VERSION "1.11.2"

NS_ :

BS_:

BU_: TCU BRK ESP MCU RDD GP TMS GW KPD1 RDE FNR ECU KPD2 ATSGO ACU IMU1 IMU2 IMU3 IMU4 IMU5 AGW PMI HDOQS EGOQS OBC EEC CBSW EJRH EJLH EPDLT EPDL2 EPDLR EPDLA TRBDZ ECU1 CLST LC510 EGDL JS SMB KPAC ACCU Audio TGU RDRR RDLH RDRH AVM CHMSL CTC SMK EVC MCU2 PHM MC3D AMBLMP RCTGU RDU PT3D XCU can1 can2

BO_ 2566907937 MCU_MCI: 250 MCU
 SG_ RhJoyBtnAux12AddSetConfig : 34|2@1+ (1,0) [0|3] "" Vector__XXX
 SG_ HeavyAttConfig : 32|2@1+ (1,0) [0|3] "" Vector__XXX
 SG_ IdleSpdSetConfig : 30|2@1+ (1,0) [0|3] "" Vector__XXX
 SG_ SdkParallelLiftConfig : 28|2@1+ (1,0) [0|3] "" Vector__XXX
 SG_ RsvforVdk10W : 26|2@1+ (1,0) [0|3] "" Vector__XXX
 SG_ BrkOprgTmLmConfigforVccC4 : 24|2@1+ (1,0) [0|3] "" Vector__XXX
 SG_ ElectStrThmbwhlConfig : 22|2@1+ (1,0) [0|3] "" Vector__XXX
 SG_ EmgStrConfig : 20|2@1+ (1,0) [0|3] "" Vector__XXX
 SG_ LongLifeEgOilFiltConfig : 18|2@1+ (1,0) [0|3] "" Vector__XXX
 SG_ ElecStrJoyThwConf : 16|2@1+ (1,0) [0|3] "" Vector__XXX
 SG_ Dl06EgFuelEffCalbConf : 14|2@1+ (1,0) [0|3] "" Vector__XXX
 SG_ RttThwDirConf : 12|2@1+ (1,0) [0|3] "" Vector__XXX
 SG_ TwThwDirConf : 10|2@1+ (1,0) [0|3] "" Vector__XXX
 SG_ CanPdlIntChngConf : 8|2@1+ (1,0) [0|3] "" Vector__XXX
 SG_ TrvlSwgAlmIntChngConf : 6|2@1+ (1,0) [0|3] "" Vector__XXX
 SG_ OprHrTmpIntChngConf : 4|2@1+ (1,0) [0|3] "" Vector__XXX
 SG_ QckCouplerIntChngConf : 2|2@1+ (1,0) [0|3] "" Vector__XXX
 SG_ ThwSensConf : 1|1@1+ (1,0) [0|1] "" Vector__XXX
 SG_ MultiFuncJoyBtnConf : 0|1@1+ (1,0) [0|1] "" Vector__XXX

BO_ 2566908449 MCU_MWIG: 250 MCU
 SG_ TiltRttArg : 62|2@1+ (1,0) [0|3] "" Vector__XXX
 SG_ GnssSt : 58|4@1+ (1,0) [0|15] "" Vector__XXX
 SG_ VhcStFineSwgTprDsb : 56|2@1+ (1,0) [0|3] "" Vector__XXX
 SG_ IndSymbolMcTprRlsSt : 54|2@1+ (1,0) [0|3] "" Vector__XXX
 SG_ EfenceTgSetSideWallR : 52|2@1- (1,-32000) [-32000|32255] "mm" Vector__XXX
 SG_ EfenceWarnSideWallR : 50|2@1- (1,-32000) [-32000|32255] "mm" Vector__XXX
 SG_ EfenceWarnSideWallL : 48|2@1+ (1,0) [0|3] "" Vector__XXX
 SG_ AssitSwgRh : 46|2@1+ (1,0) [0|3] "" Vector__XXX
 SG_ AssitSwgLh : 44|2@1+ (1,0) [0|3] "" Vector__XXX
 SG_ AssitBck : 42|2@1+ (1,0) [0|3] "" Vector__XXX
 SG_ AssitGrd : 40|2@1+ (1,0) [0|3] "" Vector__XXX
 SG_ SafeWrkSideFar : 36|2@1+ (1,0) [0|3] "" Vector__XXX
 SG_ SafeWrkSideMid : 34|2@1+ (1,0) [0|3] "" Vector__XXX
 SG_ SafeWrkSideNear : 32|2@1+ (1,0) [0|3] "" Vector__XXX
 SG_ SafeWrkFrFar : 28|2@1+ (1,0) [0|3] "" Vector__XXX
 SG_ SafeWrkFrMid : 26|2@1+ (1,0) [0|3] "" Vector__XXX
 SG_ SafeWrkFrNear : 24|2@1+ (1,0) [0|3] "" Vector__XXX
 SG_ FrMvGuidArmOut : 22|2@1+ (1,0) [0|3] "" Vector__XXX
 SG_ FrMvGuidArmIn : 20|2@1+ (1,0) [0|3] "" Vector__XXX
 SG_ FrMvGuidBoomDn : 18|2@1+ (1,0) [0|3] "" Vector__XXX
 SG_ FrMvGuidBoomUp : 16|2@1+ (1,0) [0|3] "" Vector__XXX
 SG_ EfenceTrkWrn : 14|2@1+ (1,0) [0|3] "" Vector__XXX
 SG_ EfenceDzWrn : 12|2@1+ (1,0) [0|3] "" Vector__XXX
 SG_ EfenceCabWrn : 10|2@1+ (1,0) [0|3] "" Vector__XXX
 SG_ EfenceFSwgRhWrn : 8|2@1+ (1,0) [0|3] "" Vector__XXX
 SG_ EfenceFSwgLhWrn : 6|2@1+ (1,0) [0|3] "" Vector__XXX
 SG_ EfenceCeilWrn : 4|2@1+ (1,0) [0|3] "" Vector__XXX
 SG_ EfenceFloorWrn : 2|2@1+ (1,0) [0|3] "" Vector__XXX
 SG_ EfenceWallWrn : 0|2@1+ (1,0) [0|3] "" Vector__XXX

BO_ 2566908705 MCU_TWG: 250 MCU
 SG_ TipOffMnSt : 60|4@1+ (1,0) [0|15] "" Vector__XXX
 SG_ TipOffAstSt : 56|4@1+ (1,0) [0|15] "" Vector__XXX
 SG_ TotWhgCurTrk : 40|16@1+ (2,0) [0|128510] "kg" Vector__XXX
 SG_ BckCntCurTrk : 24|16@1+ (1,0) [0|65535] "count" Vector__XXX
 SG_ WghCntSt : 20|2@1+ (1,0) [0|3] "" Vector__XXX
 SG_ WghSt : 16|4@1+ (1,0) [0|15] "" Vector__XXX
 SG_ RelTmBckWhg : 0|16@1+ (2,0) [0|128510] "kg" Vector__XXX

BO_ 2566908961 MCU_WCPR: 250 MCU
 SG_ EmcvCalbStep : 44|4@1+ (1,0) [0|15] "" Vector__XXX
 SG_ EmcvCalbStage : 40|4@1+ (1,0) [0|15] "" Vector__XXX
 SG_ BckSingleFastCalbStep : 36|4@1+ (1,0) [0|15] "" Vector__XXX
 SG_ BckSingleFastCalbStage : 32|4@1+ (1,0) [0|15] "" Vector__XXX
 SG_ BckSingleSlowCalbStep : 28|4@1+ (1,0) [0|15] "" Vector__XXX
 SG_ BckSingleSlowCalbStage : 24|4@1+ (1,0) [0|15] "" Vector__XXX
 SG_ BckZeroCalbStep : 20|4@1+ (1,0) [0|15] "" Vector__XXX
 SG_ BckZeroCalbStage : 16|4@1+ (1,0) [0|15] "" Vector__XXX
 SG_ FrMultiCalbStep : 12|4@1+ (1,0) [0|15] "" Vector__XXX
 SG_ FrMultiCalbStage : 8|4@1+ (1,0) [0|15] "" Vector__XXX
 SG_ FrSngCalbStep : 4|4@1+ (1,0) [0|15] "" Vector__XXX
 SG_ FrSngCalbStage : 0|4@1+ (1,0) [0|15] "" Vector__XXX

BO_ 2566909217 MCU_WCCV: 250 MCU
 SG_ TgtArmCylSpdUpLmt : 40|8@1+ (0.1,0) [0|20] "mmps" Vector__XXX
 SG_ TgtArmCylSpdLwLmt : 32|8@1+ (0.1,0) [0|20] "mmps" Vector__XXX
 SG_ CurArmCylSpd : 24|8@1+ (0.1,0) [0|20] "mmps" Vector__XXX
 SG_ TgtBoomCylSpdUpLmt : 16|8@1+ (0.1,0) [0|20] "mmps" Vector__XXX
 SG_ TgtBoomCylSpdLwLmt : 8|8@1+ (0.1,0) [0|20] "mmps" Vector__XXX
 SG_ CurBoomCylSpd : 0|8@1+ (0.1,0) [0|20] "mmps" Vector__XXX

BO_ 2566909473 MCU_WCJA: 250 MCU
 SG_ TgtArmJointAngEndPos : 40|8@1- (1,-125) [-125|125] "deg" Vector__XXX
 SG_ TgtArmJointAngStartPos : 32|8@1- (1,-125) [-125|125] "deg" Vector__XXX
 SG_ CurArmJointAng : 24|8@1- (1,-125) [-125|125] "deg" Vector__XXX
 SG_ TgtBoomJointAngEndPos : 16|8@1- (1,-125) [-125|125] "deg" Vector__XXX
 SG_ TgtBoomJointAngStartPos : 8|8@1- (1,-125) [-125|125] "deg" Vector__XXX
 SG_ CurBoomJointAng : 0|8@1- (1,-125) [-125|125] "deg" Vector__XXX

BO_ 2566909729 MCU_LADG: 250 MCU
 SG_ Reach : 48|16@1- (1,-32000) [-32000|32255] "mm" Vector__XXX
 SG_ Hight : 32|16@1- (1,-32000) [-32000|32255] "mm" Vector__XXX
 SG_ RatedLoad : 16|16@1+ (2,0) [0|128510] "kg" Vector__XXX
 SG_ ActLoad : 0|16@1+ (2,0) [0|128510] "kg" Vector__XXX

BO_ 2634018819 TCU_TCUID: 8 TCU

BO_ 2566910241 MCU_ASRG: 250 MCU
 SG_ VhcSpdHhRes : 40|16@1+ (0.00390625,0) [0|250.99609375] "km/h" Vector__XXX
 SG_ SwgSt : 32|2@1+ (1,0) [0|3] "" Vector__XXX
 SG_ VhcSpdFromSpdSs : 24|8@1+ (1,0) [0|250] "kmph" Vector__XXX
 SG_ SwgAng : 0|24@1- (3.0517578125E-05,-250) [-250|252] "deg" Vector__XXX

BO_ 2566910534 EVC_ETCCMVCU: 9 EVC

BO_ 2566912289 MCU_MWHG4: 138 MCU
 SG_ SsOfsRttAng : 1088|16@1- (0.0078125,-200) [-200|301.99] "deg" Vector__XXX
 SG_ ImuSsOfsTrttTiltAng : 1072|16@1- (0.0078125,-200) [-200|301.99] "deg" Vector__XXX
 SG_ TrttBodyDmsnTQ4 : 1056|16@1+ (1,0) [0|64255] "mm" Vector__XXX
 SG_ TrttBodyDmsnDQ4 : 1040|16@1+ (1,0) [0|64255] "mm" Vector__XXX
 SG_ TrttBodyDmsnAngGdt : 1016|24@1- (3.0517578125E-05,-250) [-250|252] "deg" Vector__XXX
 SG_ TrttBodyDmsnDT : 1000|16@1+ (1,0) [0|64255] "mm" Vector__XXX
 SG_ TrttBodyDmsnGT : 984|16@1+ (1,0) [0|64255] "mm" Vector__XXX
 SG_ TrttBodyDmsnDG : 968|16@1+ (1,0) [0|64255] "mm" Vector__XXX
 SG_ TrttBodyDmsnVW : 952|16@1+ (1,0) [0|64255] "mm" Vector__XXX
 SG_ TrttBodyDmsnUV : 936|16@1+ (1,0) [0|64255] "mm" Vector__XXX
 SG_ TrttBodyDmsnTU : 920|16@1+ (1,0) [0|64255] "mm" Vector__XXX
 SG_ TrttBck05DmsnAngVwn : 896|24@1- (3.0517578125E-05,-250) [-250|252] "deg" Vector__XXX
 SG_ TrttBck05DmsnTN : 880|16@1+ (1,0) [0|64255] "mm" Vector__XXX
 SG_ TrttBck05DmsnWN : 864|16@1+ (1,0) [0|64255] "mm" Vector__XXX
 SG_ TrttBck05DmsnWT : 848|16@1+ (1,0) [0|64255] "mm" Vector__XXX
 SG_ TrttBck05DmsnNQ3 : 832|16@1+ (1,0) [0|64255] "mm" Vector__XXX
 SG_ TrttBck05DmsnWQ3 : 816|16@1+ (1,0) [0|64255] "mm" Vector__XXX
 SG_ TrttBck05DmsnNQ2 : 800|16@1+ (1,0) [0|64255] "mm" Vector__XXX
 SG_ TrttBck05DmsnWQ2 : 784|16@1+ (1,0) [0|64255] "mm" Vector__XXX
 SG_ TrttBck05DmsnWidth : 768|16@1+ (1,0) [0|64255] "mm" Vector__XXX
 SG_ TrttBck05DmsnNQ1 : 752|16@1+ (1,0) [0|64255] "mm" Vector__XXX
 SG_ TrttBck05DmsnWQ1 : 736|16@1+ (1,0) [0|64255] "mm" Vector__XXX
 SG_ TrttBck04DmsnAngVwn : 712|24@1- (3.0517578125E-05,-250) [-250|252] "deg" Vector__XXX
 SG_ TrttBck04DmsnTN : 696|16@1+ (1,0) [0|64255] "mm" Vector__XXX
 SG_ TrttBck04DmsnWN : 680|16@1+ (1,0) [0|64255] "mm" Vector__XXX
 SG_ TrttBck04DmsnWT : 664|16@1+ (1,0) [0|64255] "mm" Vector__XXX
 SG_ TrttBck04DmsnNQ3 : 648|16@1+ (1,0) [0|64255] "mm" Vector__XXX
 SG_ TrttBck04DmsnWQ3 : 632|16@1+ (1,0) [0|64255] "mm" Vector__XXX
 SG_ TrttBck04DmsnNQ2 : 616|16@1+ (1,0) [0|64255] "mm" Vector__XXX
 SG_ TrttBck04DmsnWQ2 : 600|16@1+ (1,0) [0|64255] "mm" Vector__XXX
 SG_ TrttBck04DmsnWidth : 584|16@1+ (1,0) [0|64255] "mm" Vector__XXX
 SG_ TrttBck04DmsnNQ1 : 568|16@1+ (1,0) [0|64255] "mm" Vector__XXX
 SG_ TrttBck04DmsnWQ1 : 552|16@1+ (1,0) [0|64255] "mm" Vector__XXX
 SG_ TrttBck03DmsnAngVwn : 528|24@1- (3.0517578125E-05,-250) [-250|252] "deg" Vector__XXX
 SG_ TrttBck03DmsnTN : 512|16@1+ (1,0) [0|64255] "mm" Vector__XXX
 SG_ TrttBck03DmsnWN : 496|16@1+ (1,0) [0|64255] "mm" Vector__XXX
 SG_ TrttBck03DmsnWT : 480|16@1+ (1,0) [0|64255] "mm" Vector__XXX
 SG_ TrttBck03DmsnNQ3 : 464|16@1+ (1,0) [0|64255] "mm" Vector__XXX
 SG_ TrttBck03DmsnWQ3 : 448|16@1+ (1,0) [0|64255] "mm" Vector__XXX
 SG_ TrttBck03DmsnNQ2 : 432|16@1+ (1,0) [0|64255] "mm" Vector__XXX
 SG_ TrttBck03DmsnWQ2 : 416|16@1+ (1,0) [0|64255] "mm" Vector__XXX
 SG_ TrttBck03DmsnWidth : 400|16@1+ (1,0) [0|64255] "mm" Vector__XXX
 SG_ TrttBck03DmsnNQ1 : 384|16@1+ (1,0) [0|64255] "mm" Vector__XXX
 SG_ TrttBck03DmsnWQ1 : 368|16@1+ (1,0) [0|64255] "mm" Vector__XXX
 SG_ TrttBck02DmsnAngVwn : 344|24@1- (3.0517578125E-05,-250) [-250|252] "deg" Vector__XXX
 SG_ TrttBck02DmsnTN : 328|16@1+ (1,0) [0|64255] "mm" Vector__XXX
 SG_ TrttBck02DmsnWN : 312|16@1+ (1,0) [0|64255] "mm" Vector__XXX
 SG_ TrttBck02DmsnWT : 296|16@1+ (1,0) [0|64255] "mm" Vector__XXX
 SG_ TrttBck02DmsnNQ3 : 280|16@1+ (1,0) [0|64255] "mm" Vector__XXX
 SG_ TrttBck02DmsnWQ3 : 264|16@1+ (1,0) [0|64255] "mm" Vector__XXX
 SG_ TrttBck02DmsnNQ2 : 248|16@1+ (1,0) [0|64255] "mm" Vector__XXX
 SG_ TrttBck02DmsnWQ2 : 232|16@1+ (1,0) [0|64255] "mm" Vector__XXX
 SG_ TrttBck02DmsnWidth : 216|16@1+ (1,0) [0|64255] "mm" Vector__XXX
 SG_ TrttBck02DmsnNQ1 : 200|16@1+ (1,0) [0|64255] "mm" Vector__XXX
 SG_ TrttBck02DmsnWQ1 : 184|16@1+ (1,0) [0|64255] "mm" Vector__XXX
 SG_ TrttBck01DmsnAngVwn : 160|24@1- (3.0517578125E-05,-250) [-250|252] "deg" Vector__XXX
 SG_ TrttBck01DmsnTN : 144|16@1+ (1,0) [0|64255] "mm" Vector__XXX
 SG_ TrttBck01DmsnWN : 128|16@1+ (1,0) [0|64255] "mm" Vector__XXX
 SG_ TrttBck01DmsnWT : 112|16@1+ (1,0) [0|64255] "mm" Vector__XXX
 SG_ TrttBck01DmsnNQ3 : 96|16@1+ (1,0) [0|64255] "mm" Vector__XXX
 SG_ TrttBck01DmsnWQ3 : 80|16@1+ (1,0) [0|64255] "mm" Vector__XXX
 SG_ TrttBck01DmsnNQ2 : 64|16@1+ (1,0) [0|64255] "mm" Vector__XXX
 SG_ TrttBck01DmsnWQ2 : 48|16@1+ (1,0) [0|64255] "mm" Vector__XXX
 SG_ TrttBck01DmsnWidth : 32|16@1+ (1,0) [0|64255] "mm" Vector__XXX
 SG_ TrttBck01DmsnNQ1 : 16|16@1+ (1,0) [0|64255] "mm" Vector__XXX
 SG_ TrttBck01DmsnWQ1 : 0|16@1+ (1,0) [0|64255] "mm" Vector__XXX

BO_ 2566912545 MCU_MWHG1: 125 MCU
 SG_ Bck05DmsnAngGdn : 976|24@1- (3.0517578125E-05,-250) [-250|252] "deg" Vector__XXX
 SG_ Bck05DmsnDT : 960|16@1+ (1,0) [0|64255] "mm" Vector__XXX
 SG_ Bck05DmsnNQ3 : 944|16@1+ (1,0) [0|64255] "mm" Vector__XXX
 SG_ Bck05DmsnDQ3 : 928|16@1+ (1,0) [0|64255] "mm" Vector__XXX
 SG_ Bck05DmsnNQ2 : 912|16@1+ (1,0) [0|64255] "mm" Vector__XXX
 SG_ Bck05DmsnDQ2 : 896|16@1+ (1,0) [0|64255] "mm" Vector__XXX
 SG_ Bck05DmsnTN : 880|16@1+ (1,0) [0|64255] "mm" Vector__XXX
 SG_ Bck05DmsnWidth : 864|16@1+ (1,0) [0|64255] "mm" Vector__XXX
 SG_ Bck05DmsnNQ1 : 848|16@1+ (1,0) [0|64255] "mm" Vector__XXX
 SG_ Bck05DmsnDQ1 : 832|16@1+ (1,0) [0|64255] "mm" Vector__XXX
 SG_ Bck05DmsnDN : 816|16@1+ (1,0) [0|64255] "mm" Vector__XXX
 SG_ Bck05DmsnDG : 800|16@1+ (1,0) [0|64255] "mm" Vector__XXX
 SG_ Bck04DmsnAngGdn : 776|24@1- (3.0517578125E-05,-250) [-250|252] "deg" Vector__XXX
 SG_ Bck04DmsnDT : 760|16@1+ (1,0) [0|64255] "mm" Vector__XXX
 SG_ Bck04DmsnNQ3 : 744|16@1+ (1,0) [0|64255] "mm" Vector__XXX
 SG_ Bck04DmsnDQ3 : 728|16@1+ (1,0) [0|64255] "mm" Vector__XXX
 SG_ Bck04DmsnNQ2 : 712|16@1+ (1,0) [0|64255] "mm" Vector__XXX
 SG_ Bck04DmsnDQ2 : 696|16@1+ (1,0) [0|64255] "mm" Vector__XXX
 SG_ Bck04DmsnTN : 680|16@1+ (1,0) [0|64255] "mm" Vector__XXX
 SG_ Bck04DmsnWidth : 664|16@1+ (1,0) [0|64255] "mm" Vector__XXX
 SG_ Bck04DmsnNQ1 : 648|16@1+ (1,0) [0|64255] "mm" Vector__XXX
 SG_ Bck04DmsnDQ1 : 632|16@1+ (1,0) [0|64255] "mm" Vector__XXX
 SG_ Bck04DmsnDN : 616|16@1+ (1,0) [0|64255] "mm" Vector__XXX
 SG_ Bck04DmsnDG : 600|16@1+ (1,0) [0|64255] "mm" Vector__XXX
 SG_ Bck03DmsnAngGdn : 576|24@1- (3.0517578125E-05,-250) [-250|252] "deg" Vector__XXX
 SG_ Bck03DmsnDT : 560|16@1+ (1,0) [0|64255] "mm" Vector__XXX
 SG_ Bck03DmsnNQ3 : 544|16@1+ (1,0) [0|64255] "mm" Vector__XXX
 SG_ Bck03DmsnDQ3 : 528|16@1+ (1,0) [0|64255] "mm" Vector__XXX
 SG_ Bck03DmsnNQ2 : 512|16@1+ (1,0) [0|64255] "mm" Vector__XXX
 SG_ Bck03DmsnDQ2 : 496|16@1+ (1,0) [0|64255] "mm" Vector__XXX
 SG_ Bck03DmsnTN : 480|16@1+ (1,0) [0|64255] "mm" Vector__XXX
 SG_ Bck03DmsnWidth : 464|16@1+ (1,0) [0|64255] "mm" Vector__XXX
 SG_ Bck03DmsnNQ1 : 448|16@1+ (1,0) [0|64255] "mm" Vector__XXX
 SG_ Bck03DmsnDQ1 : 432|16@1+ (1,0) [0|64255] "mm" Vector__XXX
 SG_ Bck03DmsnDN : 416|16@1+ (1,0) [0|64255] "mm" Vector__XXX
 SG_ Bck03DmsnDG : 400|16@1+ (1,0) [0|64255] "mm" Vector__XXX
 SG_ Bck02DmsnAngGdn : 376|24@1- (3.0517578125E-05,-250) [-250|252] "deg" Vector__XXX
 SG_ Bck02DmsnDT : 360|16@1+ (1,0) [0|64255] "mm" Vector__XXX
 SG_ Bck02DmsnNQ3 : 344|16@1+ (1,0) [0|64255] "mm" Vector__XXX
 SG_ Bck02DmsnDQ3 : 328|16@1+ (1,0) [0|64255] "mm" Vector__XXX
 SG_ Bck02DmsnNQ2 : 312|16@1+ (1,0) [0|64255] "mm" Vector__XXX
 SG_ Bck02DmsnDQ2 : 296|16@1+ (1,0) [0|64255] "mm" Vector__XXX
 SG_ Bck02DmsnTN : 280|16@1+ (1,0) [0|64255] "mm" Vector__XXX
 SG_ Bck02DmsnWidth : 264|16@1+ (1,0) [0|64255] "mm" Vector__XXX
 SG_ Bck02DmsnNQ1 : 248|16@1+ (1,0) [0|64255] "mm" Vector__XXX
 SG_ Bck02DmsnDQ1 : 232|16@1+ (1,0) [0|64255] "mm" Vector__XXX
 SG_ Bck02DmsnDN : 216|16@1+ (1,0) [0|64255] "mm" Vector__XXX
 SG_ Bck02DmsnDG : 200|16@1+ (1,0) [0|64255] "mm" Vector__XXX
 SG_ Bck01DmsnAngGdn : 176|24@1- (3.0517578125E-05,-250) [-250|252] "deg" Vector__XXX
 SG_ Bck01DmsnDT : 160|16@1+ (1,0) [0|64255] "mm" Vector__XXX
 SG_ Bck01DmsnNQ3 : 144|16@1+ (1,0) [0|64255] "mm" Vector__XXX
 SG_ Bck01DmsnDQ3 : 128|16@1+ (1,0) [0|64255] "mm" Vector__XXX
 SG_ Bck01DmsnNQ2 : 112|16@1+ (1,0) [0|64255] "mm" Vector__XXX
 SG_ Bck01DmsnDQ2 : 96|16@1+ (1,0) [0|64255] "mm" Vector__XXX
 SG_ Bck01DmsnTN : 80|16@1+ (1,0) [0|64255] "mm" Vector__XXX
 SG_ Bck01DmsnWidth : 64|16@1+ (1,0) [0|64255] "mm" Vector__XXX
 SG_ Bck01DmsnNQ1 : 48|16@1+ (1,0) [0|64255] "mm" Vector__XXX
 SG_ Bck01DmsnDQ1 : 32|16@1+ (1,0) [0|64255] "mm" Vector__XXX
 SG_ Bck01DmsnDN : 16|16@1+ (1,0) [0|64255] "mm" Vector__XXX
 SG_ Bck01DmsnDG : 0|16@1+ (1,0) [0|64255] "mm" Vector__XXX

BO_ 2566912801 MCU_MWHG2: 118 MCU
 SG_ JoyFuncAssnRhBtn14 : 936|8@1+ (1,0) [0|255] "" Vector__XXX
 SG_ JoyFuncAssnRhBtn13 : 928|8@1+ (1,0) [0|255] "" Vector__XXX
 SG_ JoyFuncAssnRhBtn12 : 920|8@1+ (1,0) [0|255] "" Vector__XXX
 SG_ JoyFuncAssnRhBtn11 : 912|8@1+ (1,0) [0|255] "" Vector__XXX
 SG_ JoyFuncAssnLhBtn14 : 904|8@1+ (1,0) [0|255] "" Vector__XXX
 SG_ JoyFuncAssnLhBtn13 : 896|8@1+ (1,0) [0|255] "" Vector__XXX
 SG_ JoyFuncAssnLhBtn12 : 888|8@1+ (1,0) [0|255] "" Vector__XXX
 SG_ JoyFuncAssnLhBtn11 : 880|8@1+ (1,0) [0|255] "" Vector__XXX
 SG_ DacCoordinateSystem : 874|2@1+ (1,0) [0|3] "" Vector__XXX
 SG_ DacAutoMdSelect : 872|2@1+ (1,0) [0|3] "" Vector__XXX
 SG_ CrwTipCalbLen : 856|16@1+ (1,0) [0|64255] "mm" Vector__XXX
 SG_ ImuSsOfsBladeRoll : 832|24@1- (3.0517578125E-05,-250) [-250|252] "deg" Vector__XXX
 SG_ ImuSsOfsBladePch : 808|24@1- (3.0517578125E-05,-250) [-250|252] "deg" Vector__XXX
 SG_ ImuSsOfsCfrmRoll : 784|24@1- (3.0517578125E-05,-250) [-250|252] "deg" Vector__XXX
 SG_ ImuSsOfsCfrmPch : 760|24@1- (3.0517578125E-05,-250) [-250|252] "deg" Vector__XXX
 SG_ BladeTipCalbLen : 744|16@1+ (1,0) [0|64255] "mm" Vector__XXX
 SG_ BladeJointCalbLen : 728|16@1+ (1,0) [0|64255] "mm" Vector__XXX
 SG_ GrdAstPrfDsnDt01PntZ09 : 712|16@1- (1,-32000) [-32000|32255] "mm" Vector__XXX
 SG_ GrdAstPrfDsnDt01PntY09 : 696|16@1- (1,-32000) [-32000|32255] "mm" Vector__XXX
 SG_ GrdAstPrfDsnDt01PntZ08 : 680|16@1- (1,-32000) [-32000|32255] "mm" Vector__XXX
 SG_ GrdAstPrfDsnDt01PntY08 : 664|16@1- (1,-32000) [-32000|32255] "mm" Vector__XXX
 SG_ GrdAstPrfDsnDt01PntZ07 : 648|16@1- (1,-32000) [-32000|32255] "mm" Vector__XXX
 SG_ GrdAstPrfDsnDt01PntY07 : 632|16@1- (1,-32000) [-32000|32255] "mm" Vector__XXX
 SG_ GrdAstPrfDsnDt01PntZ06 : 616|16@1- (1,-32000) [-32000|32255] "mm" Vector__XXX
 SG_ GrdAstPrfDsnDt01PntY06 : 600|16@1- (1,-32000) [-32000|32255] "mm" Vector__XXX
 SG_ GrdAstPrfDsnDt01PntZ05 : 584|16@1- (1,-32000) [-32000|32255] "mm" Vector__XXX
 SG_ GrdAstPrfDsnDt01PntY05 : 568|16@1- (1,-32000) [-32000|32255] "mm" Vector__XXX
 SG_ GrdAstPrfDsnDt01PntZ04 : 552|16@1- (1,-32000) [-32000|32255] "mm" Vector__XXX
 SG_ GrdAstPrfDsnDt01PntY04 : 536|16@1- (1,-32000) [-32000|32255] "mm" Vector__XXX
 SG_ GrdAstPrfDsnDt01PntZ03 : 520|16@1- (1,-32000) [-32000|32255] "mm" Vector__XXX
 SG_ GrdAstPrfDsnDt01PntY03 : 504|16@1- (1,-32000) [-32000|32255] "mm" Vector__XXX
 SG_ GrdAstPrfDsnDt01PntZ02 : 488|16@1- (1,-32000) [-32000|32255] "mm" Vector__XXX
 SG_ GrdAstPrfDsnDt01PntY02 : 472|16@1- (1,-32000) [-32000|32255] "mm" Vector__XXX
 SG_ GrdAstPrfDsnDt01PntZ01 : 456|16@1- (1,-32000) [-32000|32255] "mm" Vector__XXX
 SG_ GrdAstPrfDsnDt01PntY01 : 440|16@1- (1,-32000) [-32000|32255] "mm" Vector__XXX
 SG_ CrossSlopeDsnDt : 424|16@1- (0.0078125,-251) [-251|250.99] "percent" Vector__XXX
 SG_ SlopeDsnDt : 408|16@1- (0.0078125,-251) [-251|250.99] "percent" Vector__XXX
 SG_ DepthDsnDt : 392|16@1+ (1,0) [0|64255] "mm" Vector__XXX
 SG_ JoyFuncAssnRhThw05 : 384|8@1+ (1,0) [0|255] "" Vector__XXX
 SG_ JoyFuncAssnRhThw04 : 376|8@1+ (1,0) [0|255] "" Vector__XXX
 SG_ JoyFuncAssnRhThw03 : 368|8@1+ (1,0) [0|255] "" Vector__XXX
 SG_ JoyFuncAssnRhThw02 : 360|8@1+ (1,0) [0|255] "" Vector__XXX
 SG_ JoyFuncAssnRhThw01 : 352|8@1+ (1,0) [0|255] "" Vector__XXX
 SG_ JoyFuncAssnLhThw05 : 344|8@1+ (1,0) [0|255] "" Vector__XXX
 SG_ JoyFuncAssnLhThw04 : 336|8@1+ (1,0) [0|255] "" Vector__XXX
 SG_ JoyFuncAssnLhThw03 : 328|8@1+ (1,0) [0|255] "" Vector__XXX
 SG_ JoyFuncAssnLhThw02 : 320|8@1+ (1,0) [0|255] "" Vector__XXX
 SG_ JoyFuncAssnLhThw01 : 312|8@1+ (1,0) [0|255] "" Vector__XXX
 SG_ JoyFuncAssnRhBtn10 : 304|8@1+ (1,0) [0|255] "" Vector__XXX
 SG_ JoyFuncAssnRhBtn09 : 296|8@1+ (1,0) [0|255] "" Vector__XXX
 SG_ JoyFuncAssnRhBtn08 : 288|8@1+ (1,0) [0|255] "" Vector__XXX
 SG_ JoyFuncAssnRhBtn07 : 280|8@1+ (1,0) [0|255] "" Vector__XXX
 SG_ JoyFuncAssnRhBtn06 : 272|8@1+ (1,0) [0|255] "" Vector__XXX
 SG_ JoyFuncAssnRhBtn05 : 264|8@1+ (1,0) [0|255] "" Vector__XXX
 SG_ JoyFuncAssnRhBtn04 : 256|8@1+ (1,0) [0|255] "" Vector__XXX
 SG_ JoyFuncAssnRhBtn03 : 248|8@1+ (1,0) [0|255] "" Vector__XXX
 SG_ JoyFuncAssnRhBtn02 : 240|8@1+ (1,0) [0|255] "" Vector__XXX
 SG_ JoyFuncAssnRhBtn01 : 232|8@1+ (1,0) [0|255] "" Vector__XXX
 SG_ JoyFuncAssnLhBtn10 : 224|8@1+ (1,0) [0|255] "" Vector__XXX
 SG_ JoyFuncAssnLhBtn09 : 216|8@1+ (1,0) [0|255] "" Vector__XXX
 SG_ JoyFuncAssnLhBtn08 : 208|8@1+ (1,0) [0|255] "" Vector__XXX
 SG_ JoyFuncAssnLhBtn07 : 200|8@1+ (1,0) [0|255] "" Vector__XXX
 SG_ JoyFuncAssnLhBtn06 : 192|8@1+ (1,0) [0|255] "" Vector__XXX
 SG_ JoyFuncAssnLhBtn05 : 184|8@1+ (1,0) [0|255] "" Vector__XXX
 SG_ JoyFuncAssnLhBtn04 : 176|8@1+ (1,0) [0|255] "" Vector__XXX
 SG_ JoyFuncAssnLhBtn03 : 168|8@1+ (1,0) [0|255] "" Vector__XXX
 SG_ JoyFuncAssnLhBtn02 : 160|8@1+ (1,0) [0|255] "" Vector__XXX
 SG_ JoyFuncAssnLhBtn01 : 152|8@1+ (1,0) [0|255] "" Vector__XXX
 SG_ ImuSsOfsBucket : 128|24@1- (3.0517578125E-05,-250) [-250|252] "deg" Vector__XXX
 SG_ ImuSsOfsArtiArmPch : 104|24@1- (3.0517578125E-05,-250) [-250|252] "deg" Vector__XXX
 SG_ ImuSsOfsArmPch : 80|24@1- (3.0517578125E-05,-250) [-250|252] "deg" Vector__XXX
 SG_ ImuSsOfsBoomPch : 56|24@1- (3.0517578125E-05,-250) [-250|252] "deg" Vector__XXX
 SG_ ImuSsOfsBodyRoll : 32|24@1- (3.0517578125E-05,-250) [-250|252] "deg" Vector__XXX
 SG_ ImuSsOfsBodyPch : 8|24@1- (3.0517578125E-05,-250) [-250|252] "deg" Vector__XXX
 SG_ SelectedBucketNo : 0|8@1+ (1,0) [0|255] "" Vector__XXX

BO_ 2566913057 MCU_MWHG3: 67 MCU
 SG_ MaterialName : 336|200@1+ (1,0) [0|255] "ASCII" Vector__XXX
 SG_ TrkName : 136|200@1+ (1,0) [0|255] "ASCII" Vector__XXX
 SG_ BchmkZOfs : 120|16@1- (1,-32000) [-32000|32255] "mm" Vector__XXX
 SG_ BchmkYOfs : 104|16@1- (1,-32000) [-32000|32255] "mm" Vector__XXX
 SG_ BchmkXOfs : 88|16@1- (1,-32000) [-32000|32255] "mm" Vector__XXX
 SG_ TrkCount : 72|16@1+ (1,0) [0|64255] "" Vector__XXX
 SG_ SelMaterialDensity : 56|16@1+ (1,0) [0|64255] "kgpm3" Vector__XXX
 SG_ SelTrkTgtWgh : 40|16@1+ (2,0) [0|128510] "kg" Vector__XXX
 SG_ BckRefPnt : 38|2@1+ (1,0) [0|3] "" Vector__XXX
 SG_ ArtiBoomDmsnOpt : 35|3@1+ (1,0) [0|7] "" Vector__XXX
 SG_ ArmDmsnOpt : 32|3@1+ (1,0) [0|7] "" Vector__XXX
 SG_ BoomDmsnOpt : 27|3@1+ (1,0) [0|7] "" Vector__XXX
 SG_ SetExcessiveDigPrt : 24|2@1+ (1,0) [0|3] "" Vector__XXX
 SG_ GrdAstMd : 20|4@1+ (1,0) [0|15] "" Vector__XXX
 SG_ GrdAstAccuracy : 16|4@1+ (1,0) [0|15] "" Vector__XXX
 SG_ TrkShoeWidth : 8|8@1+ (10,0) [0|2500] "mm" Vector__XXX

BO_ 2566913313 MCU_MWTSV: 24 MCU
 SG_ EfenceTgSetSideWallR : 176|16@1- (1,-32000) [-32000|32255] "" Vector__XXX
 SG_ EfenceTgSetSideWallL : 160|16@1- (1,-32000) [-32000|32255] "" Vector__XXX
 SG_ EfenceTgSetCabin : 144|16@1- (1,-32000) [-32000|32255] "mm" Vector__XXX
 SG_ SwgAstAngTgtSetSwgLh : 120|24@1- (3.0517578125E-05,-250) [-250|252] "deg" Vector__XXX
 SG_ SwgAstAngTgtSetSwgRh : 96|24@1- (3.0517578125E-05,-250) [-250|252] "deg" Vector__XXX
 SG_ EfenceTgtSetSwgRh : 72|24@1- (3.0517578125E-05,-250) [-250|252] "deg" Vector__XXX
 SG_ EfenceTgtSetSwgLh : 48|24@1- (3.0517578125E-05,-250) [-250|252] "deg" Vector__XXX
 SG_ EfenceTgtSetCeil : 32|16@1- (1,-32000) [-32000|32255] "mm" Vector__XXX
 SG_ EfenceTgtSetFloor : 16|16@1- (1,-32000) [-32000|32255] "mm" Vector__XXX
 SG_ EfenceTgtSetWall : 0|16@1- (1,-32000) [-32000|32255] "mm" Vector__XXX

BO_ 2566913569 MCU_MTSI: 88 MCU
 SG_ CompanyName : 504|200@1+ (1,0) [0|1.60693804425899E+60] "ASCII" Vector__XXX
 SG_ TgWghofCurTrk : 488|16@1+ (2,0) [0|128510] "kg" Vector__XXX
 SG_ TrkCntFinalTm : 456|32@1+ (1,0) [0|4211081215] "s" Vector__XXX
 SG_ MaterialLoadSt : 448|1@1+ (1,0) [0|1] "" Vector__XXX
 SG_ TotWghCurTrk : 432|16@1+ (2,0) [0|128510] "kg" Vector__XXX
 SG_ BckCntCurTrk : 416|16@1+ (1,0) [0|65535] "count" Vector__XXX
 SG_ MtrDensity : 400|16@1+ (1,0) [0|64255] "kgpm3" Vector__XXX
 SG_ MtrName : 200|200@1+ (1,0) [0|255] "ASCII" Vector__XXX
 SG_ TrkName : 0|200@1+ (1,0) [0|1.60693804425899E+60] "ASCII" Vector__XXX

BO_ 2566913825 MCU_MAWI: 250 MCU
 SG_ TotAcmtWgh : 32|32@1+ (2,0) [0|8589934590] "kg" Vector__XXX
 SG_ TotAcmtBckCnt : 0|24@1+ (1,0) [0|16777215] "count" Vector__XXX

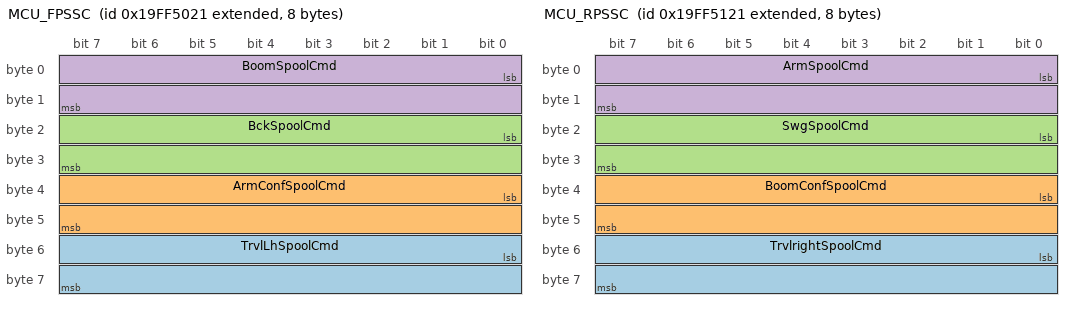
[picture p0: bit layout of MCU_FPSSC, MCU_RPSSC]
BO_ 2583646241 MCU_FPSSC: 8 MCU
 SG_ TrvlLhSpoolCmd : 48|16@1- (0.01,-20) [-20|20] "mm" Vector__XXX
 SG_ ArmConfSpoolCmd : 32|16@1- (0.01,-20) [-20|20] "mm" Vector__XXX
 SG_ BckSpoolCmd : 16|16@1- (0.01,-20) [-20|20] "mm" Vector__XXX
 SG_ BoomSpoolCmd : 0|16@1- (0.01,-20) [-20|20] "mm" Vector__XXX

BO_ 2583646497 MCU_RPSSC: 8 MCU
 SG_ TrvlrightSpoolCmd : 48|16@1- (0.01,-20) [-20|20] "mm" Vector__XXX
 SG_ BoomConfSpoolCmd : 32|16@1- (0.01,-20) [-20|20] "mm" Vector__XXX
 SG_ SwgSpoolCmd : 16|16@1- (0.01,-20) [-20|20] "mm" Vector__XXX
 SG_ ArmSpoolCmd : 0|16@1- (0.01,-20) [-20|20] "mm" Vector__XXX

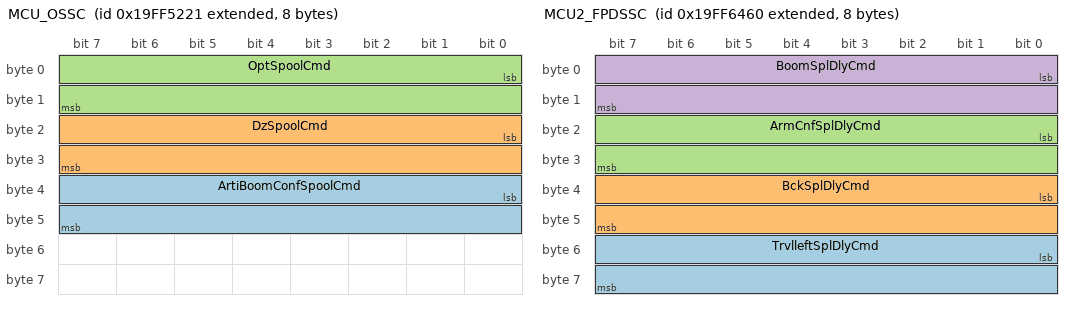
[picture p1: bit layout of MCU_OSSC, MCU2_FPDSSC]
BO_ 2583646753 MCU_OSSC: 8 MCU
 SG_ ArtiBoomConfSpoolCmd : 32|16@1- (0.01,-20) [-20|20] "mm" Vector__XXX
 SG_ DzSpoolCmd : 16|16@1- (0.01,-20) [-20|20] "mm" Vector__XXX
 SG_ OptSpoolCmd : 0|16@1- (0.01,-20) [-20|20] "mm" Vector__XXX

BO_ 2583651424 MCU2_FPDSSC: 8 MCU2
 SG_ TrvlleftSplDlyCmd : 48|16@1- (0.01,-20) [-20|20] "mm" Vector__XXX
 SG_ BckSplDlyCmd : 32|16@1- (0.01,-20) [-20|20] "mm" Vector__XXX
 SG_ ArmCnfSplDlyCmd : 16|16@1- (0.01,-20) [-20|20] "mm" Vector__XXX
 SG_ BoomSplDlyCmd : 0|16@1- (0.01,-20) [-20|20] "mm" Vector__XXX

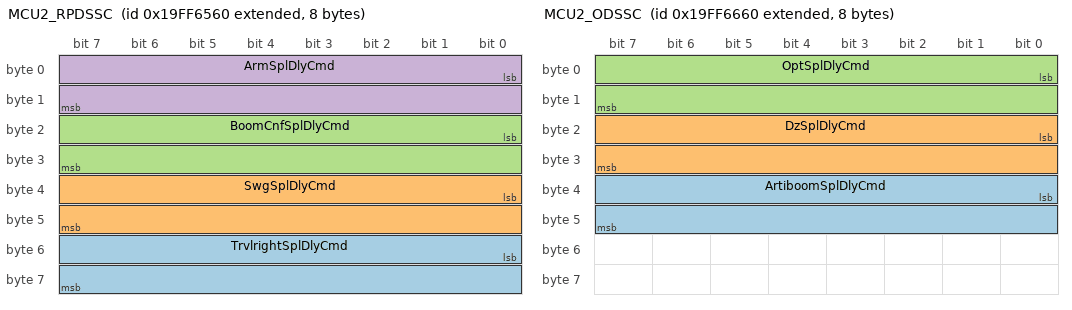
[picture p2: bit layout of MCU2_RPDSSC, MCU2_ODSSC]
BO_ 2583651680 MCU2_RPDSSC: 8 MCU2
 SG_ TrvlrightSplDlyCmd : 48|16@1- (0.01,-20) [-20|20] "mm" Vector__XXX
 SG_ SwgSplDlyCmd : 32|16@1- (0.01,-20) [-20|20] "mm" Vector__XXX
 SG_ BoomCnfSplDlyCmd : 16|16@1- (0.01,-20) [-20|20] "mm" Vector__XXX
 SG_ ArmSplDlyCmd : 0|16@1- (0.01,-20) [-20|20] "mm" Vector__XXX

BO_ 2583651936 MCU2_ODSSC: 8 MCU2
 SG_ ArtiboomSplDlyCmd : 32|16@1- (0.01,-20) [-20|20] "mm" Vector__XXX
 SG_ DzSplDlyCmd : 16|16@1- (0.01,-20) [-20|20] "mm" Vector__XXX
 SG_ OptSplDlyCmd : 0|16@1- (0.01,-20) [-20|20] "mm" Vector__XXX

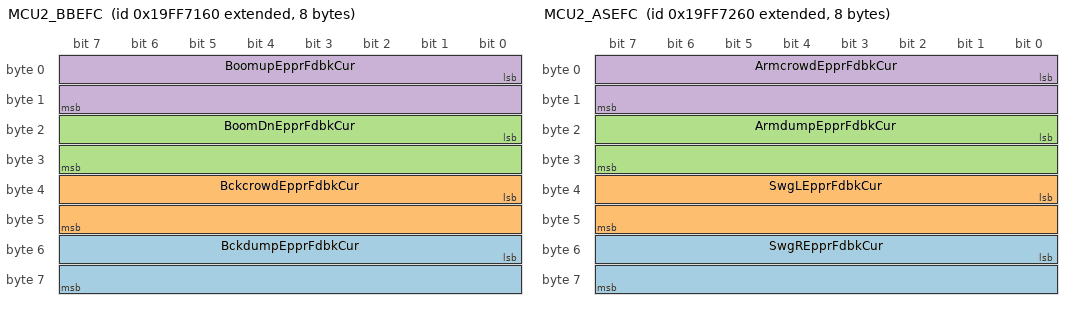
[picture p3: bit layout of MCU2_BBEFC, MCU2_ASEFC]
BO_ 2583654752 MCU2_BBEFC: 8 MCU2
 SG_ BckdumpEpprFdbkCur : 48|16@1+ (1,0) [0|1000] "mA" Vector__XXX
 SG_ BckcrowdEpprFdbkCur : 32|16@1+ (1,0) [0|1000] "mA" Vector__XXX
 SG_ BoomDnEpprFdbkCur : 16|16@1+ (1,0) [0|1000] "mA" Vector__XXX
 SG_ BoomupEpprFdbkCur : 0|16@1+ (1,0) [0|1000] "mA" Vector__XXX

BO_ 2583655008 MCU2_ASEFC: 8 MCU2
 SG_ SwgREpprFdbkCur : 48|16@1+ (1,0) [0|1000] "mA" Vector__XXX
 SG_ SwgLEpprFdbkCur : 32|16@1+ (1,0) [0|1000] "mA" Vector__XXX
 SG_ ArmdumpEpprFdbkCur : 16|16@1+ (1,0) [0|1000] "mA" Vector__XXX
 SG_ ArmcrowdEpprFdbkCur : 0|16@1+ (1,0) [0|1000] "mA" Vector__XXX

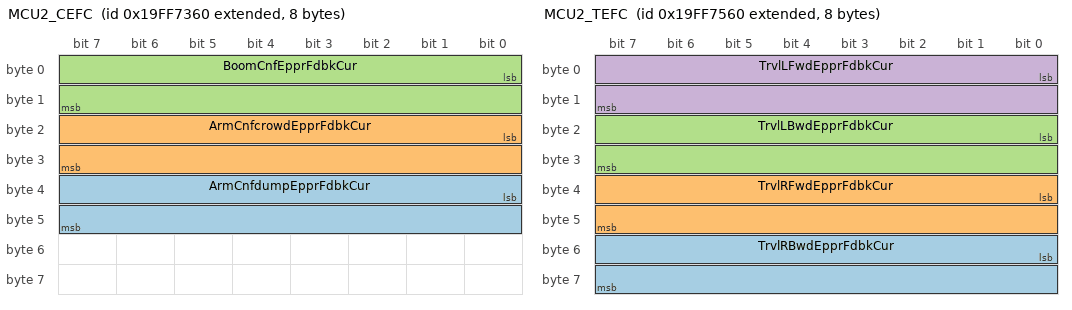
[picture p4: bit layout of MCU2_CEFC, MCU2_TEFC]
BO_ 2583655264 MCU2_CEFC: 8 MCU2
 SG_ ArmCnfdumpEpprFdbkCur : 32|16@1+ (1,0) [0|1000] "mA" Vector__XXX
 SG_ ArmCnfcrowdEpprFdbkCur : 16|16@1+ (1,0) [0|1000] "mA" Vector__XXX
 SG_ BoomCnfEpprFdbkCur : 0|16@1+ (1,0) [0|1000] "mA" Vector__XXX

BO_ 2583655520 MCU2_OEFC: 8 MCU2
 SG_ OpenEpprFdbkCur : 16|16@1+ (1,0) [0|1000] "mA" Vector__XXX
 SG_ CloseEpprFdbkCur : 0|16@1+ (1,0) [0|1000] "mA" Vector__XXX

BO_ 2583655776 MCU2_TEFC: 8 MCU2
 SG_ TrvlRBwdEpprFdbkCur : 48|16@1+ (1,0) [0|1000] "mA" Vector__XXX
 SG_ TrvlRFwdEpprFdbkCur : 32|16@1+ (1,0) [0|1000] "mA" Vector__XXX
 SG_ TrvlLBwdEpprFdbkCur : 16|16@1+ (1,0) [0|1000] "mA" Vector__XXX
 SG_ TrvlLFwdEpprFdbkCur : 0|16@1+ (1,0) [0|1000] "mA" Vector__XXX

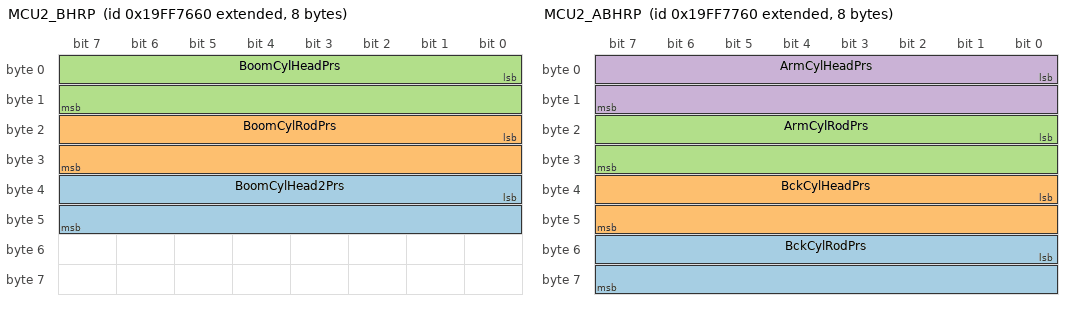
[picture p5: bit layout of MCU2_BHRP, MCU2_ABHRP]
BO_ 2583656032 MCU2_BHRP: 8 MCU2
 SG_ BoomCylHead2Prs : 32|16@1+ (0.25,0) [0|500] "bar" Vector__XXX
 SG_ BoomCylRodPrs : 16|16@1+ (0.25,0) [0|500] "bar" Vector__XXX
 SG_ BoomCylHeadPrs : 0|16@1+ (0.25,0) [0|500] "bar" Vector__XXX

BO_ 2583656288 MCU2_ABHRP: 8 MCU2
 SG_ BckCylRodPrs : 48|16@1+ (0.25,0) [0|500] "bar" Vector__XXX
 SG_ BckCylHeadPrs : 32|16@1+ (0.25,0) [0|500] "bar" Vector__XXX
 SG_ ArmCylRodPrs : 16|16@1+ (0.25,0) [0|500] "bar" Vector__XXX
 SG_ ArmCylHeadPrs : 0|16@1+ (0.25,0) [0|500] "bar" Vector__XXX

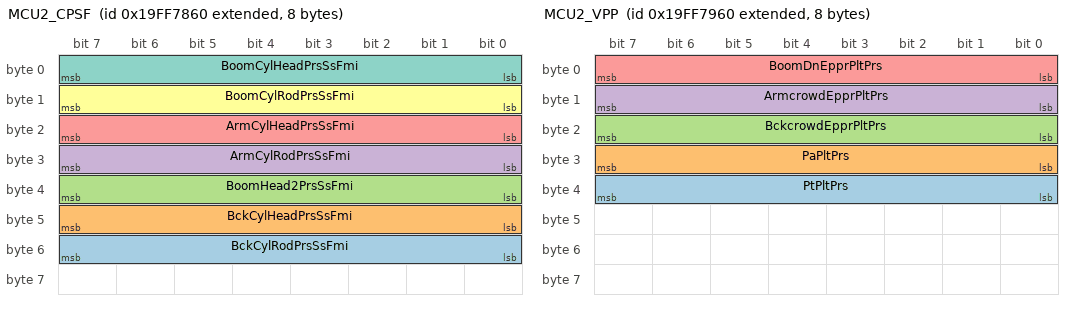
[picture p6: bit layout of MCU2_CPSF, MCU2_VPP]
BO_ 2583656544 MCU2_CPSF: 8 MCU2
 SG_ BckCylRodPrsSsFmi : 48|8@1+ (1,0) [0|255] "" Vector__XXX
 SG_ BckCylHeadPrsSsFmi : 40|8@1+ (1,0) [0|255] "" Vector__XXX
 SG_ BoomHead2PrsSsFmi : 32|8@1+ (1,0) [0|255] "" Vector__XXX
 SG_ ArmCylRodPrsSsFmi : 24|8@1+ (1,0) [0|255] "" Vector__XXX
 SG_ ArmCylHeadPrsSsFmi : 16|8@1+ (1,0) [0|255] "" Vector__XXX
 SG_ BoomCylRodPrsSsFmi : 8|8@1+ (1,0) [0|255] "" Vector__XXX
 SG_ BoomCylHeadPrsSsFmi : 0|8@1+ (1,0) [0|255] "" Vector__XXX

BO_ 2583656800 MCU2_VPP: 8 MCU2
 SG_ PtPltPrs : 32|8@1+ (0.25,0) [0|50] "bar" Vector__XXX
 SG_ PaPltPrs : 24|8@1+ (0.25,0) [0|50] "bar" Vector__XXX
 SG_ BckcrowdEpprPltPrs : 16|8@1+ (0.25,0) [0|50] "bar" Vector__XXX
 SG_ ArmcrowdEpprPltPrs : 8|8@1+ (0.25,0) [0|50] "bar" Vector__XXX
 SG_ BoomDnEpprPltPrs : 0|8@1+ (0.25,0) [0|50] "bar" Vector__XXX

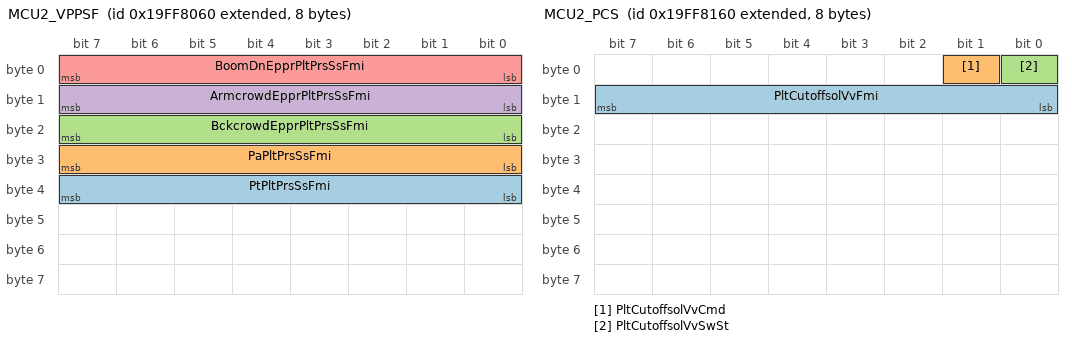
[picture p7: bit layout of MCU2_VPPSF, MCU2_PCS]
BO_ 2583658592 MCU2_VPPSF: 8 MCU2
 SG_ PtPltPrsSsFmi : 32|8@1+ (1,0) [0|255] "" Vector__XXX
 SG_ PaPltPrsSsFmi : 24|8@1+ (1,0) [0|255] "" Vector__XXX
 SG_ BckcrowdEpprPltPrsSsFmi : 16|8@1+ (1,0) [0|255] "" Vector__XXX
 SG_ ArmcrowdEpprPltPrsSsFmi : 8|8@1+ (1,0) [0|255] "" Vector__XXX
 SG_ BoomDnEpprPltPrsSsFmi : 0|8@1+ (1,0) [0|255] "" Vector__XXX

BO_ 2583658848 MCU2_PCS: 8 MCU2
 SG_ PltCutoffsolVvFmi : 8|8@1+ (1,0) [0|255] "" Vector__XXX
 SG_ PltCutoffsolVvCmd : 1|1@1+ (1,0) [0|1] "" Vector__XXX
 SG_ PltCutoffsolVvSwSt : 0|1@1+ (1,0) [0|1] "" Vector__XXX

BO_ 2583667233 MCU_CBCC: 8 MCU
 SG_ Bypass2EpprCmd : 42|10@1+ (1,0) [0|1023] "mA" Vector__XXX
 SG_ Bypass1EpprCmd : 32|10@1+ (1,0) [0|1023] "mA" Vector__XXX

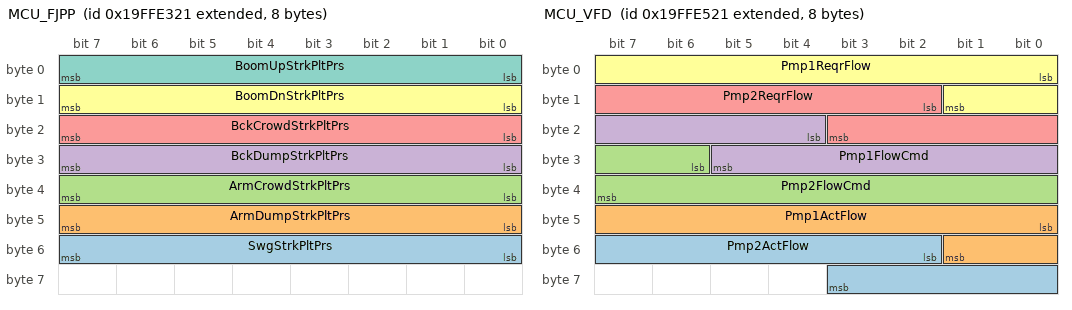
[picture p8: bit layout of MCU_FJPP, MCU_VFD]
BO_ 2583683873 MCU_FJPP: 8 MCU
 SG_ SwgStrkPltPrs : 48|8@1+ (0.25,0) [0|50] "bar" Vector__XXX
 SG_ ArmDumpStrkPltPrs : 40|8@1+ (0.25,0) [0|50] "bar" Vector__XXX
 SG_ ArmCrowdStrkPltPrs : 32|8@1+ (0.25,0) [0|50] "bar" Vector__XXX
 SG_ BckDumpStrkPltPrs : 24|8@1+ (0.25,0) [0|50] "bar" Vector__XXX
 SG_ BckCrowdStrkPltPrs : 16|8@1+ (0.25,0) [0|50] "bar" Vector__XXX
 SG_ BoomDnStrkPltPrs : 8|8@1+ (0.25,0) [0|50] "bar" Vector__XXX
 SG_ BoomUpStrkPltPrs : 0|8@1+ (0.25,0) [0|50] "bar" Vector__XXX

BO_ 2583684129 MCU_TJPP: 8 MCU
 SG_ TrvlRStrkPltPrs : 8|8@1+ (0.25,0) [0|50] "bar" Vector__XXX
 SG_ TrvlLStrkPltPrs : 0|8@1+ (0.25,0) [0|50] "bar" Vector__XXX

BO_ 2583684385 MCU_VFD: 8 MCU
 SG_ Pmp2ActFlow : 50|10@1+ (1,0) [0|1023] "ccps" Vector__XXX
 SG_ Pmp1ActFlow : 40|10@1+ (1,0) [0|1023] "ccps" Vector__XXX
 SG_ Pmp2FlowCmd : 30|10@1+ (1,0) [0|1023] "ccps" Vector__XXX
 SG_ Pmp1FlowCmd : 20|10@1+ (1,0) [0|1023] "ccps" Vector__XXX
 SG_ Pmp2ReqrFlow : 10|10@1+ (1,0) [0|1023] "ccps" Vector__XXX
 SG_ Pmp1ReqrFlow : 0|10@1+ (1,0) [0|1023] "ccps" Vector__XXX

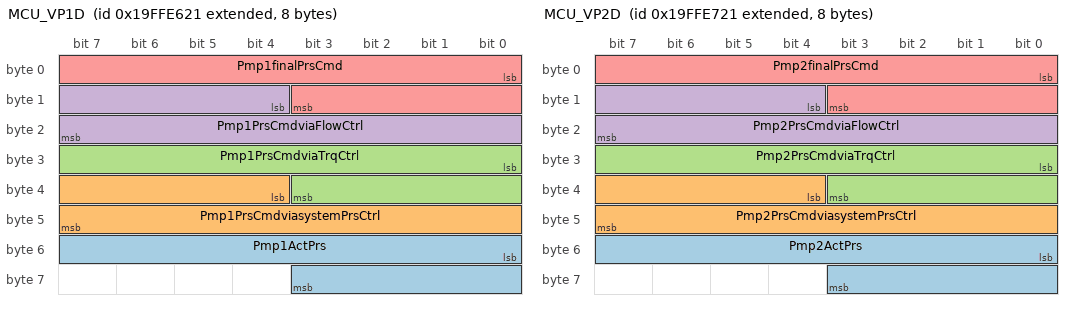
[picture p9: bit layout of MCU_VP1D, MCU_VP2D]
BO_ 2583684641 MCU_VP1D: 8 MCU
 SG_ Pmp1ActPrs : 48|12@1+ (1,0) [0|4095] "bar" Vector__XXX
 SG_ Pmp1PrsCmdviasystemPrsCtrl : 36|12@1+ (1,0) [0|4095] "bar" Vector__XXX
 SG_ Pmp1PrsCmdviaTrqCtrl : 24|12@1+ (1,0) [0|4095] "bar" Vector__XXX
 SG_ Pmp1PrsCmdviaFlowCtrl : 12|12@1+ (1,0) [0|4095] "bar" Vector__XXX
 SG_ Pmp1finalPrsCmd : 0|12@1+ (1,0) [0|4095] "bar" Vector__XXX

BO_ 2583684897 MCU_VP2D: 8 MCU
 SG_ Pmp2ActPrs : 48|12@1+ (1,0) [0|4095] "bar" Vector__XXX
 SG_ Pmp2PrsCmdviasystemPrsCtrl : 36|12@1+ (1,0) [0|4095] "bar" Vector__XXX
 SG_ Pmp2PrsCmdviaTrqCtrl : 24|12@1+ (1,0) [0|4095] "bar" Vector__XXX
 SG_ Pmp2PrsCmdviaFlowCtrl : 12|12@1+ (1,0) [0|4095] "bar" Vector__XXX
 SG_ Pmp2finalPrsCmd : 0|12@1+ (1,0) [0|4095] "bar" Vector__XXX

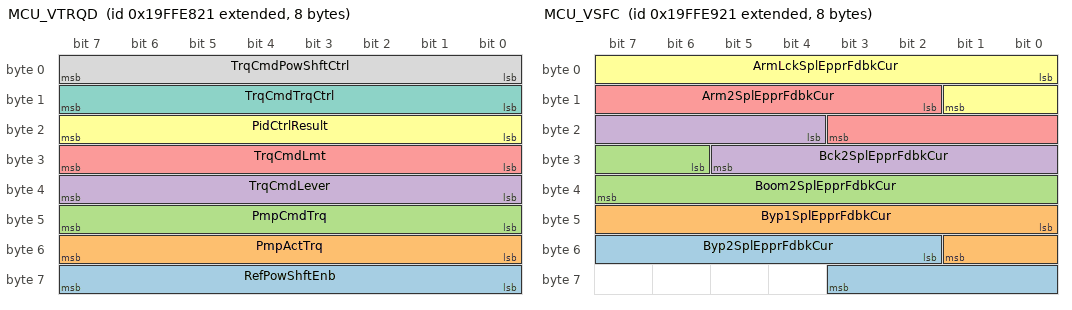
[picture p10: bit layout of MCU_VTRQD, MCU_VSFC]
BO_ 2583685153 MCU_VTRQD: 8 MCU
 SG_ RefPowShftEnb : 56|8@1+ (8,800) [800|2000] "Rpm" Vector__XXX
 SG_ PmpActTrq : 48|8@1+ (0.5,0) [0|127.5] "percent" Vector__XXX
 SG_ PmpCmdTrq : 40|8@1+ (0.5,0) [0|127.5] "percent" Vector__XXX
 SG_ TrqCmdLever : 32|8@1+ (0.5,0) [0|127.5] "percent" Vector__XXX
 SG_ TrqCmdLmt : 24|8@1+ (0.5,0) [0|127.5] "percent" Vector__XXX
 SG_ PidCtrlResult : 16|8@1- (-0.5,0) [-125|125] "percent" Vector__XXX
 SG_ TrqCmdTrqCtrl : 8|8@1+ (0.5,0) [0|127.5] "percent" Vector__XXX
 SG_ TrqCmdPowShftCtrl : 0|8@1+ (0.5,0) [0|127.5] "percent" Vector__XXX

BO_ 2583685409 MCU_VSFC: 8 MCU
 SG_ Byp2SplEpprFdbkCur : 50|10@1+ (1,0) [0|1000] "mA" Vector__XXX
 SG_ Byp1SplEpprFdbkCur : 40|10@1+ (1,0) [0|1000] "mA" Vector__XXX
 SG_ Boom2SplEpprFdbkCur : 30|10@1+ (1,0) [0|1000] "mA" Vector__XXX
 SG_ Bck2SplEpprFdbkCur : 20|10@1+ (1,0) [0|1000] "mA" Vector__XXX
 SG_ Arm2SplEpprFdbkCur : 10|10@1+ (1,0) [0|1000] "mA" Vector__XXX
 SG_ ArmLckSplEpprFdbkCur : 0|10@1+ (1,0) [0|1000] "mA" Vector__XXX

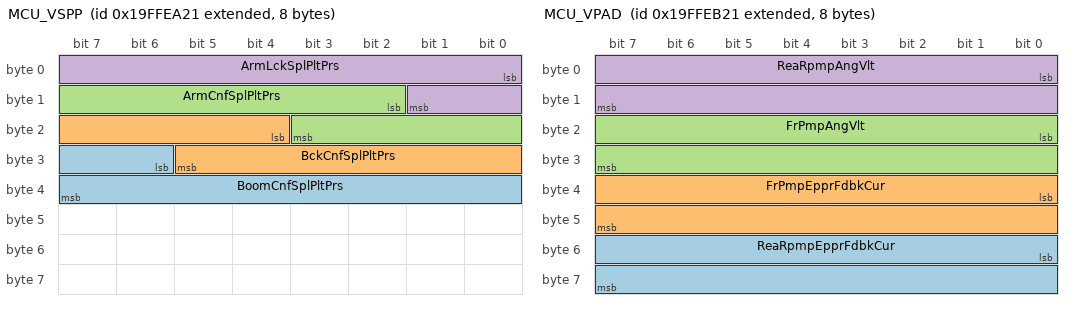
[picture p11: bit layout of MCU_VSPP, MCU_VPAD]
BO_ 2583685665 MCU_VSPP: 8 MCU
 SG_ BoomCnfSplPltPrs : 30|10@1+ (0.0625,0) [0|50] "bar" Vector__XXX
 SG_ BckCnfSplPltPrs : 20|10@1+ (0.0625,0) [0|50] "bar" Vector__XXX
 SG_ ArmCnfSplPltPrs : 10|10@1+ (0.0625,0) [0|50] "bar" Vector__XXX
 SG_ ArmLckSplPltPrs : 0|10@1+ (0.0625,0) [0|50] "bar" Vector__XXX

BO_ 2583685921 MCU_VPAD: 8 MCU
 SG_ ReaRpmpEpprFdbkCur : 48|16@1+ (1,0) [0|1000] "mA" Vector__XXX
 SG_ FrPmpEpprFdbkCur : 32|16@1+ (1,0) [0|1000] "mA" Vector__XXX
 SG_ FrPmpAngVlt : 16|16@1+ (1,0) [0|10000] "mV" Vector__XXX
 SG_ ReaRpmpAngVlt : 0|16@1+ (1,0) [0|10000] "mV" Vector__XXX

BO_ 2583686177 MCU_VTD: 8 MCU
 SG_ FrPmpAngVlt : 16|16@1- (1,-40) [-40|250] "Celsius" Vector__XXX
 SG_ OilFanEpprFdbkCur : 0|16@1+ (1,0) [0|1000] "mA" Vector__XXX

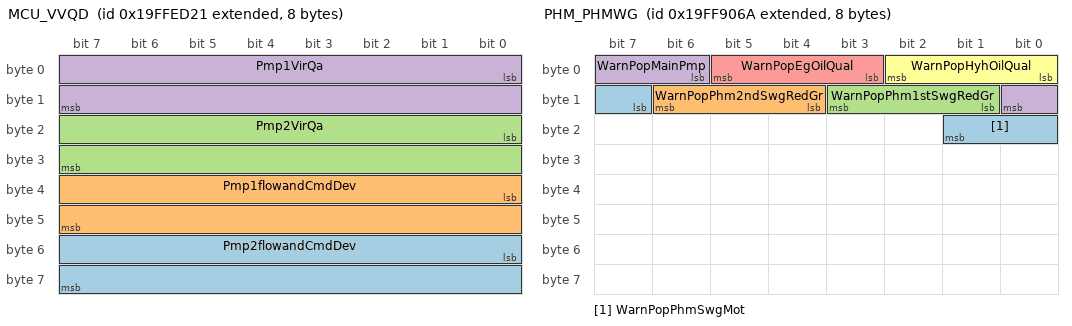
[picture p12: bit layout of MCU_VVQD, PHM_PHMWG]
BO_ 2583686433 MCU_VVQD: 8 MCU
 SG_ Pmp2flowandCmdDev : 48|16@1+ (1,0) [0|10000] "ccps" Vector__XXX
 SG_ Pmp1flowandCmdDev : 32|16@1+ (1,0) [0|10000] "ccps" Vector__XXX
 SG_ Pmp2VirQa : 16|16@1+ (1,0) [0|10000] "ccps" Vector__XXX
 SG_ Pmp1VirQa : 0|16@1+ (1,0) [0|10000] "ccps" Vector__XXX

BO_ 2382360307 AGW_TRADM2: 250 AGW
 SG_ H : 48|16@1+ (1,0) [0|64255] "" Vector__XXX
 SG_ G : 32|16@1+ (1,0) [0|64255] "" Vector__XXX
 SG_ F : 16|16@1+ (1,0) [0|64255] "" Vector__XXX
 SG_ E : 0|16@1+ (1,0) [0|64255] "" Vector__XXX

BO_ 2382360563 AGW_TRADM1: 250 AGW
 SG_ D : 48|16@1+ (1,0) [0|64255] "" Vector__XXX
 SG_ C : 32|16@1+ (1,0) [0|64255] "" Vector__XXX
 SG_ B : 16|16@1+ (1,0) [0|64255] "" Vector__XXX
 SG_ A : 0|16@1+ (1,0) [0|64255] "" Vector__XXX

BO_ 2382360819 AGW_TAIM1: 250 AGW
 SG_ ToolAttSerialNo : 32|8@1+ (1,0) [0|4294967295] "" Vector__XXX
 SG_ ToolAttTypeId : 16|8@1+ (1,0) [0|255] "" Vector__XXX
 SG_ ToolAttSaeId : 0|16@1+ (1,0) [0|65535] "" Vector__XXX

BO_ 2382361075 AGW_TRAIM1: 250 AGW
 SG_ TRAttSerialNo : 32|32@1+ (1,0) [0|4294967295] "" Vector__XXX
 SG_ TRAttTypeId : 16|8@1+ (1,0) [0|255] "" Vector__XXX
 SG_ TRAttSaeId : 0|16@1+ (1,0) [0|65535] "" Vector__XXX

BO_ 2382361331 AGW_TRSIM1: 250 AGW
 SG_ J1939Bitrate : 32|8@1+ (1,0) [0|255] "" Vector__XXX
 SG_ TransRepetitionRate : 24|8@1+ (1,0) [0|255] "" Vector__XXX
 SG_ AbsEncTiltSsSt : 22|2@1+ (1,0) [0|3] "" Vector__XXX
 SG_ ImuTiltSsSt : 20|2@1+ (1,0) [0|3] "" Vector__XXX
 SG_ RttSsSt : 18|2@1+ (1,0) [0|3] "" Vector__XXX
 SG_ TiltSsDataDlyMd : 16|1@1+ (1,0) [0|1] "" Vector__XXX
 SG_ SsFaultCode : 0|16@1+ (16,0) [0|0] "" Vector__XXX

BO_ 2382361587 AGW_TRRSDM1: 250 AGW
 SG_ RttSsdataDly : 48|16@1+ (2,0) [0|128510] "" Vector__XXX
 SG_ RttAngaroundZAxis : 0|16@1+ (0.0078125,-200) [-200|301.99] "" Vector__XXX

BO_ 2382361843 AGW_TRTSDM1: 250 AGW
 SG_ TiltSsdataDly : 48|16@1+ (2,0) [0|128510] "" Vector__XXX
 SG_ TiltAbsEncAng : 32|16@1+ (0.0078125,-250) [-250|250.992] "" Vector__XXX
 SG_ TiltImuAngaroundYAxis : 16|16@1+ (0.0078125,-200) [-200|301.99] "" Vector__XXX
 SG_ TiltImuAngaroundXAxis : 0|16@1+ (0.0078125,-200) [-200|301.99] "" Vector__XXX

BO_ 2382362867 AGW_AFIM1: 250 AGW
 SG_ TRToolLckSt : 56|2@1+ (1,0) [0|3] "" Vector__XXX
 SG_ OnOffFunc8St : 30|2@1+ (1,0) [0|3] "" Vector__XXX
 SG_ OnOffFunc7St : 28|2@1+ (1,0) [0|3] "" Vector__XXX
 SG_ OnOffFunc6St : 26|2@1+ (1,0) [0|3] "" Vector__XXX
 SG_ OnOffFunc5St : 24|2@1+ (1,0) [0|3] "" Vector__XXX
 SG_ OnOffFunc4St : 22|2@1+ (1,0) [0|3] "" Vector__XXX
 SG_ OnOffFunc3St : 20|2@1+ (1,0) [0|3] "" Vector__XXX
 SG_ OnOffFunc2St : 18|2@1+ (1,0) [0|3] "" Vector__XXX
 SG_ OnOffFunc1St : 16|2@1+ (1,0) [0|3] "" Vector__XXX
 SG_ PropFunc6St : 12|2@1+ (1,0) [0|3] "" Vector__XXX
 SG_ PropFunc5St : 10|2@1+ (1,0) [0|3] "" Vector__XXX
 SG_ PropFunc4St : 8|2@1+ (1,0) [0|3] "" Vector__XXX
 SG_ PropFunc3St : 4|2@1+ (1,0) [0|3] "" Vector__XXX
 SG_ PropFunc2St : 2|2@1+ (1,0) [0|3] "" Vector__XXX
 SG_ PropFunc1St : 0|2@1+ (1,0) [0|3] "" Vector__XXX

BO_ 2382363123 AGW_ALCM1: 250 AGW
 SG_ AttLckVvVal : 6|10@1+ (0.1,0) [0|102] "" Vector__XXX
 SG_ AttLckVvPosiSt : 4|2@1+ (1,0) [0|3] "" Vector__XXX
 SG_ AttLckVvNegaSt : 2|2@1+ (1,0) [0|3] "" Vector__XXX

BO_ 2382363379 AGW_AHCM1: 250 AGW
 SG_ AuxHyh3Val : 38|10@1+ (0.1,0) [0|102] "" Vector__XXX
 SG_ AuxHyh3PosiSt : 36|2@1+ (1,0) [0|3] "" Vector__XXX
 SG_ AuxHyh3NegaSt : 34|2@1+ (1,0) [0|3] "" Vector__XXX
 SG_ AuxHyh3NtrlSt : 32|2@1+ (1,0) [0|3] "" Vector__XXX
 SG_ AuxHyh2Val : 22|10@1+ (0.1,0) [0|102] "" Vector__XXX
 SG_ AuxHyh2PosiSt : 20|2@1+ (1,0) [0|3] "" Vector__XXX
 SG_ AuxHyh2NegaSt : 18|2@1+ (1,0) [0|3] "" Vector__XXX
 SG_ AuxHyh2NtrlSt : 16|2@1+ (1,0) [0|3] "" Vector__XXX
 SG_ AuxHyh1Val : 6|10@1+ (0.1,0) [0|102] "" Vector__XXX
 SG_ AuxHyh1PosiSt : 4|2@1+ (1,0) [0|3] "" Vector__XXX
 SG_ AuxHyh1NegaSt : 2|2@1+ (1,0) [0|3] "" Vector__XXX
 SG_ AuxHyh1NtrlSt : 0|2@1+ (1,0) [0|3] "" Vector__XXX

BO_ 2382363681 MCU_EIM1: 250 MCU
 SG_ AuxHyh3Val : 38|10@1+ (0.1,0) [0|102] "" Vector__XXX
 SG_ AuxHyh3PosiSt : 36|2@1+ (1,0) [0|3] "" Vector__XXX
 SG_ AuxHyh3NegaSt : 34|2@1+ (1,0) [0|3] "" Vector__XXX
 SG_ AuxHyh3NtrlSt : 32|2@1+ (1,0) [0|3] "" Vector__XXX
 SG_ AuxHyh2Val : 22|10@1+ (0.1,0) [0|102] "" Vector__XXX
 SG_ AuxHyh2PosiSt : 20|2@1+ (1,0) [0|3] "" Vector__XXX
 SG_ AuxHyh2NegaSt : 18|2@1+ (1,0) [0|3] "" Vector__XXX
 SG_ AuxHyh2NtrlSt : 16|2@1+ (1,0) [0|3] "" Vector__XXX
 SG_ AuxHyh1Val : 6|10@1+ (0.1,0) [0|102] "" Vector__XXX
 SG_ AuxHyh1PosiSt : 4|2@1+ (1,0) [0|3] "" Vector__XXX
 SG_ AuxHyh1NegaSt : 2|2@1+ (1,0) [0|3] "" Vector__XXX
 SG_ AuxHyh1NtrlSt : 0|2@1+ (1,0) [0|3] "" Vector__XXX

BO_ 2382364193 MCU_ACM2: 250 MCU
 SG_ OnOffFunc5St : 62|2@1+ (1,0) [0|3] "" Vector__XXX
 SG_ OnOffFunc6St : 60|2@1+ (1,0) [0|3] "" Vector__XXX
 SG_ OnOffFunc7St : 58|2@1+ (1,0) [0|3] "" Vector__XXX
 SG_ OnOffFunc8St : 56|2@1+ (1,0) [0|3] "" Vector__XXX
 SG_ PropFunc6Val : 38|10@1+ (0.1,0) [0|102] "" Vector__XXX
 SG_ PropFunc6PosiSt : 36|2@1+ (1,0) [0|3] "" Vector__XXX
 SG_ PropFunc6NegaSt : 34|2@1+ (1,0) [0|3] "" Vector__XXX
 SG_ PropFunc6NtrlSt : 32|2@1+ (1,0) [0|3] "" Vector__XXX
 SG_ PropFunc5Val : 22|10@1+ (0.1,0) [0|102] "" Vector__XXX
 SG_ PropFunc5PosiSt : 20|2@1+ (1,0) [0|3] "" Vector__XXX
 SG_ PropFunc5NegaSt : 18|2@1+ (1,0) [0|3] "" Vector__XXX
 SG_ PropFunc5NtrlSt : 16|2@1+ (1,0) [0|3] "" Vector__XXX
 SG_ PropFunc4Val : 6|10@1+ (0.1,0) [0|102] "" Vector__XXX
 SG_ PropFunc4PosiSt : 4|2@1+ (1,0) [0|3] "" Vector__XXX
 SG_ PropFunc4NegaSt : 2|2@1+ (1,0) [0|3] "" Vector__XXX
 SG_ PropFunc4NtrlSt : 0|2@1+ (1,0) [0|3] "" Vector__XXX

BO_ 2382364449 MCU_ACM1: 250 MCU
 SG_ OnOffFunc1St : 62|2@1+ (1,0) [0|3] "" Vector__XXX
 SG_ OnOffFunc2St : 60|2@1+ (1,0) [0|3] "" Vector__XXX
 SG_ OnOffFunc3St : 58|2@1+ (1,0) [0|3] "" Vector__XXX
 SG_ OnOffFunc4St : 56|2@1+ (1,0) [0|3] "" Vector__XXX
 SG_ PropFunc3Value : 38|10@1+ (0.1,0) [0|102] "" Vector__XXX
 SG_ PropFunc3PosiSt : 36|2@1+ (1,0) [0|3] "" Vector__XXX
 SG_ PropFunc3NegaSt : 34|2@1+ (1,0) [0|3] "" Vector__XXX
 SG_ PropFunc3NtrlSt : 32|2@1+ (1,0) [0|3] "" Vector__XXX
 SG_ PropFunc2Value : 22|10@1+ (0.1,0) [0|102] "" Vector__XXX
 SG_ PropFunc2PosiSt : 20|2@1+ (1,0) [0|3] "" Vector__XXX
 SG_ PropFunc2NegaSt : 18|2@1+ (1,0) [0|3] "" Vector__XXX
 SG_ PropFunc2NtrlSt : 16|2@1+ (1,0) [0|3] "" Vector__XXX
 SG_ PropFunc1Value : 6|10@1+ (0.1,0) [0|102] "" Vector__XXX
 SG_ PropFunc1PosiSt : 4|2@1+ (1,0) [0|3] "" Vector__XXX
 SG_ PropFunc1NegaSt : 2|2@1+ (1,0) [0|3] "" Vector__XXX
 SG_ PropFunc1NtrlSt : 0|2@1+ (1,0) [0|3] "" Vector__XXX

BO_ 2566842442 TGU_VDS: 8 TGU
 SG_ Z : 48|16@1- (0.125,-2500) [-2500|5531.875] "m" Vector__XXX
 SG_ Spd : 16|16@1+ (0.00390625,0) [0|250.996] "kmph" Vector__XXX

BO_ 2566845258 TGU_VP1: 8 TGU
 SG_ Y : 32|32@1+ (1E-07,-210) [-210|211.1081215] "deg" Vector__XXX
 SG_ X : 0|32@1+ (1E-07,-210) [-210|211.1081215] "deg" Vector__XXX

BO_ 2583642954 TGU_DKLLG: 250 TGU
 SG_ Dkey : 8|48@1+ (1,0) [0|281474976710655] "" Vector__XXX
 SG_ SelType : 0|3@1+ (1,0) [0|7] "" Vector__XXX

BO_ 2583643466 TGU_DKTL: 1785 TGU
 SG_ DkeyListInfo : 0|14280@1+ (1,0) [0|0] "ASCII-VN" Vector__XXX

BO_ 2583642186 TGU_MPS: 8 TGU
 SG_ TokenRevCnt : 2|8@1+ (1,0) [0|255] "" Vector__XXX
 SG_ MpSt : 0|2@1+ (1,0) [0|3] "" Vector__XXX

BO_ 2583642442 TGU_MPI: 96 TGU
 SG_ TguId : 608|160@1+ (1,0) [0|1.4615016373309E+48] "ASCII-FN" Vector__XXX
 SG_ Name : 448|160@1+ (1,0) [0|1.4615016373309E+48] "ASCII-FN" Vector__XXX
 SG_ Mcode : 368|80@1+ (1,0) [0|1.20892581961463E+24] "ASCII-FN" Vector__XXX
 SG_ Vin : 208|160@1+ (1,0) [0|1.4615016373309E+48] "ASCII-FN" Vector__XXX
 SG_ Oem : 160|48@1+ (1,0) [0|281474976710655] "ASCII-FN" Vector__XXX
 SG_ Mch : 0|160@1+ (1,0) [0|1.4615016373309E+48] "ASCII-FN" Vector__XXX

BO_ 2583662698 PHM_PHMWG: 8 PHM
 SG_ WarnPopPhmSwgMot : 15|3@1+ (1,0) [0|7] "" Vector__XXX
 SG_ WarnPopPhm2ndSwgRedGr : 12|3@1+ (1,0) [0|7] "" Vector__XXX
 SG_ WarnPopPhm1stSwgRedGr : 9|3@1+ (1,0) [0|7] "" Vector__XXX
 SG_ WarnPopMainPmp : 6|3@1+ (1,0) [0|7] "" Vector__XXX
 SG_ WarnPopEgOilQual : 3|3@1+ (1,0) [0|7] "" Vector__XXX
 SG_ WarnPopHyhOilQual : 0|3@1+ (1,0) [0|7] "" Vector__XXX

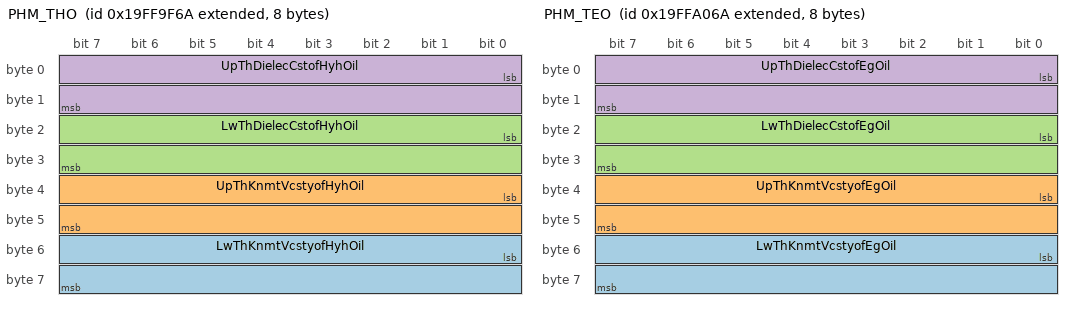
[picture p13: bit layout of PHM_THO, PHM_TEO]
BO_ 2583666538 PHM_THO: 8 PHM
 SG_ LwThKnmtVcstyofHyhOil : 48|16@1+ (1,0) [0|65535] "" Vector__XXX
 SG_ UpThKnmtVcstyofHyhOil : 32|16@1+ (1,0) [0|65535] "" Vector__XXX
 SG_ LwThDielecCstofHyhOil : 16|16@1+ (0.0001220703125,0) [0|7.844] "" Vector__XXX
 SG_ UpThDielecCstofHyhOil : 0|16@1+ (0.0001220703125,0) [0|7.844] "" Vector__XXX

BO_ 2583666794 PHM_TEO: 8 PHM
 SG_ LwThKnmtVcstyofEgOil : 48|16@1+ (1,0) [0|65535] "" Vector__XXX
 SG_ UpThKnmtVcstyofEgOil : 32|16@1+ (1,0) [0|65535] "" Vector__XXX
 SG_ LwThDielecCstofEgOil : 16|16@1+ (0.0001220703125,0) [0|7.844] "" Vector__XXX
 SG_ UpThDielecCstofEgOil : 0|16@1+ (0.0001220703125,0) [0|7.844] "" Vector__XXX

BO_ 2583667050 PHM_KVO: 8 PHM
 SG_ KnmtVcstyofEgOil : 16|16@1+ (1,0) [0|65535] "" Vector__XXX
 SG_ KnmtVcstyofHyhOil : 0|16@1+ (1,0) [0|65535] "" Vector__XXX

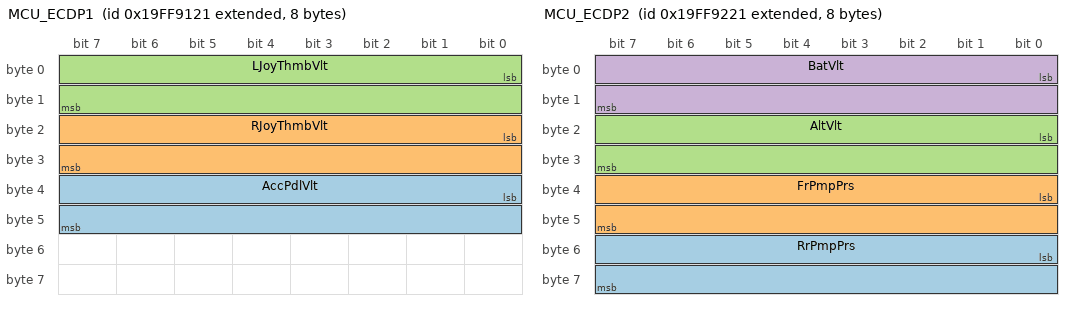
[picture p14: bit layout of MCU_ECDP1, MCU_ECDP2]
BO_ 2583662881 MCU_ECDP1: 8 MCU
 SG_ AccPdlVlt : 32|16@1+ (0.001,0) [0|64.255] "" Vector__XXX
 SG_ RJoyThmbVlt : 16|16@1+ (0.001,0) [0|64.255] "" Vector__XXX
 SG_ LJoyThmbVlt : 0|16@1+ (0.001,0) [0|64.255] "" Vector__XXX

BO_ 2583663137 MCU_ECDP2: 8 MCU
 SG_ RrPmpPrs : 48|16@1+ (0.0625,0) [0|500] "bar" Vector__XXX
 SG_ FrPmpPrs : 32|16@1+ (0.0625,0) [0|500] "bar" Vector__XXX
 SG_ AltVlt : 16|16@1+ (0.001,0) [0|64.255] "" Vector__XXX
 SG_ BatVlt : 0|16@1+ (0.001,0) [0|64.255] "" Vector__XXX

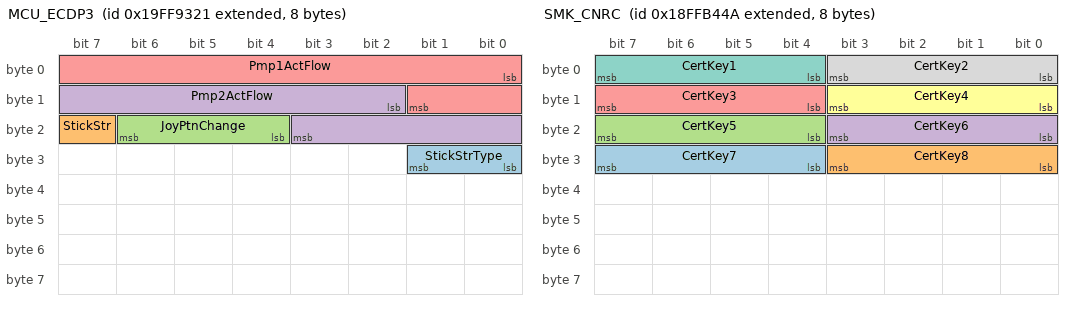
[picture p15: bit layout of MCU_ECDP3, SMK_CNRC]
BO_ 2583663393 MCU_ECDP3: 8 MCU
 SG_ StickStrType : 24|2@1+ (1,0) [0|3] "" Vector__XXX
 SG_ StickStr : 23|1@1+ (1,0) [0|1] "" Vector__XXX
 SG_ JoyPtnChange : 20|3@1+ (1,0) [0|7] "" Vector__XXX
 SG_ Pmp2ActFlow : 10|10@1+ (10,0) [0|10000] "ccps" Vector__XXX
 SG_ Pmp1ActFlow : 0|10@1+ (10,0) [0|10000] "ccps" Vector__XXX

BO_ 2633656127 HDOQS_OQM2: 8 HDOQS
 SG_ Oilresistivity : 0|32@1+ (1000,0) [0|4211081215000] "Ω" Vector__XXX

BO_ 2633656238 EGOQS_OQM2: 8 EGOQS
 SG_ Oilresistivity : 0|32@1+ (1000,0) [0|4211081215000] "Ω" Vector__XXX

BO_ 2566894666 SMK_CNRC: 8 SMK
 SG_ CertKey7 : 28|4@1+ (1,0) [0|15] "" Vector__XXX
 SG_ CertKey8 : 24|4@1+ (1,0) [0|15] "" Vector__XXX
 SG_ CertKey5 : 20|4@1+ (1,0) [0|15] "" Vector__XXX
 SG_ CertKey6 : 16|4@1+ (1,0) [0|15] "" Vector__XXX
 SG_ CertKey3 : 12|4@1+ (1,0) [0|15] "" Vector__XXX
 SG_ CertKey4 : 8|4@1+ (1,0) [0|15] "" Vector__XXX
 SG_ CertKey1 : 4|4@1+ (1,0) [0|15] "" Vector__XXX
 SG_ CertKey2 : 0|4@1+ (1,0) [0|15] "" Vector__XXX

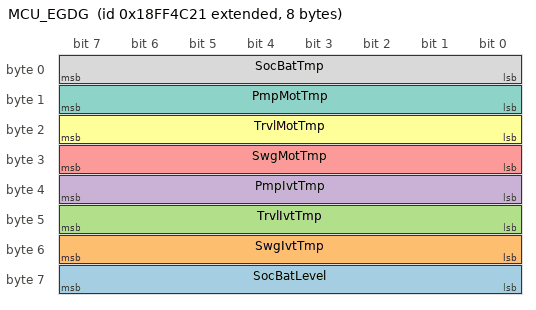
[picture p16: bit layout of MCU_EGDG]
BO_ 2566868001 MCU_EGDG: 8 MCU
 SG_ SocBatLevel : 56|8@1+ (1,0) [0|250] "" Vector__XXX
 SG_ SwgIvtTmp : 48|8@1+ (1,0) [0|250] "" Vector__XXX
 SG_ TrvlIvtTmp : 40|8@1+ (1,0) [0|250] "" Vector__XXX
 SG_ PmpIvtTmp : 32|8@1+ (1,0) [0|250] "" Vector__XXX
 SG_ SwgMotTmp : 24|8@1+ (1,0) [0|250] "" Vector__XXX
 SG_ TrvlMotTmp : 16|8@1+ (1,0) [0|250] "" Vector__XXX
 SG_ PmpMotTmp : 8|8@1+ (1,0) [0|250] "" Vector__XXX
 SG_ SocBatTmp : 0|8@1+ (1,0) [0|250] "" Vector__XXX

BO_ 2634015777 MCU_TCUMPRQ: 250 MCU
 SG_ ReqCd : 24|8@1+ (1,0) [0|255] "" Vector__XXX
 SG_ MaxGrLmt : 20|4@1+ (1,0) [0|15] "" Vector__XXX
 SG_ EmsCtrl : 16|4@1+ (1,0) [0|15] "" Vector__XXX
 SG_ MchClass : 8|8@1+ (1,0) [0|255] "" Vector__XXX
 SG_ MchGenr : 0|8@1+ (1,0) [0|255] "" Vector__XXX

BO_ 2634016259 MCU_TCUMPRS: 250 MCU
 SG_ ResultCd : 48|8@1+ (1,0) [0|255] "" Vector__XXX
 SG_ AxleOpt : 40|8@1+ (1,0) [0|255] "" Vector__XXX
 SG_ MaxGrLmt : 32|8@1+ (1,0) [0|255] "" Vector__XXX
 SG_ EmsCtrl : 24|8@1+ (1,0) [0|255] "" Vector__XXX
 SG_ MchClass : 8|16@1+ (1,0) [0|65535] "" Vector__XXX
 SG_ MchGenr : 0|8@1+ (1,0) [0|255] "" Vector__XXX

BO_ 2566912033 MCU_MWHG5: 205 MCU
 SG_ ImuAxisSetTiltBck05 : 1632|8@1+ (1,0) [0|255] "" Vector__XXX
 SG_ ImuAxisSetTiltBck04 : 1624|8@1+ (1,0) [0|255] "" Vector__XXX
 SG_ ImuAxisSetTiltBck03 : 1616|8@1+ (1,0) [0|255] "" Vector__XXX
 SG_ ImuAxisSetTiltBck02 : 1608|8@1+ (1,0) [0|255] "" Vector__XXX
 SG_ ImuAxisSetTiltBck01 : 1600|8@1+ (1,0) [0|255] "" Vector__XXX
 SG_ TiltBck05DmsnNq3 : 1584|16@1+ (1,0) [0|64255] "" Vector__XXX
 SG_ TiltBck05DmsnNq2 : 1568|16@1+ (1,0) [0|64255] "" Vector__XXX
 SG_ TiltBck05DmsnNq1 : 1552|16@1+ (1,0) [0|64255] "" Vector__XXX
 SG_ TiltBck05DmsnWd : 1536|16@1+ (1,0) [0|64255] "" Vector__XXX
 SG_ TiltBck05DmsnUq3 : 1520|16@1+ (1,0) [0|64255] "" Vector__XXX
 SG_ TiltBck05DmsnUq2 : 1504|16@1+ (1,0) [0|64255] "" Vector__XXX
 SG_ TiltBck05DmsnUq1 : 1488|16@1+ (1,0) [0|64255] "" Vector__XXX
 SG_ TiltBck05DmsnUm : 1472|16@1+ (1,0) [0|64255] "" Vector__XXX
 SG_ TiltBck05DmsnDt : 1456|16@1+ (1,0) [0|64255] "" Vector__XXX
 SG_ TiltBck05DmsnDg : 1440|16@1+ (1,0) [0|64255] "" Vector__XXX
 SG_ TiltBck05DmsnGdt : 1416|24@1- (3.0517578125E-05,-250) [-250|252] "" Vector__XXX
 SG_ ImuSsOffsetTiltBck05Roll : 1392|24@1- (3.0517578125E-05,-250) [-250|252] "" Vector__XXX
 SG_ ImuSsOffsetTiltBck05Pch : 1368|24@1- (3.0517578125E-05,-250) [-250|252] "" Vector__XXX
 SG_ TiltBck05DmsnTuN : 1344|24@1- (3.0517578125E-05,-250) [-250|252] "" Vector__XXX
 SG_ TiltBck05DmsnTthMn : 1328|16@1+ (1,0) [0|64255] "" Vector__XXX
 SG_ TiltBck05DmsnUn : 1312|16@1+ (1,0) [0|64255] "" Vector__XXX
 SG_ TiltBck05DmsnTn : 1296|16@1+ (1,0) [0|64255] "" Vector__XXX
 SG_ TiltBck05DmsnTu : 1280|16@1+ (1,0) [0|64255] "" Vector__XXX
 SG_ TiltBck04DmsnNq3 : 1264|16@1+ (1,0) [0|64255] "" Vector__XXX
 SG_ TiltBck04DmsnNq2 : 1248|16@1+ (1,0) [0|64255] "" Vector__XXX
 SG_ TiltBck04DmsnNq1 : 1232|16@1+ (1,0) [0|64255] "" Vector__XXX
 SG_ TiltBck04DmsnWd : 1216|16@1+ (1,0) [0|64255] "" Vector__XXX
 SG_ TiltBck04DmsnUq3 : 1200|16@1+ (1,0) [0|64255] "" Vector__XXX
 SG_ TiltBck04DmsnUq2 : 1184|16@1+ (1,0) [0|64255] "" Vector__XXX
 SG_ TiltBck04DmsnUq1 : 1168|16@1+ (1,0) [0|64255] "" Vector__XXX
 SG_ TiltBck04DmsnUm : 1152|16@1+ (1,0) [0|64255] "" Vector__XXX
 SG_ TiltBck04DmsnDt : 1136|16@1+ (1,0) [0|64255] "" Vector__XXX
 SG_ TiltBck04DmsnDg : 1120|16@1+ (1,0) [0|64255] "" Vector__XXX
 SG_ TiltBck04DmsnGdt : 1096|24@1- (3.0517578125E-05,-250) [-250|252] "" Vector__XXX
 SG_ ImuSsOffsetTiltBck04Roll : 1072|24@1- (3.0517578125E-05,-250) [-250|252] "" Vector__XXX
 SG_ ImuSsOffsetTiltBck04Pch : 1048|24@1- (3.0517578125E-05,-250) [-250|252] "" Vector__XXX
 SG_ TiltBck04DmsnTuN : 1024|24@1- (3.0517578125E-05,-250) [-250|252] "" Vector__XXX
 SG_ TiltBck04DmsnTthMn : 1008|16@1+ (1,0) [0|64255] "" Vector__XXX
 SG_ TiltBck04DmsnUn : 992|16@1+ (1,0) [0|64255] "" Vector__XXX
 SG_ TiltBck04DmsnTn : 976|16@1+ (1,0) [0|64255] "" Vector__XXX
 SG_ TiltBck04DmsnTu : 960|16@1+ (1,0) [0|64255] "" Vector__XXX
 SG_ TiltBck03DmsnNq3 : 944|16@1+ (1,0) [0|64255] "" Vector__XXX
 SG_ TiltBck03DmsnNq2 : 928|16@1+ (1,0) [0|64255] "" Vector__XXX
 SG_ TiltBck03DmsnNq1 : 912|16@1+ (1,0) [0|64255] "" Vector__XXX
 SG_ TiltBck03DmsnWd : 896|16@1+ (1,0) [0|64255] "" Vector__XXX
 SG_ TiltBck03DmsnUq3 : 880|16@1+ (1,0) [0|64255] "" Vector__XXX
 SG_ TiltBck03DmsnUq2 : 864|16@1+ (1,0) [0|64255] "" Vector__XXX
 SG_ TiltBck03DmsnUq1 : 848|16@1+ (1,0) [0|64255] "" Vector__XXX
 SG_ TiltBck03DmsnUm : 832|16@1+ (1,0) [0|64255] "" Vector__XXX
 SG_ TiltBck03DmsnDt : 816|16@1+ (1,0) [0|64255] "" Vector__XXX
 SG_ TiltBck03DmsnDg : 800|16@1+ (1,0) [0|64255] "" Vector__XXX
 SG_ TiltBck03DmsnGdt : 776|24@1- (3.0517578125E-05,-250) [-250|252] "" Vector__XXX
 SG_ ImuSsOffsetTiltBck03Roll : 752|24@1- (3.0517578125E-05,-250) [-250|252] "" Vector__XXX
 SG_ ImuSsOffsetTiltBck03Pch : 728|24@1- (3.0517578125E-05,-250) [-250|252] "" Vector__XXX
 SG_ TiltBck03DmsnTuN : 704|24@1- (3.0517578125E-05,-250) [-250|252] "" Vector__XXX
 SG_ TiltBck03DmsnTthMn : 688|16@1+ (1,0) [0|64255] "" Vector__XXX
 SG_ TiltBck03DmsnUn : 672|16@1+ (1,0) [0|64255] "" Vector__XXX
 SG_ TiltBck03DmsnTn : 656|16@1+ (1,0) [0|64255] "" Vector__XXX
 SG_ TiltBck03DmsnTu : 640|16@1+ (1,0) [0|64255] "" Vector__XXX
 SG_ TiltBck02DmsnNq3 : 624|16@1+ (1,0) [0|64255] "" Vector__XXX
 SG_ TiltBck02DmsnNq2 : 608|16@1+ (1,0) [0|64255] "" Vector__XXX
 SG_ TiltBck02DmsnNq1 : 592|16@1+ (1,0) [0|64255] "" Vector__XXX
 SG_ TiltBck02DmsnWd : 576|16@1+ (1,0) [0|64255] "" Vector__XXX
 SG_ TiltBck02DmsnUq3 : 560|16@1+ (1,0) [0|64255] "" Vector__XXX
 SG_ TiltBck02DmsnUq2 : 544|16@1+ (1,0) [0|64255] "" Vector__XXX
 SG_ TiltBck02DmsnUq1 : 528|16@1+ (1,0) [0|64255] "" Vector__XXX
 SG_ TiltBck02DmsnUm : 512|16@1+ (1,0) [0|64255] "" Vector__XXX
 SG_ TiltBck02DmsnDt : 496|16@1+ (1,0) [0|64255] "" Vector__XXX
 SG_ TiltBck02DmsnDg : 480|16@1+ (1,0) [0|64255] "" Vector__XXX
 SG_ TiltBck02DmsnGdt : 456|24@1- (3.0517578125E-05,-250) [-250|252] "" Vector__XXX
 SG_ ImuSsOffsetTiltBck02Roll : 432|24@1- (3.0517578125E-05,-250) [-250|252] "" Vector__XXX
 SG_ ImuSsOffsetTiltBck02Pch : 408|24@1- (3.0517578125E-05,-250) [-250|252] "" Vector__XXX
 SG_ TiltBck02DmsnTuN : 384|24@1- (3.0517578125E-05,-250) [-250|252] "" Vector__XXX
 SG_ TiltBck02DmsnTthMn : 368|16@1+ (1,0) [0|64255] "" Vector__XXX
 SG_ TiltBck02DmsnUn : 352|16@1+ (1,0) [0|64255] "" Vector__XXX
 SG_ TiltBck02DmsnTn : 336|16@1+ (1,0) [0|64255] "" Vector__XXX
 SG_ TiltBck02DmsnTu : 320|16@1+ (1,0) [0|64255] "" Vector__XXX
 SG_ TiltBck01DmsnNq3 : 304|16@1+ (1,0) [0|64255] "" Vector__XXX
 SG_ TiltBck01DmsnNq2 : 288|16@1+ (1,0) [0|64255] "" Vector__XXX
 SG_ TiltBck01DmsnNq1 : 272|16@1+ (1,0) [0|64255] "" Vector__XXX
 SG_ TiltBck01DmsnWd : 256|16@1+ (1,0) [0|64255] "" Vector__XXX
 SG_ TiltBck01DmsnUq3 : 240|16@1+ (1,0) [0|64255] "" Vector__XXX
 SG_ TiltBck01DmsnUq2 : 224|16@1+ (1,0) [0|64255] "" Vector__XXX
 SG_ TiltBck01DmsnUq1 : 208|16@1+ (1,0) [0|64255] "" Vector__XXX
 SG_ TiltBck01DmsnUm : 192|16@1+ (1,0) [0|64255] "" Vector__XXX
 SG_ TiltBck01DmsnDt : 176|16@1+ (1,0) [0|64255] "" Vector__XXX
 SG_ TiltBck01DmsnDg : 160|16@1+ (1,0) [0|64255] "" Vector__XXX
 SG_ TiltBck01DmsnGdt : 136|24@1- (3.0517578125E-05,-250) [-250|252] "" Vector__XXX
 SG_ ImuSsOffsetTiltBck01Roll : 112|24@1- (3.0517578125E-05,-250) [-250|252] "" Vector__XXX
 SG_ ImuSsOffsetTiltBck01Pch : 88|24@1- (3.0517578125E-05,-250) [-250|252] "" Vector__XXX
 SG_ TiltBck01DmsnTun : 64|24@1- (3.0517578125E-05,-250) [-250|252] "" Vector__XXX
 SG_ TiltBck01DmsnTthMn : 48|16@1+ (1,0) [0|64255] "" Vector__XXX
 SG_ TiltBck01DmsnUn : 32|16@1+ (1,0) [0|64255] "" Vector__XXX
 SG_ TiltBck01DmsnTn : 16|16@1+ (1,0) [0|64255] "" Vector__XXX
 SG_ TiltBck01DmsnTu : 0|16@1+ (1,0) [0|64255] "" Vector__XXX

CM_ BO_ 2566907937 "Machine Configuration Information";
CM_ SG_ 2566907937 RhJoyBtnAux12AddSetConfig "RH Joystick Button Aux 1,2 Add Setting Configuration";
CM_ SG_ 2566907937 HeavyAttConfig "Heavy Attachment Configuration";
CM_ SG_ 2566907937 IdleSpdSetConfig "Idle Speed Setting Configuration";
CM_ SG_ 2566907937 SdkParallelLiftConfig "SDK Parallel Lift Configuration";
CM_ SG_ 2566907937 RsvforVdk10W "Reserved for VDK10W ";
CM_ SG_ 2566907937 BrkOprgTmLmConfigforVccC4 "Breaker Operating Time Limit Configuration (for VCC_C4)";
CM_ SG_ 2566907937 ElectStrThmbwhlConfig "Electric Steering Thumbwheel (RH->LH) Configuration";
CM_ SG_ 2566907937 EmgStrConfig "Emergency Steering (Secondary Pump Switching) Configuration";
CM_ SG_ 2566907937 LongLifeEgOilFiltConfig "LongLife EngineOil/EngineOilFilter/FuelFilter Configuration";
CM_ SG_ 2566907937 ElecStrJoyThwConf "ElectricSteeringJoystickThumbwheelConfiguration";
CM_ SG_ 2566907937 Dl06EgFuelEffCalbConf "DL06EngineFuelEfficiencyCalibrationConfiguration";
CM_ SG_ 2566907937 RttThwDirConf "RotatingThumb WheelActDirectionSettingConfiguration";
CM_ SG_ 2566907937 TwThwDirConf "2wayThumb WheelActDirectionSettingConfiguration";
CM_ SG_ 2566907937 CanPdlIntChngConf "CANPedalInterchangeabilityConfiguration";
CM_ SG_ 2566907937 TrvlSwgAlmIntChngConf "TravelSwingAlarmInterchangeabilityConfiguration";
CM_ SG_ 2566907937 OprHrTmpIntChngConf "OperationHourPerTemperatureInterchangeabilityConfiguration";
CM_ SG_ 2566907937 QckCouplerIntChngConf "QuickCouplerInterchangeabilityConfiguration";
CM_ SG_ 2566907937 ThwSensConf "ThumbWheelSensitivityConfiguration";
CM_ SG_ 2566907937 MultiFuncJoyBtnConf "MultifunctionJoystickButtonConfiguration";
CM_ BO_ 2566908449 "MC Weighing Info Group";
CM_ SG_ 2566908449 TiltRttArg "Indicator Symbol; Tilt-Rotator Arrangement";
CM_ SG_ 2566908449 GnssSt "GNSS Status";
CM_ SG_ 2566908449 VhcStFineSwgTprDsb "Vehicle Status; Fine Swing Temporary Disable";
CM_ SG_ 2566908449 IndSymbolMcTprRlsSt "Indicator Symbol; MC Temporary Release Status";
CM_ SG_ 2566908449 EfenceTgSetSideWallR "E-Fence Target Set; Side Wall Right";
CM_ SG_ 2566908449 EfenceWarnSideWallR "E-Fence Warning; Side Wall Right";
CM_ SG_ 2566908449 EfenceWarnSideWallL "E-Fence Warning; Side Wall Left";
CM_ SG_ 2566908449 AssitSwgRh "AssistStatus;SwingRight";
CM_ SG_ 2566908449 AssitSwgLh "AssistStatus;SwingLeft";
CM_ SG_ 2566908449 AssitBck "AssistStatus;Bucket";
CM_ SG_ 2566908449 AssitGrd "AssistStatus;Grade";
CM_ SG_ 2566908449 SafeWrkSideFar "SafeWorkingIndicator;SideFar";
CM_ SG_ 2566908449 SafeWrkSideMid "SafeWorkingIndicator;SideMid";
CM_ SG_ 2566908449 SafeWrkSideNear "SafeWorkingIndicator;SideNear";
CM_ SG_ 2566908449 SafeWrkFrFar "SafeWorkingIndicator;FrontFar";
CM_ SG_ 2566908449 SafeWrkFrMid "SafeWorkingIndicator;FrontMid";
CM_ SG_ 2566908449 SafeWrkFrNear "SafeWorkingIndicator;FrontNear";
CM_ SG_ 2566908449 FrMvGuidArmOut "FrontMovementGuide;ArmOut";
CM_ SG_ 2566908449 FrMvGuidArmIn "FrontMovementGuide;ArmIn";
CM_ SG_ 2566908449 FrMvGuidBoomDn "FrontMovementGuide;BoomDown";
CM_ SG_ 2566908449 FrMvGuidBoomUp "FrontMovementGuide:BoomUp";
CM_ SG_ 2566908449 EfenceTrkWrn "E-fenceWarning;Track";
CM_ SG_ 2566908449 EfenceDzWrn "E-fenceWarning;Dozer";
CM_ SG_ 2566908449 EfenceCabWrn "E-fenceWarning;Cabin";
CM_ SG_ 2566908449 EfenceFSwgRhWrn "E-fenceWarning;SwingRight";
CM_ SG_ 2566908449 EfenceFSwgLhWrn "E-fenceWarning;SwingLeft";
CM_ SG_ 2566908449 EfenceCeilWrn "E-fenceWarning;Ceiling";
CM_ SG_ 2566908449 EfenceFloorWrn "E-fenceWarning;Floor";
CM_ SG_ 2566908449 EfenceWallWrn "E-fenceWarning;Wall";
CM_ BO_ 2566908705 "Truck Weighing Group";
CM_ SG_ 2566908705 TipOffMnSt "Tip Off Manual Status";
CM_ SG_ 2566908705 TipOffAstSt "Tip Off Assist Status";
CM_ SG_ 2566908705 TotWhgCurTrk "TotalWeightofcurrenttruck";
CM_ SG_ 2566908705 BckCntCurTrk "BucketCountofcurrenttruck";
CM_ SG_ 2566908705 WghCntSt "WeighingCountStatus";
CM_ SG_ 2566908705 WghSt "WeighingStatus";
CM_ SG_ 2566908705 RelTmBckWhg "RealtimeBucketWeight";
CM_ BO_ 2566908961 "Weighing Calibration Progress Rate";
CM_ SG_ 2566908961 EmcvCalbStep "eMCV Calibration; Step";
CM_ SG_ 2566908961 EmcvCalbStage "eMCV Calibration; Stage";
CM_ SG_ 2566908961 BckSingleFastCalbStep "Bucket Single Fast Calibration; Step";
CM_ SG_ 2566908961 BckSingleFastCalbStage "Bucket Single Fast Calibration; Stage";
CM_ SG_ 2566908961 BckSingleSlowCalbStep "Bucket Single Slow Calibration; Step";
CM_ SG_ 2566908961 BckSingleSlowCalbStage "Bucket Single Slow Calibration; Stage";
CM_ SG_ 2566908961 BckZeroCalbStep "BucketZeroCalibration;Step";
CM_ SG_ 2566908961 BckZeroCalbStage "BucketZeroCalibration;Stage";
CM_ SG_ 2566908961 FrMultiCalbStep "FrontMultiCalibration;Step";
CM_ SG_ 2566908961 FrMultiCalbStage "FrontMultiCalibration;Stage";
CM_ SG_ 2566908961 FrSngCalbStep "FrontSingleCalibration;Step";
CM_ SG_ 2566908961 FrSngCalbStage "FrontSingleCalibration;Stage";
CM_ BO_ 2566909217 "Weighing Calibration Cylinder Velocity";
CM_ SG_ 2566909217 TgtArmCylSpdUpLmt "TargetArmCylinderVelocity;UpperLimit";
CM_ SG_ 2566909217 TgtArmCylSpdLwLmt "TargetArmCylinderVelocity;LowerLimit";
CM_ SG_ 2566909217 CurArmCylSpd "CurrentArmCylinderVelocity";
CM_ SG_ 2566909217 TgtBoomCylSpdUpLmt "TargetBoomCylinderVelocity;UpperLimit";
CM_ SG_ 2566909217 TgtBoomCylSpdLwLmt "TargetBoomCylinderVelocity;LowerLimit";
CM_ SG_ 2566909217 CurBoomCylSpd "CurrentBoomCylinderVelocity";
CM_ BO_ 2566909473 "Weighing Calibration joint Angle";
CM_ SG_ 2566909473 TgtArmJointAngEndPos "TargetArmJointAngle;EndPosition";
CM_ SG_ 2566909473 TgtArmJointAngStartPos "TargetArmJointAngle;StartPosition";
CM_ SG_ 2566909473 CurArmJointAng "CurrentArmJointAngle";
CM_ SG_ 2566909473 TgtBoomJointAngEndPos "TargetBoomJointAngle;EndPosition";
CM_ SG_ 2566909473 TgtBoomJointAngStartPos "TargetBoomJointAngle;StartPosition";
CM_ SG_ 2566909473 CurBoomJointAng "CurrentBoomJointAngle";
CM_ BO_ 2566909729 "Lift Assist Data Group";
CM_ SG_ 2566909729 Reach "Reach";
CM_ SG_ 2566909729 Hight "Hight";
CM_ SG_ 2566909729 RatedLoad "RatedLoad";
CM_ SG_ 2566909729 ActLoad "ActualLoad";
CM_ BO_ 2634018819 "TCU_ID";
CM_ BO_ 2566910241 "Analog Sensor Relay Group";
CM_ SG_ 2566910241 VhcSpdHhRes "Vehicle Speed (High Resolution)";
CM_ SG_ 2566910241 SwgSt "Swing Status";
CM_ SG_ 2566910241 VhcSpdFromSpdSs "Vehicle Speed from Speed Sensor";
CM_ SG_ 2566910241 SwgAng "SwingAngle";
CM_ BO_ 2566910534 "ETC Calibration Message to VCU";
CM_ BO_ 2566912289 "MC Weighing Handshake Group 4";
CM_ SG_ 2566912289 SsOfsRttAng "SensorOffset;RotationAngle";
CM_ SG_ 2566912289 ImuSsOfsTrttTiltAng "IMUSensorOffset;TiltRotatorTiltAngle";
CM_ SG_ 2566912289 TrttBodyDmsnTQ4 "TiltRotatorBodyDimension:TQ4";
CM_ SG_ 2566912289 TrttBodyDmsnDQ4 "TiltRotatorBodyDimension:DQ4";
CM_ SG_ 2566912289 TrttBodyDmsnAngGdt "TiltRotatorBodyDemension;AnlgeGDT";
CM_ SG_ 2566912289 TrttBodyDmsnDT "TiltRotatorBodyDemension;DT";
CM_ SG_ 2566912289 TrttBodyDmsnGT "TiltRotatorBodyDemension;GT";
CM_ SG_ 2566912289 TrttBodyDmsnDG "TiltRotatorBodyDemension;DG";
CM_ SG_ 2566912289 TrttBodyDmsnVW "TiltRotatorBodyDemension;VW";
CM_ SG_ 2566912289 TrttBodyDmsnUV "TiltRotatorBodyDemension;UV";
CM_ SG_ 2566912289 TrttBodyDmsnTU "TiltRotatorBodyDemension;TU";
CM_ SG_ 2566912289 TrttBck05DmsnAngVwn "TiltRotatorBucket05Demension;AnlgeVWN";
CM_ SG_ 2566912289 TrttBck05DmsnTN "TiltRotatorBucket05Demension;TN";
CM_ SG_ 2566912289 TrttBck05DmsnWN "TiltRotatorBucket05Demension;WN";
CM_ SG_ 2566912289 TrttBck05DmsnWT "TiltRotatorBucket05Demension;WT";
CM_ SG_ 2566912289 TrttBck05DmsnNQ3 "TiltRotatorBucket05Demension;NQ3";
CM_ SG_ 2566912289 TrttBck05DmsnWQ3 "TiltRotatorBucket05Demension;WQ3";
CM_ SG_ 2566912289 TrttBck05DmsnNQ2 "TiltRotatorBucket05Demension;NQ2";
CM_ SG_ 2566912289 TrttBck05DmsnWQ2 "TiltRotatorBucket05Demension;WQ2";
CM_ SG_ 2566912289 TrttBck05DmsnWidth "TiltRotatorBucket05Demension;Width";
CM_ SG_ 2566912289 TrttBck05DmsnNQ1 "TiltRotatorBucket05Demension;NQ1";
CM_ SG_ 2566912289 TrttBck05DmsnWQ1 "TiltRotatorBucket05Demension;WQ1";
CM_ SG_ 2566912289 TrttBck04DmsnAngVwn "TiltRotatorBucket04Demension;AnlgeVWN";
CM_ SG_ 2566912289 TrttBck04DmsnTN "TiltRotatorBucket04Demension;TN";
CM_ SG_ 2566912289 TrttBck04DmsnWN "TiltRotatorBucket04Demension;WN";
CM_ SG_ 2566912289 TrttBck04DmsnWT "TiltRotatorBucket04Demension;WT";
CM_ SG_ 2566912289 TrttBck04DmsnNQ3 "TiltRotatorBucket04Demension;NQ3";
CM_ SG_ 2566912289 TrttBck04DmsnWQ3 "TiltRotatorBucket04Demension;WQ3";
CM_ SG_ 2566912289 TrttBck04DmsnNQ2 "TiltRotatorBucket04Demension;NQ2";
CM_ SG_ 2566912289 TrttBck04DmsnWQ2 "TiltRotatorBucket04Demension;WQ2";
CM_ SG_ 2566912289 TrttBck04DmsnWidth "TiltRotatorBucket04Demension;Width";
CM_ SG_ 2566912289 TrttBck04DmsnNQ1 "TiltRotatorBucket04Demension;NQ1";
CM_ SG_ 2566912289 TrttBck04DmsnWQ1 "TiltRotatorBucket04Demension;WQ1";
CM_ SG_ 2566912289 TrttBck03DmsnAngVwn "TiltRotatorBucket03Demension;AnlgeVWN";
CM_ SG_ 2566912289 TrttBck03DmsnTN "TiltRotatorBucket03Demension;TN";
CM_ SG_ 2566912289 TrttBck03DmsnWN "TiltRotatorBucket03Demension;WN";
CM_ SG_ 2566912289 TrttBck03DmsnWT "TiltRotatorBucket03Demension;WT";
CM_ SG_ 2566912289 TrttBck03DmsnNQ3 "TiltRotatorBucket03Demension;NQ3";
CM_ SG_ 2566912289 TrttBck03DmsnWQ3 "TiltRotatorBucket03Demension;WQ3";
CM_ SG_ 2566912289 TrttBck03DmsnNQ2 "TiltRotatorBucket03Demension;NQ2";
CM_ SG_ 2566912289 TrttBck03DmsnWQ2 "TiltRotatorBucket03Demension;WQ2";
CM_ SG_ 2566912289 TrttBck03DmsnWidth "TiltRotatorBucket03Demension;Width";
CM_ SG_ 2566912289 TrttBck03DmsnNQ1 "TiltRotatorBucket03Demension;NQ1";
CM_ SG_ 2566912289 TrttBck03DmsnWQ1 "TiltRotatorBucket03Demension;WQ1";
CM_ SG_ 2566912289 TrttBck02DmsnAngVwn "TiltRotatorBucket02Demension;AnlgeVWN";
CM_ SG_ 2566912289 TrttBck02DmsnTN "TiltRotatorBucket02Demension;TN";
CM_ SG_ 2566912289 TrttBck02DmsnWN "TiltRotatorBucket02Demension;WN";
CM_ SG_ 2566912289 TrttBck02DmsnWT "TiltRotatorBucket02Demension;WT";
CM_ SG_ 2566912289 TrttBck02DmsnNQ3 "TiltRotatorBucket02Demension;NQ3";
CM_ SG_ 2566912289 TrttBck02DmsnWQ3 "TiltRotatorBucket02Demension;WQ3";
CM_ SG_ 2566912289 TrttBck02DmsnNQ2 "TiltRotatorBucket02Demension;NQ2";
CM_ SG_ 2566912289 TrttBck02DmsnWQ2 "TiltRotatorBucket02Demension;WQ2";
CM_ SG_ 2566912289 TrttBck02DmsnWidth "TiltRotatorBucket02Demension;Width";
CM_ SG_ 2566912289 TrttBck02DmsnNQ1 "TiltRotatorBucket02Demension;NQ1";
CM_ SG_ 2566912289 TrttBck02DmsnWQ1 "TiltRotatorBucket02Demension;WQ1";
CM_ SG_ 2566912289 TrttBck01DmsnAngVwn "TiltRotatorBucket01Demension;AnlgeVWN";
CM_ SG_ 2566912289 TrttBck01DmsnTN "TiltRotatorBucket01Demension;TN";
CM_ SG_ 2566912289 TrttBck01DmsnWN "TiltRotatorBucket01Demension;WN";
CM_ SG_ 2566912289 TrttBck01DmsnWT "TiltRotatorBucket01Demension;WT";
CM_ SG_ 2566912289 TrttBck01DmsnNQ3 "TiltRotatorBucket01Demension;NQ3";
CM_ SG_ 2566912289 TrttBck01DmsnWQ3 "TiltRotatorBucket01Demension;WQ3";
CM_ SG_ 2566912289 TrttBck01DmsnNQ2 "TiltRotatorBucket01Demension;NQ2";
CM_ SG_ 2566912289 TrttBck01DmsnWQ2 "TiltRotatorBucket01Demension;WQ2";
CM_ SG_ 2566912289 TrttBck01DmsnWidth "TiltRotatorBucket01Demension;Width";
CM_ SG_ 2566912289 TrttBck01DmsnNQ1 "TiltRotatorBucket01Demension;NQ1";
CM_ SG_ 2566912289 TrttBck01DmsnWQ1 "TiltRotatorBucket01Demension;WQ1";
CM_ BO_ 2566912545 "MC Weighing Handshake Group 1";
CM_ SG_ 2566912545 Bck05DmsnAngGdn "Bucket05Demension;AnlgeGDN(theta4)";
CM_ SG_ 2566912545 Bck05DmsnDT "Bucket05Demension;DT";
CM_ SG_ 2566912545 Bck05DmsnNQ3 "Bucket05Demension;NQ3";
CM_ SG_ 2566912545 Bck05DmsnDQ3 "Bucket05Demension;DQ3";
CM_ SG_ 2566912545 Bck05DmsnNQ2 "Bucket05Demension;NQ2";
CM_ SG_ 2566912545 Bck05DmsnDQ2 "Bucket05Demension;DQ2";
CM_ SG_ 2566912545 Bck05DmsnTN "Bucket05Demension;TN";
CM_ SG_ 2566912545 Bck05DmsnWidth "Bucket05Demension;Width";
CM_ SG_ 2566912545 Bck05DmsnNQ1 "Bucket05Demension;NQ1";
CM_ SG_ 2566912545 Bck05DmsnDQ1 "Bucket05Demension;DQ1";
CM_ SG_ 2566912545 Bck05DmsnDN "Bucket05Demension;DN";
CM_ SG_ 2566912545 Bck05DmsnDG "Bucket05Demension;DG";
CM_ SG_ 2566912545 Bck04DmsnAngGdn "Bucket04Demension;AnlgeGDN(theta4)";
CM_ SG_ 2566912545 Bck04DmsnDT "Bucket04Demension;DT";
CM_ SG_ 2566912545 Bck04DmsnNQ3 "Bucket04Demension;NQ3";
CM_ SG_ 2566912545 Bck04DmsnDQ3 "Bucket04Demension;DQ3";
CM_ SG_ 2566912545 Bck04DmsnNQ2 "Bucket04Demension;NQ2";
CM_ SG_ 2566912545 Bck04DmsnDQ2 "Bucket04Demension;DQ2";
CM_ SG_ 2566912545 Bck04DmsnTN "Bucket04Demension;TN";
CM_ SG_ 2566912545 Bck04DmsnWidth "Bucket04Demension;Width";
CM_ SG_ 2566912545 Bck04DmsnNQ1 "Bucket04Demension;NQ1";
CM_ SG_ 2566912545 Bck04DmsnDQ1 "Bucket04Demension;DQ1";
CM_ SG_ 2566912545 Bck04DmsnDN "Bucket04Demension;DN";
CM_ SG_ 2566912545 Bck04DmsnDG "Bucket04Demension;DG";
CM_ SG_ 2566912545 Bck03DmsnAngGdn "Bucket03Demension;AnlgeGDN(theta4)";
CM_ SG_ 2566912545 Bck03DmsnDT "Bucket03Demension;DT";
CM_ SG_ 2566912545 Bck03DmsnNQ3 "Bucket03Demension;NQ3";
CM_ SG_ 2566912545 Bck03DmsnDQ3 "Bucket03Demension;DQ3";
CM_ SG_ 2566912545 Bck03DmsnNQ2 "Bucket03Demension;NQ2";
CM_ SG_ 2566912545 Bck03DmsnDQ2 "Bucket03Demension;DQ2";
CM_ SG_ 2566912545 Bck03DmsnTN "Bucket03Demension;TN";
CM_ SG_ 2566912545 Bck03DmsnWidth "Bucket03Demension;Width";
CM_ SG_ 2566912545 Bck03DmsnNQ1 "Bucket03Demension;NQ1";
CM_ SG_ 2566912545 Bck03DmsnDQ1 "Bucket03Demension;DQ1";
CM_ SG_ 2566912545 Bck03DmsnDN "Bucket03Demension;DN";
CM_ SG_ 2566912545 Bck03DmsnDG "Bucket03Demension;DG";
CM_ SG_ 2566912545 Bck02DmsnAngGdn "Bucket02Demension;AnlgeGDN(theta4)";
CM_ SG_ 2566912545 Bck02DmsnDT "Bucket02Demension;DT";
CM_ SG_ 2566912545 Bck02DmsnNQ3 "Bucket02Demension;NQ3";
CM_ SG_ 2566912545 Bck02DmsnDQ3 "Bucket02Demension;DQ3";
CM_ SG_ 2566912545 Bck02DmsnNQ2 "Bucket02Demension;NQ2";
CM_ SG_ 2566912545 Bck02DmsnDQ2 "Bucket02Demension;DQ2";
CM_ SG_ 2566912545 Bck02DmsnTN "Bucket02Demension;TN";
CM_ SG_ 2566912545 Bck02DmsnWidth "Bucket02Demension;Width";
CM_ SG_ 2566912545 Bck02DmsnNQ1 "Bucket02Demension;NQ1";
CM_ SG_ 2566912545 Bck02DmsnDQ1 "Bucket02Demension;DQ1";
CM_ SG_ 2566912545 Bck02DmsnDN "Bucket02Demension;DN";
CM_ SG_ 2566912545 Bck02DmsnDG "Bucket02Demension;DG";
CM_ SG_ 2566912545 Bck01DmsnAngGdn "Bucket01Demension;AnlgeGDN(theta4)";
CM_ SG_ 2566912545 Bck01DmsnDT "Bucket01Demension;DT";
CM_ SG_ 2566912545 Bck01DmsnNQ3 "Bucket01Demension;NQ3";
CM_ SG_ 2566912545 Bck01DmsnDQ3 "Bucket01Demension;DQ3";
CM_ SG_ 2566912545 Bck01DmsnNQ2 "Bucket01Demension;NQ2";
CM_ SG_ 2566912545 Bck01DmsnDQ2 "Bucket01Demension;DQ2";
CM_ SG_ 2566912545 Bck01DmsnTN "Bucket01Demension;TN";
CM_ SG_ 2566912545 Bck01DmsnWidth "Bucket01Demension;Width";
CM_ SG_ 2566912545 Bck01DmsnNQ1 "Bucket01Demension;NQ1";
CM_ SG_ 2566912545 Bck01DmsnDQ1 "Bucket01Demension;DQ1";
CM_ SG_ 2566912545 Bck01DmsnDN "Bucket01Demension;DN";
CM_ SG_ 2566912545 Bck01DmsnDG "Bucket01Demension;DG";
CM_ BO_ 2566912801 "MC Weighing Handshake Group 2";
CM_ SG_ 2566912801 JoyFuncAssnRhBtn14 "Joystick Function Assign; R.H. Button 14";
CM_ SG_ 2566912801 JoyFuncAssnRhBtn13 "Joystick Function Assign; R.H. Button 13";
CM_ SG_ 2566912801 JoyFuncAssnRhBtn12 "Joystick Function Assign; R.H. Button 12";
CM_ SG_ 2566912801 JoyFuncAssnRhBtn11 "Joystick Function Assign; R.H. Button 11";
CM_ SG_ 2566912801 JoyFuncAssnLhBtn14 "Joystick Function Assign; L.H. Button 14";
CM_ SG_ 2566912801 JoyFuncAssnLhBtn13 "Joystick Function Assign; L.H. Button 13";
CM_ SG_ 2566912801 JoyFuncAssnLhBtn12 "Joystick Function Assign; L.H. Button 12";
CM_ SG_ 2566912801 JoyFuncAssnLhBtn11 "Joystick Function Assign; L.H. Button 11";
CM_ SG_ 2566912801 DacCoordinateSystem "Setting;SetDACCoordinateSystem";
CM_ SG_ 2566912801 DacAutoMdSelect "CMD;DACAutoModeSelect";
CM_ SG_ 2566912801 CrwTipCalbLen "CrawlerTipCalibrationLength";
CM_ SG_ 2566912801 ImuSsOfsBladeRoll "IMUSensorOffset;Blade Roll";
CM_ SG_ 2566912801 ImuSsOfsBladePch "IMUSensorOffset;BladePitch";
CM_ SG_ 2566912801 ImuSsOfsCfrmRoll "IMUSensorOffset;C-frameRoll";
CM_ SG_ 2566912801 ImuSsOfsCfrmPch "IMUSensorOffset;C-framePitch";
CM_ SG_ 2566912801 BladeTipCalbLen "Bladetipcalibrationlength";
CM_ SG_ 2566912801 BladeJointCalbLen "BladeJointCalibrationLength";
CM_ SG_ 2566912801 GrdAstPrfDsnDt01PntZ09 "GradeAssistProfileDesignData01;PointZ09";
CM_ SG_ 2566912801 GrdAstPrfDsnDt01PntY09 "GradeAssistProfileDesignData01;PointY09";
CM_ SG_ 2566912801 GrdAstPrfDsnDt01PntZ08 "GradeAssistProfileDesignData01;PointZ08";
CM_ SG_ 2566912801 GrdAstPrfDsnDt01PntY08 "GradeAssistProfileDesignData01;PointY08";
CM_ SG_ 2566912801 GrdAstPrfDsnDt01PntZ07 "GradeAssistProfileDesignData01;PointZ07";
CM_ SG_ 2566912801 GrdAstPrfDsnDt01PntY07 "GradeAssistProfileDesignData01;PointY07";
CM_ SG_ 2566912801 GrdAstPrfDsnDt01PntZ06 "GradeAssistProfileDesignData01;PointZ06";
CM_ SG_ 2566912801 GrdAstPrfDsnDt01PntY06 "GradeAssistProfileDesignData01;PointY06";
CM_ SG_ 2566912801 GrdAstPrfDsnDt01PntZ05 "GradeAssistProfileDesignData01;PointZ05";
CM_ SG_ 2566912801 GrdAstPrfDsnDt01PntY05 "GradeAssistProfileDesignData01;PointY05";
CM_ SG_ 2566912801 GrdAstPrfDsnDt01PntZ04 "GradeAssistProfileDesignData01;PointZ04";
CM_ SG_ 2566912801 GrdAstPrfDsnDt01PntY04 "GradeAssistProfileDesignData01;PointY04";
CM_ SG_ 2566912801 GrdAstPrfDsnDt01PntZ03 "GradeAssistProfileDesignData01;PointZ03";
CM_ SG_ 2566912801 GrdAstPrfDsnDt01PntY03 "GradeAssistProfileDesignData01;PointY03";
CM_ SG_ 2566912801 GrdAstPrfDsnDt01PntZ02 "GradeAssistProfileDesignData01;PointZ02";
CM_ SG_ 2566912801 GrdAstPrfDsnDt01PntY02 "GradeAssistProfileDesignData01;PointY02";
CM_ SG_ 2566912801 GrdAstPrfDsnDt01PntZ01 "GradeAssistProfileDesignData01;PointZ01";
CM_ SG_ 2566912801 GrdAstPrfDsnDt01PntY01 "GradeAssistProfileDesignData01;PointY01";
CM_ SG_ 2566912801 CrossSlopeDsnDt "CrossSlopeDesignData";
CM_ SG_ 2566912801 SlopeDsnDt "SlopeDesignData";
CM_ SG_ 2566912801 DepthDsnDt "DepthDesignData";
CM_ SG_ 2566912801 JoyFuncAssnRhThw05 "JoystickFunctionAssign;R.H.ThumbWheel05";
CM_ SG_ 2566912801 JoyFuncAssnRhThw04 "JoystickFunctionAssign;R.H.ThumbWheel04";
CM_ SG_ 2566912801 JoyFuncAssnRhThw03 "JoystickFunctionAssign;R.H.ThumbWheel03";
CM_ SG_ 2566912801 JoyFuncAssnRhThw02 "JoystickFunctionAssign;R.H.ThumbWheel02";
CM_ SG_ 2566912801 JoyFuncAssnRhThw01 "JoystickFunctionAssign;R.H.ThumbWheel01";
CM_ SG_ 2566912801 JoyFuncAssnLhThw05 "JoystickFunctionAssign;L.H.ThumbWheel05";
CM_ SG_ 2566912801 JoyFuncAssnLhThw04 "JoystickFunctionAssign;L.H.ThumbWheel04";
CM_ SG_ 2566912801 JoyFuncAssnLhThw03 "JoystickFunctionAssign;L.H.ThumbWheel03";
CM_ SG_ 2566912801 JoyFuncAssnLhThw02 "JoystickFunctionAssign;L.H.ThumbWheel02";
CM_ SG_ 2566912801 JoyFuncAssnLhThw01 "JoystickFunctionAssign;L.H.ThumbWheel01";
CM_ SG_ 2566912801 JoyFuncAssnRhBtn10 "JoystickFunctionAssign;R.H.Button10";
CM_ SG_ 2566912801 JoyFuncAssnRhBtn09 "JoystickFunctionAssign;R.H.Button09";
CM_ SG_ 2566912801 JoyFuncAssnRhBtn08 "JoystickFunctionAssign;R.H.Button08";
CM_ SG_ 2566912801 JoyFuncAssnRhBtn07 "JoystickFunctionAssign;R.H.Button07";
CM_ SG_ 2566912801 JoyFuncAssnRhBtn06 "JoystickFunctionAssign;R.H.Button06";
CM_ SG_ 2566912801 JoyFuncAssnRhBtn05 "JoystickFunctionAssign;R.H.Button05";
CM_ SG_ 2566912801 JoyFuncAssnRhBtn04 "JoystickFunctionAssign;R.H.Button04";
CM_ SG_ 2566912801 JoyFuncAssnRhBtn03 "JoystickFunctionAssign;R.H.Button03";
CM_ SG_ 2566912801 JoyFuncAssnRhBtn02 "JoystickFunctionAssign;R.H.Button02";
CM_ SG_ 2566912801 JoyFuncAssnRhBtn01 "JoystickFunctionAssign;R.H.Button01";
CM_ SG_ 2566912801 JoyFuncAssnLhBtn10 "JoystickFunctionAssign;L.H.Button10";
CM_ SG_ 2566912801 JoyFuncAssnLhBtn09 "JoystickFunctionAssign;L.H.Button09";
CM_ SG_ 2566912801 JoyFuncAssnLhBtn08 "JoystickFunctionAssign;L.H.Button08";
CM_ SG_ 2566912801 JoyFuncAssnLhBtn07 "JoystickFunctionAssign;L.H.Button07";
CM_ SG_ 2566912801 JoyFuncAssnLhBtn06 "JoystickFunctionAssign;L.H.Button06";
CM_ SG_ 2566912801 JoyFuncAssnLhBtn05 "JoystickFunctionAssign;L.H.Button05";
CM_ SG_ 2566912801 JoyFuncAssnLhBtn04 "JoystickFunctionAssign;L.H.Button04";
CM_ SG_ 2566912801 JoyFuncAssnLhBtn03 "JoystickFunctionAssign;L.H.Button03";
CM_ SG_ 2566912801 JoyFuncAssnLhBtn02 "JoystickFunctionAssign;L.H.Button02";
CM_ SG_ 2566912801 JoyFuncAssnLhBtn01 "JoystickFunctionAssign;L.H.Button01";
CM_ SG_ 2566912801 ImuSsOfsBucket "IMUSensorOffset;Bucket";
CM_ SG_ 2566912801 ImuSsOfsArtiArmPch "IMUSensorOffset;ArtiArmPitch";
CM_ SG_ 2566912801 ImuSsOfsArmPch "IMUSensorOffset;ArmPitch";
CM_ SG_ 2566912801 ImuSsOfsBoomPch "IMUSensorOffset;BoomPitch";
CM_ SG_ 2566912801 ImuSsOfsBodyRoll "IMUSensorOffset;BodyRoll";
CM_ SG_ 2566912801 ImuSsOfsBodyPch "IMUSensorOffset;BodyPitch";
CM_ SG_ 2566912801 SelectedBucketNo "SelectedBucketNumber";
CM_ BO_ 2566913057 "MC Weighing Handshake Group 3";
CM_ SG_ 2566913057 MaterialName "MaterialName";
CM_ SG_ 2566913057 TrkName "TruckName";
CM_ SG_ 2566913057 BchmkZOfs "BenchmarkZOffset";
CM_ SG_ 2566913057 BchmkYOfs "BenchmarkYOffset";
CM_ SG_ 2566913057 BchmkXOfs "BenchmarkXOffset";
CM_ SG_ 2566913057 TrkCount "TruckCount";
CM_ SG_ 2566913057 SelMaterialDensity "SelectedMaterialDensity";
CM_ SG_ 2566913057 SelTrkTgtWgh "SelectedTruckTargetWeight";
CM_ SG_ 2566913057 BckRefPnt "BucketReferencePoint";
CM_ SG_ 2566913057 ArtiBoomDmsnOpt "OptSetting;ArtiBoomDemensionOption";
CM_ SG_ 2566913057 ArmDmsnOpt "OptSetting;ArmDemensionOption";
CM_ SG_ 2566913057 BoomDmsnOpt "OptSetting;BoomDemensionOption";
CM_ SG_ 2566913057 SetExcessiveDigPrt "Setting; Excessive Digging Prevention";
CM_ SG_ 2566913057 GrdAstMd "GradeAssistMode";
CM_ SG_ 2566913057 GrdAstAccuracy "GradeAssistAccuracy";
CM_ SG_ 2566913057 TrkShoeWidth "TrackShoeWidth";
CM_ BO_ 2566913313 "MC Weighing Target Set Value";
CM_ SG_ 2566913313 EfenceTgSetSideWallR "E-Fence Target Set; Side Wall Right";
CM_ SG_ 2566913313 EfenceTgSetSideWallL "E-Fence Target Set; Side Wall Left";
CM_ SG_ 2566913313 EfenceTgSetCabin "E-Fence Target Set; Cabin";
CM_ SG_ 2566913313 SwgAstAngTgtSetSwgLh "SwingAssistAngleTargetSet;SwingLeft";
CM_ SG_ 2566913313 SwgAstAngTgtSetSwgRh "SwingAssistAngleTargetSet;SwingRight";
CM_ SG_ 2566913313 EfenceTgtSetSwgRh "E-FenceTargetSet;SwingRight";
CM_ SG_ 2566913313 EfenceTgtSetSwgLh "E-FenceTargetSet;SwingLeft";
CM_ SG_ 2566913313 EfenceTgtSetCeil "E-FenceTargetSet;Ceiling";
CM_ SG_ 2566913313 EfenceTgtSetFloor "E-FenceTargetSet;Floor";
CM_ SG_ 2566913313 EfenceTgtSetWall "E-FenceTargetSet;Wall";
CM_ BO_ 2566913569 "MC Truck Store Information";
CM_ SG_ 2566913569 CompanyName "Company Name";
CM_ SG_ 2566913569 TgWghofCurTrk "Target Weight of Current Truck";
CM_ SG_ 2566913569 TrkCntFinalTm "Truck Count Final Time";
CM_ SG_ 2566913569 MaterialLoadSt "MaterialsLoadingStatus";
CM_ SG_ 2566913569 TotWghCurTrk "TotalWeightofcurrenttruck";
CM_ SG_ 2566913569 BckCntCurTrk "BucketCountofcurrenttruck";
CM_ SG_ 2566913569 MtrDensity "SelectedMaterialDensity";
CM_ SG_ 2566913569 MtrName "MaterialName";
CM_ SG_ 2566913569 TrkName "TruckName";
CM_ BO_ 2566913825 "MC Accumulated Weighing Information";
CM_ SG_ 2566913825 TotAcmtWgh "TotalAccumulatedWeight";
CM_ SG_ 2566913825 TotAcmtBckCnt "TotalAccumulatedBucketCount";
CM_ BO_ 2583646241 "Front Pump Spool Stroke Command";
CM_ SG_ 2583646241 TrvlLhSpoolCmd "Travelleftspoolcommnad";
CM_ SG_ 2583646241 ArmConfSpoolCmd "Armconfluencespoolcommand";
CM_ SG_ 2583646241 BckSpoolCmd "Bucketspoolcommand";
CM_ SG_ 2583646241 BoomSpoolCmd "Boomspoolcommand";
CM_ BO_ 2583646497 "Rear Pump Spool Stroke Command";
CM_ SG_ 2583646497 TrvlrightSpoolCmd "Travelrightspoolcommnad";
CM_ SG_ 2583646497 BoomConfSpoolCmd "Boomconfluencespoolcommand";
CM_ SG_ 2583646497 SwgSpoolCmd "Swingspoolcommand";
CM_ SG_ 2583646497 ArmSpoolCmd "Armspoolcommand";
CM_ BO_ 2583646753 "Option Spool Stroke Command";
CM_ SG_ 2583646753 ArtiBoomConfSpoolCmd "Artiboomconfluencespoolcommand";
CM_ SG_ 2583646753 DzSpoolCmd "Dozerspoolcommand";
CM_ SG_ 2583646753 OptSpoolCmd "Optionspoolcommand";
CM_ BO_ 2583651424 "Front Pump Delayed Spool Stroke Command";
CM_ SG_ 2583651424 TrvlleftSplDlyCmd "Travelleftspooldelayedcommnad";
CM_ SG_ 2583651424 BckSplDlyCmd "Bucketspooldelayedcommand";
CM_ SG_ 2583651424 ArmCnfSplDlyCmd "Armconfluencespooldelayedcommand";
CM_ SG_ 2583651424 BoomSplDlyCmd "Boomspooldelayedcommand";
CM_ BO_ 2583651680 "Rear Pump Delayed Spool Stroke Command";
CM_ SG_ 2583651680 TrvlrightSplDlyCmd "Travelrightspooldelayedcommnad";
CM_ SG_ 2583651680 SwgSplDlyCmd "Swingspooldelayedcommand";
CM_ SG_ 2583651680 BoomCnfSplDlyCmd "Boomconfluencespooldelayedcommand";
CM_ SG_ 2583651680 ArmSplDlyCmd "Armspooldelayedcommand";
CM_ BO_ 2583651936 "Option Delayed Spool Stroke Command";
CM_ SG_ 2583651936 ArtiboomSplDlyCmd "Artiboomspooldelayedcommand";
CM_ SG_ 2583651936 DzSplDlyCmd "Dozerspooldelayedcommand";
CM_ SG_ 2583651936 OptSplDlyCmd "Optionspooldelayedcommand";
CM_ BO_ 2583654752 "Boom Bucket EPPR Feedback Current";
CM_ SG_ 2583654752 BckdumpEpprFdbkCur "Bucketdumpepprfeedbackcurrent";
CM_ SG_ 2583654752 BckcrowdEpprFdbkCur "Bucketcrowdepprfeedbackcurrent";
CM_ SG_ 2583654752 BoomDnEpprFdbkCur "Boomdownepprfeedbackcurrent";
CM_ SG_ 2583654752 BoomupEpprFdbkCur "Boomupepprfeedbackcurrent";
CM_ BO_ 2583655008 "Arm Swing EPPR Feedback Current";
CM_ SG_ 2583655008 SwgREpprFdbkCur "Swingrightepprfeedbackcurrent";
CM_ SG_ 2583655008 SwgLEpprFdbkCur "Swingleftepprfeedbackcurrent";
CM_ SG_ 2583655008 ArmdumpEpprFdbkCur "Armdumpepprfeedbackcurrent";
CM_ SG_ 2583655008 ArmcrowdEpprFdbkCur "Armcrowdepprfeedbackcurrent";
CM_ BO_ 2583655264 "Confluence EPPR Feedback Current";
CM_ SG_ 2583655264 ArmCnfdumpEpprFdbkCur "Armconfluencedumpepprfeedbackcurrent";
CM_ SG_ 2583655264 ArmCnfcrowdEpprFdbkCur "Armconfluencecrowdepprfeedbackcurrent";
CM_ SG_ 2583655264 BoomCnfEpprFdbkCur "Boomconfluenceepprfeedbackcurrent";
CM_ BO_ 2583655520 "Option EPPR Feedback Current";
CM_ SG_ 2583655520 OpenEpprFdbkCur "Openepprfeedbackcurrent";
CM_ SG_ 2583655520 CloseEpprFdbkCur "Closeepprfeedbackcurrent";
CM_ BO_ 2583655776 "Travel EPPR Feedback Current";
CM_ SG_ 2583655776 TrvlRBwdEpprFdbkCur "Travelrightbackwardepprfeedbackcurrent";
CM_ SG_ 2583655776 TrvlRFwdEpprFdbkCur "Travelrightforwardepprfeedbackcurrent";
CM_ SG_ 2583655776 TrvlLBwdEpprFdbkCur "Travelleftbackwardepprfeedbackcurrent";
CM_ SG_ 2583655776 TrvlLFwdEpprFdbkCur "Travelleftforwardepprfeedbackcurrent";
CM_ BO_ 2583656032 "Boom Bucket Head Rod Pressure";
CM_ SG_ 2583656032 BoomCylHead2Prs "Boom cylinder head 2 pressure";
CM_ SG_ 2583656032 BoomCylRodPrs "Boomcylinderrodpressure";
CM_ SG_ 2583656032 BoomCylHeadPrs "Boomcylinderheadpressure";
CM_ BO_ 2583656288 "Arm Head Rod Pressure";
CM_ SG_ 2583656288 BckCylRodPrs "Bucket cylinder rod pressure";
CM_ SG_ 2583656288 BckCylHeadPrs "Bucket cylinder head pressure";
CM_ SG_ 2583656288 ArmCylRodPrs "Armcylinderrodpressure";
CM_ SG_ 2583656288 ArmCylHeadPrs "Armcylinderheadpressure";
CM_ BO_ 2583656544 "Cylinder Pressure Sensor FMI";
CM_ SG_ 2583656544 BckCylRodPrsSsFmi "Bucket cylinder rod pressure sensor FMI";
CM_ SG_ 2583656544 BckCylHeadPrsSsFmi "Bucket cylinder head pressure sensor FMI";
CM_ SG_ 2583656544 BoomHead2PrsSsFmi "Boom Head2 pressure sensor FMI";
CM_ SG_ 2583656544 ArmCylRodPrsSsFmi "ArmcylinderrodpressuresensorFMI";
CM_ SG_ 2583656544 ArmCylHeadPrsSsFmi "ArmcylinderheadpressuresensorFMI";
CM_ SG_ 2583656544 BoomCylRodPrsSsFmi "BoomcylinderrodpressuresensorFMI";
CM_ SG_ 2583656544 BoomCylHeadPrsSsFmi "BoomcylinderheadpressuresensorFMI";
CM_ BO_ 2583656800 "Valve Pilot Pressure";
CM_ SG_ 2583656800 PtPltPrs "Ptpilotpressure";
CM_ SG_ 2583656800 PaPltPrs "Papilotpressure";
CM_ SG_ 2583656800 BckcrowdEpprPltPrs "Bucketcrowdepprpilotpressure";
CM_ SG_ 2583656800 ArmcrowdEpprPltPrs "Armcrowdepprpilotpressure";
CM_ SG_ 2583656800 BoomDnEpprPltPrs "Boomdownepprpilotpressure";
CM_ BO_ 2583658592 "Valve Pilot Pressure Senaor FMI";
CM_ SG_ 2583658592 PtPltPrsSsFmi "Pt pilot pressure sensor FMI";
CM_ SG_ 2583658592 PaPltPrsSsFmi "Pa pilot pressure sensor FMI";
CM_ SG_ 2583658592 BckcrowdEpprPltPrsSsFmi "Bucket crowd eppr pilot pressure sensor FMI ";
CM_ SG_ 2583658592 ArmcrowdEpprPltPrsSsFmi "Arm crowd eppr pilot pressure sensor FMI";
CM_ SG_ 2583658592 BoomDnEpprPltPrsSsFmi "Boom down eppr pilot pressure sensor FMI";
CM_ BO_ 2583658848 "Pilot Cutoff State";
CM_ SG_ 2583658848 PltCutoffsolVvFmi "Pilot cutoff sol valve FMI";
CM_ SG_ 2583658848 PltCutoffsolVvCmd "Pilot cutoff sol valve command";
CM_ SG_ 2583658848 PltCutoffsolVvSwSt "Pilot cutoff sol valve switch state";
CM_ BO_ 2583667233 "Center Bypass Current Command";
CM_ SG_ 2583667233 Bypass2EpprCmd "bypass2 eppr command";
CM_ SG_ 2583667233 Bypass1EpprCmd "bypass1 eppr command";
CM_ BO_ 2583683873 "Front Joystick Pilot Pressure";
CM_ SG_ 2583683873 SwgStrkPltPrs "Swing stroke pilot pressure";
CM_ SG_ 2583683873 ArmDumpStrkPltPrs "Arm dump stroke pilot pressure";
CM_ SG_ 2583683873 ArmCrowdStrkPltPrs "Arm crowd stroke pilot pressure";
CM_ SG_ 2583683873 BckDumpStrkPltPrs "Bucket dump stroke pilot pressure";
CM_ SG_ 2583683873 BckCrowdStrkPltPrs "Bucket crowd stroke pilot pressure";
CM_ SG_ 2583683873 BoomDnStrkPltPrs "Boom down stroke pilot pressure";
CM_ SG_ 2583683873 BoomUpStrkPltPrs "Boom up stroke pilot pressure";
CM_ BO_ 2583684129 "Travel Joystick Pilot Pressure";
CM_ SG_ 2583684129 TrvlRStrkPltPrs "Travel right stroke pilot pressure";
CM_ SG_ 2583684129 TrvlLStrkPltPrs "Travel left stroke pilot pressure";
CM_ BO_ 2583684385 "VBO Flow Data";
CM_ SG_ 2583684385 Pmp2ActFlow "Pump2 actual flow";
CM_ SG_ 2583684385 Pmp1ActFlow "Pump1 actual flow";
CM_ SG_ 2583684385 Pmp2FlowCmd "Pump2 flow command";
CM_ SG_ 2583684385 Pmp1FlowCmd "Pump1 flow command";
CM_ SG_ 2583684385 Pmp2ReqrFlow "Pump2 required flow";
CM_ SG_ 2583684385 Pmp1ReqrFlow "Pump1 required flow";
CM_ BO_ 2583684641 "VBO Pump1 Data";
CM_ SG_ 2583684641 Pmp1ActPrs "Pump1 actual pressure";
CM_ SG_ 2583684641 Pmp1PrsCmdviasystemPrsCtrl "Pump1 pressure command via system pressure control";
CM_ SG_ 2583684641 Pmp1PrsCmdviaTrqCtrl "Pump1 pressure command via torque control";
CM_ SG_ 2583684641 Pmp1PrsCmdviaFlowCtrl "Pump1 pressure command via flow control";
CM_ SG_ 2583684641 Pmp1finalPrsCmd "Pump1 final pressure command";
CM_ BO_ 2583684897 "VBO Pump2 Data";
CM_ SG_ 2583684897 Pmp2ActPrs "Pump2 actual pressure";
CM_ SG_ 2583684897 Pmp2PrsCmdviasystemPrsCtrl "Pump2 pressure command via system pressure control";
CM_ SG_ 2583684897 Pmp2PrsCmdviaTrqCtrl "Pump2 pressure command via torque control";
CM_ SG_ 2583684897 Pmp2PrsCmdviaFlowCtrl "Pump2 pressure command via flow control";
CM_ SG_ 2583684897 Pmp2finalPrsCmd "Pump2 final pressure command";
CM_ BO_ 2583685153 "VBO Torque Data";
CM_ SG_ 2583685153 RefPowShftEnb "ReferencevalueforPowershiftenable";
CM_ SG_ 2583685153 PmpActTrq "Pumpactualtorque";
CM_ SG_ 2583685153 PmpCmdTrq "Pumpcommandtorque";
CM_ SG_ 2583685153 TrqCmdLever "Torquecommandvialever";
CM_ SG_ 2583685153 TrqCmdLmt "Torquecommandlimit";
CM_ SG_ 2583685153 PidCtrlResult "PIDcontrolresult";
CM_ SG_ 2583685153 TrqCmdTrqCtrl "Torquecommandviatorquecontrol";
CM_ SG_ 2583685153 TrqCmdPowShftCtrl "Torquecommandviapowershiftcontrol";
CM_ BO_ 2583685409 "VBO Spool  Feedback Current  ";
CM_ SG_ 2583685409 Byp2SplEpprFdbkCur "Bypass2 spool eppr feedback current";
CM_ SG_ 2583685409 Byp1SplEpprFdbkCur "Bypass1 spool eppr feedback current";
CM_ SG_ 2583685409 Boom2SplEpprFdbkCur "Boom2 spool eppr feedback current";
CM_ SG_ 2583685409 Bck2SplEpprFdbkCur "Bucket2 spool eppr feedback current";
CM_ SG_ 2583685409 Arm2SplEpprFdbkCur "Arm2 spool eppr feedback current";
CM_ SG_ 2583685409 ArmLckSplEpprFdbkCur "Arm lock spool eppr feedback current";
CM_ BO_ 2583685665 "VBO Spool Pilot Pressure   ";
CM_ SG_ 2583685665 BoomCnfSplPltPrs "Boom confluence spool pilot pressure";
CM_ SG_ 2583685665 BckCnfSplPltPrs "Bucket confluence spool pilot pressure";
CM_ SG_ 2583685665 ArmCnfSplPltPrs "Arm confluence spool pilot pressure";
CM_ SG_ 2583685665 ArmLckSplPltPrs "Arm lock spool pilot pressure";
CM_ BO_ 2583685921 "VBO Pump Angle Data";
CM_ SG_ 2583685921 ReaRpmpEpprFdbkCur "RearpumpEPPRfeedbackcurrent";
CM_ SG_ 2583685921 FrPmpEpprFdbkCur "FrontpumpEPPRfeedbackcurrent";
CM_ SG_ 2583685921 FrPmpAngVlt "Frontpumpanglevoltage";
CM_ SG_ 2583685921 ReaRpmpAngVlt "Rearpumpanglevoltage";
CM_ BO_ 2583686177 "Vbo Temperature Data  ";
CM_ SG_ 2583686177 FrPmpAngVlt "Frontpumpanglevoltage";
CM_ SG_ 2583686177 OilFanEpprFdbkCur "OilfanEPPRfeedbackcurrent";
CM_ BO_ 2583686433 "VBO Virtual Qa Data  ";
CM_ SG_ 2583686433 Pmp2flowandCmdDev "Pump2flowandcommanddeviation";
CM_ SG_ 2583686433 Pmp1flowandCmdDev "Pump1flowandcommanddeviation";
CM_ SG_ 2583686433 Pmp2VirQa "Pump2virtualQa";
CM_ SG_ 2583686433 Pmp1VirQa "Pump1virtualQa";
CM_ BO_ 2382360307 "PG TR Attachment Dimension Message 2";
CM_ SG_ 2382360307 H "H";
CM_ SG_ 2382360307 G "G";
CM_ SG_ 2382360307 F "F";
CM_ SG_ 2382360307 E "E";
CM_ BO_ 2382360563 "PG TR Attachment Dimension Message 1";
CM_ SG_ 2382360563 D "D";
CM_ SG_ 2382360563 C "C";
CM_ SG_ 2382360563 B "B";
CM_ SG_ 2382360563 A "A";
CM_ BO_ 2382360819 "PG Tool Attachment Information Message 1";
CM_ SG_ 2382360819 ToolAttSerialNo "Tool Attachment Serial Number";
CM_ SG_ 2382360819 ToolAttTypeId "Tool Attachment Type ID";
CM_ SG_ 2382360819 ToolAttSaeId "Tool Attachment SAE ID ";
CM_ BO_ 2382361075 "PG TR Attachment Information Message 1";
CM_ SG_ 2382361075 TRAttSerialNo "TR Attachment Serial Number";
CM_ SG_ 2382361075 TRAttTypeId "TR Attachment Type ID";
CM_ SG_ 2382361075 TRAttSaeId "TR Attachment SAE ID";
CM_ BO_ 2382361331 "PG TR Sensor Information Message 1";
CM_ SG_ 2382361331 J1939Bitrate "J1939 Bitrate";
CM_ SG_ 2382361331 TransRepetitionRate "Transmission Repetition Rate";
CM_ SG_ 2382361331 AbsEncTiltSsSt "Absolute Encoder Tilt Sensor Status";
CM_ SG_ 2382361331 ImuTiltSsSt "IMU Tilt Sensor Status";
CM_ SG_ 2382361331 RttSsSt "Rotation Sensor Status";
CM_ SG_ 2382361331 TiltSsDataDlyMd "Tilt Sensor Data Delay Mode";
CM_ SG_ 2382361331 SsFaultCode "Sensor Fault Code";
CM_ BO_ 2382361587 "PG TR Rotation Sensor Data Message 1";
CM_ SG_ 2382361587 RttSsdataDly "Rotation sensor data delay";
CM_ SG_ 2382361587 RttAngaroundZAxis "Rotation angle around Z-Axis";
CM_ BO_ 2382361843 "PG TR Tilt Sensor Data Message 1";
CM_ SG_ 2382361843 TiltSsdataDly "Tilt sensor data delay*";
CM_ SG_ 2382361843 TiltAbsEncAng "Tilt absolute encoder angle";
CM_ SG_ 2382361843 TiltImuAngaroundYAxis "Tilt IMU angle around Y-Axis";
CM_ SG_ 2382361843 TiltImuAngaroundXAxis "Tilt IMU angle around X-Axis";
CM_ BO_ 2382362867 "PG Attachment Function Information Message 1";
CM_ SG_ 2382362867 TRToolLckSt "TR Tool Lock Status";
CM_ SG_ 2382362867 OnOffFunc8St "On/Off Function 8 Status";
CM_ SG_ 2382362867 OnOffFunc7St "On/Off Function 7 Status";
CM_ SG_ 2382362867 OnOffFunc6St "On/Off Function 6 Status";
CM_ SG_ 2382362867 OnOffFunc5St "On/Off Function 5 Status";
CM_ SG_ 2382362867 OnOffFunc4St "On/Off Function 4 Status";
CM_ SG_ 2382362867 OnOffFunc3St "On/Off Function 3 Status";
CM_ SG_ 2382362867 OnOffFunc2St "On/Off Function 2 Status";
CM_ SG_ 2382362867 OnOffFunc1St "On/Off Function 1 Status";
CM_ SG_ 2382362867 PropFunc6St "Proportional Function 6 Status";
CM_ SG_ 2382362867 PropFunc5St "Proportional Function 5 Status";
CM_ SG_ 2382362867 PropFunc4St "Proportional Function 4 Status";
CM_ SG_ 2382362867 PropFunc3St "Proportional Function 3 Status";
CM_ SG_ 2382362867 PropFunc2St "Proportional Function 2 Status";
CM_ SG_ 2382362867 PropFunc1St "Proportional Function 1 Status";
CM_ BO_ 2382363123 "PG Attachment Lock Control Message 1";
CM_ SG_ 2382363123 AttLckVvVal "Attachment Lock Valve Value";
CM_ SG_ 2382363123 AttLckVvPosiSt "Attachment Lock Valve Positive Status";
CM_ SG_ 2382363123 AttLckVvNegaSt "Attachment Lock Valve Negative Status";
CM_ BO_ 2382363379 "PG Auxiliary Hydraulic Control Message 1";
CM_ SG_ 2382363379 AuxHyh3Val "Auxiliary Hydraulics 3 Value";
CM_ SG_ 2382363379 AuxHyh3PosiSt "Auxiliary Hydraulics 3 Positive Status";
CM_ SG_ 2382363379 AuxHyh3NegaSt "Auxiliary Hydraulics 3 Negative Status";
CM_ SG_ 2382363379 AuxHyh3NtrlSt "Auxiliary Hydraulics 3 Neutral Status";
CM_ SG_ 2382363379 AuxHyh2Val "Auxiliary Hydraulics 2 Value";
CM_ SG_ 2382363379 AuxHyh2PosiSt "Auxiliary Hydraulics 2 Positive Status";
CM_ SG_ 2382363379 AuxHyh2NegaSt "Auxiliary Hydraulics 2 Negative Status";
CM_ SG_ 2382363379 AuxHyh2NtrlSt "Auxiliary Hydraulics 2 Neutral Status";
CM_ SG_ 2382363379 AuxHyh1Val "Auxiliary Hydraulics 1 Value";
CM_ SG_ 2382363379 AuxHyh1PosiSt "Auxiliary Hydraulics 1 Positive Status";
CM_ SG_ 2382363379 AuxHyh1NegaSt "Auxiliary Hydraulics 1 Negative Status";
CM_ SG_ 2382363379 AuxHyh1NtrlSt "Auxiliary Hydraulics 1 Neutral Status";
CM_ BO_ 2382363681 "PG Excavator Information Message 1";
CM_ SG_ 2382363681 AuxHyh3Val "Auxiliary Hydraulics 3 Value";
CM_ SG_ 2382363681 AuxHyh3PosiSt "Auxiliary Hydraulics 3 Positive Status";
CM_ SG_ 2382363681 AuxHyh3NegaSt "Auxiliary Hydraulics 3 Negative Status";
CM_ SG_ 2382363681 AuxHyh3NtrlSt "Auxiliary Hydraulics 3 Neutral Status";
CM_ SG_ 2382363681 AuxHyh2Val "Auxiliary Hydraulics 2 Value";
CM_ SG_ 2382363681 AuxHyh2PosiSt "Auxiliary Hydraulics 2 Positive Status";
CM_ SG_ 2382363681 AuxHyh2NegaSt "Auxiliary Hydraulics 2 Negative Status";
CM_ SG_ 2382363681 AuxHyh2NtrlSt "Auxiliary Hydraulics 2 Neutral Status";
CM_ SG_ 2382363681 AuxHyh1Val "Auxiliary Hydraulics 1 Value";
CM_ SG_ 2382363681 AuxHyh1PosiSt "Auxiliary Hydraulics 1 Positive Status";
CM_ SG_ 2382363681 AuxHyh1NegaSt "Auxiliary Hydraulics 1 Negative Status";
CM_ SG_ 2382363681 AuxHyh1NtrlSt "Auxiliary Hydraulics 1 Neutral Status";
CM_ BO_ 2382364193 "PG Attachment Control Message 2";
CM_ SG_ 2382364193 OnOffFunc5St "On/Off Function 5 Status";
CM_ SG_ 2382364193 OnOffFunc6St "On/Off Function 6 Status";
CM_ SG_ 2382364193 OnOffFunc7St "On/Off Function 7 Status";
CM_ SG_ 2382364193 OnOffFunc8St "On/Off Function 8 Status";
CM_ SG_ 2382364193 PropFunc6Val "Proportional Function 6 Value";
CM_ SG_ 2382364193 PropFunc6PosiSt "Proportional Function 6 Positive Status";
CM_ SG_ 2382364193 PropFunc6NegaSt "Proportional Function 6 Negative Status";
CM_ SG_ 2382364193 PropFunc6NtrlSt "Proportional Function 6 Neutral Status";
CM_ SG_ 2382364193 PropFunc5Val "Proportional Function 5 Value";
CM_ SG_ 2382364193 PropFunc5PosiSt "Proportional Function 5 Positive Status";
CM_ SG_ 2382364193 PropFunc5NegaSt "Proportional Function 5 Negative Status";
CM_ SG_ 2382364193 PropFunc5NtrlSt "Proportional Function 5 Neutral Status";
CM_ SG_ 2382364193 PropFunc4Val "Proportional Function 4 Value";
CM_ SG_ 2382364193 PropFunc4PosiSt "Proportional Function 4 Positive Status";
CM_ SG_ 2382364193 PropFunc4NegaSt "Proportional Function 4 Negative Status";
CM_ SG_ 2382364193 PropFunc4NtrlSt "Proportional Function 4 Neutral Status";
CM_ BO_ 2382364449 "PG Attachment Control Message 1";
CM_ SG_ 2382364449 OnOffFunc1St "On/Off Function 1 Status";
CM_ SG_ 2382364449 OnOffFunc2St "On/Off Function 2 Status";
CM_ SG_ 2382364449 OnOffFunc3St "On/Off Function 3 Status";
CM_ SG_ 2382364449 OnOffFunc4St "On/Off Function 4 Status";
CM_ SG_ 2382364449 PropFunc3Value "Proportional Function 3 Value";
CM_ SG_ 2382364449 PropFunc3PosiSt "Proportional Function 3 Positive Status";
CM_ SG_ 2382364449 PropFunc3NegaSt "Proportional Function 3 Negative Status";
CM_ SG_ 2382364449 PropFunc3NtrlSt "Proportional Function 3 Neutral Status";
CM_ SG_ 2382364449 PropFunc2Value "Proportional Function 2 Value";
CM_ SG_ 2382364449 PropFunc2PosiSt "Proportional Function 2 Positive Status";
CM_ SG_ 2382364449 PropFunc2NegaSt "Proportional Function 2 Negative Status";
CM_ SG_ 2382364449 PropFunc2NtrlSt "Proportional Function 2 Neutral Status";
CM_ SG_ 2382364449 PropFunc1Value "Proportional Function 1 Value";
CM_ SG_ 2382364449 PropFunc1PosiSt "Proportional Function 1 Positive Status";
CM_ SG_ 2382364449 PropFunc1NegaSt "Proportional Function 1 Negative Status";
CM_ SG_ 2382364449 PropFunc1NtrlSt "Proportional Function 1 Neutral Status";
CM_ BO_ 2566842442 "Vehicle Direction/Speed";
CM_ SG_ 2566842442 Z "Altitude";
CM_ SG_ 2566842442 Spd "Navigation-BasedVehicleSpeed";
CM_ BO_ 2566845258 "Vehicle Position 1 (1s)";
CM_ SG_ 2566845258 Y "Longitude";
CM_ SG_ 2566845258 X "Latitude";
CM_ BO_ 2583642954 "Digital Keyless Login";
CM_ SG_ 2583642954 Dkey "Digital Key Selected";
CM_ SG_ 2583642954 SelType "Select Type";
CM_ BO_ 2583643466 "Digital Key Total List Registered";
CM_ SG_ 2583643466 DkeyListInfo "Digital Key List Information";
CM_ BO_ 2583642186 "Machine Provisioning Status";
CM_ SG_ 2583642186 TokenRevCnt "Token Revision Count";
CM_ SG_ 2583642186 MpSt "Machine Provisioning Status";
CM_ BO_ 2583642442 "Machine Provisioning Information";
CM_ SG_ 2583642442 TguId "Terminal Serial Number";
CM_ SG_ 2583642442 Name "Machine Sales Name";
CM_ SG_ 2583642442 Mcode "Machine Model Code";
CM_ SG_ 2583642442 Vin "Vehicle Identification Number";
CM_ SG_ 2583642442 Oem "OEM Information";
CM_ SG_ 2583642442 Mch "Machine Asset ID";
CM_ BO_ 2583662698 "PHM Warning Group";
CM_ SG_ 2583662698 WarnPopPhmSwgMot "Warning Pop-up; PHM - Swing Motor";
CM_ SG_ 2583662698 WarnPopPhm2ndSwgRedGr "Warning Pop-up; PHM - 2nd Swing Reduction Gear";
CM_ SG_ 2583662698 WarnPopPhm1stSwgRedGr "Warning Pop-up; PHM - 1st Swing Reduction Gear";
CM_ SG_ 2583662698 WarnPopMainPmp "Warning Pop-up; PHM - Main Pump";
CM_ SG_ 2583662698 WarnPopEgOilQual "Warning Pop-up; PHM - Engine Oil Quality ";
CM_ SG_ 2583662698 WarnPopHyhOilQual "Warning Pop-up; PHM - Hydraulic Oil Quality ";
CM_ BO_ 2583666538 "Threshold of Hydraulic Oil";
CM_ SG_ 2583666538 LwThKnmtVcstyofHyhOil "Lower Threshold Kinematic Viscosity of Hydraulic Oil";
CM_ SG_ 2583666538 UpThKnmtVcstyofHyhOil "Upper Threshold Kinematic Viscosity of Hydraulic Oil";
CM_ SG_ 2583666538 LwThDielecCstofHyhOil "Lower Threshold Dieletric Constant of Hydraulic Oil";
CM_ SG_ 2583666538 UpThDielecCstofHyhOil "Upper Threshold Dieletric Constant of Hydraulic Oil";
CM_ BO_ 2583666794 "Threshold of Engine Oil";
CM_ SG_ 2583666794 LwThKnmtVcstyofEgOil "Lower Threshold Kinematic Viscosity of Engine Oil";
CM_ SG_ 2583666794 UpThKnmtVcstyofEgOil "Upper Threshold Kinematic Viscosity of Engine Oil";
CM_ SG_ 2583666794 LwThDielecCstofEgOil "Lower Threshold Dieletric Constant of Engine Oil";
CM_ SG_ 2583666794 UpThDielecCstofEgOil "Upper Threshold Dieletric Constant of Engine Oil";
CM_ BO_ 2583667050 "Kinematic Viscosity of Oil";
CM_ SG_ 2583667050 KnmtVcstyofEgOil "Kinematic Viscosity of Engine Oil";
CM_ SG_ 2583667050 KnmtVcstyofHyhOil "Kinematic Viscosity of Hydraulic Oil";
CM_ BO_ 2583662881 "EPOS CAN Data for PHM1";
CM_ SG_ 2583662881 AccPdlVlt "Accel Pedal Voltage (Wheel)";
CM_ SG_ 2583662881 RJoyThmbVlt "[Excavator] Right Joystick Thumb Voltage (Flow Control Lever RH)";
CM_ SG_ 2583662881 LJoyThmbVlt "[Excavator] Left Joystick Thumb Voltage (Flow Control Lever LH)";
CM_ BO_ 2583663137 "EPOS CAN Data for PHM2";
CM_ SG_ 2583663137 RrPmpPrs " [Excavator] Rear Pump Pressure ";
CM_ SG_ 2583663137 FrPmpPrs " [Excavator] Front Pump Pressure";
CM_ SG_ 2583663137 AltVlt "Alternator Voltage";
CM_ SG_ 2583663137 BatVlt "Battery Voltage [Default]";
CM_ BO_ 2583663393 "EPOS CAN Data for PHM3";
CM_ SG_ 2583663393 StickStrType "Stick Steering Type";
CM_ SG_ 2583663393 StickStr "Stick Steering";
CM_ SG_ 2583663393 JoyPtnChange "Joystick Pattern Change";
CM_ SG_ 2583663393 Pmp2ActFlow "Pump2 actual flow";
CM_ SG_ 2583663393 Pmp1ActFlow "Pump1 actual flow";
CM_ BO_ 2633656127 "Oil Quality Message 2";
CM_ SG_ 2633656127 Oilresistivity "Oil resistivity";
CM_ BO_ 2633656238 "Oil Quality Message 2";
CM_ SG_ 2633656238 Oilresistivity "Oil resistivity";
CM_ BO_ 2566894666 "Certification Number of Remote Crank";
CM_ SG_ 2566894666 CertKey7 "Certification Key 7";
CM_ SG_ 2566894666 CertKey8 "Certification Key 8";
CM_ SG_ 2566894666 CertKey5 "Certification Key 5";
CM_ SG_ 2566894666 CertKey6 "Certification Key 6";
CM_ SG_ 2566894666 CertKey3 "Certification Key 3";
CM_ SG_ 2566894666 CertKey4 "Certification Key 4";
CM_ SG_ 2566894666 CertKey1 "Certification Key 1";
CM_ SG_ 2566894666 CertKey2 "Certification Key 2";
CM_ BO_ 2566868001 "ELEC Gauge Data Group";
CM_ SG_ 2566868001 SocBatLevel "Gauge Data; SOC Battery Level";
CM_ SG_ 2566868001 SwgIvtTmp "Gauge Data; Swing Inverter Temperature";
CM_ SG_ 2566868001 TrvlIvtTmp "Gauge Data; Travel Inverter Temperature";
CM_ SG_ 2566868001 PmpIvtTmp "Gauge Data; Pump Inverter Temperature";
CM_ SG_ 2566868001 SwgMotTmp "Gauge Data; Swing Motor Temperature";
CM_ SG_ 2566868001 TrvlMotTmp "Gauge Data; Travel Motor Temperature";
CM_ SG_ 2566868001 PmpMotTmp "Gauge Data; Pump Motor Temperature";
CM_ SG_ 2566868001 SocBatTmp "Gauge Data; SOC Battery Temperature";
CM_ BO_ 2634015777 "TCU Multi Program Request";
CM_ SG_ 2634015777 ReqCd "Request Code";
CM_ SG_ 2634015777 MaxGrLmt "Max Gear Limit";
CM_ SG_ 2634015777 EmsCtrl "Emission Control";
CM_ SG_ 2634015777 MchClass "Machine Classification";
CM_ SG_ 2634015777 MchGenr "Machine Generation";
CM_ BO_ 2634016259 "TCU Multi Program Result";
CM_ SG_ 2634016259 ResultCd "Result Code";
CM_ SG_ 2634016259 AxleOpt "Axle Option";
CM_ SG_ 2634016259 MaxGrLmt "Max Gear Limit";
CM_ SG_ 2634016259 EmsCtrl "Emission Control";
CM_ SG_ 2634016259 MchClass "Machine Classification";
CM_ SG_ 2634016259 MchGenr "Machine Generation";
CM_ BO_ 2566912033 "MC Weighing Handshake Group 5";
CM_ SG_ 2566912033 ImuAxisSetTiltBck05 "IMU Axis Set; Tilt Bucket 05";
CM_ SG_ 2566912033 ImuAxisSetTiltBck04 "IMU Axis Set; Tilt Bucket 04";
CM_ SG_ 2566912033 ImuAxisSetTiltBck03 "IMU Axis Set; Tilt Bucket 03";
CM_ SG_ 2566912033 ImuAxisSetTiltBck02 "IMU Axis Set; Tilt Bucket 02";
CM_ SG_ 2566912033 ImuAxisSetTiltBck01 "IMU Axis Set; Tilt Bucket 01";
CM_ SG_ 2566912033 TiltBck05DmsnNq3 "Tilt Bucket 05 Dimension; NQ3";
CM_ SG_ 2566912033 TiltBck05DmsnNq2 "Tilt Bucket 05 Dimension; NQ2";
CM_ SG_ 2566912033 TiltBck05DmsnNq1 "Tilt Bucket 05 Dimension; NQ1";
CM_ SG_ 2566912033 TiltBck05DmsnWd "Tilt Bucket 05 Dimension; Width";
CM_ SG_ 2566912033 TiltBck05DmsnUq3 "Tilt Bucket 05 Dimension; UQ3";
CM_ SG_ 2566912033 TiltBck05DmsnUq2 "Tilt Bucket 05 Dimension; UQ2";
CM_ SG_ 2566912033 TiltBck05DmsnUq1 "Tilt Bucket 05 Dimension; UQ1";
CM_ SG_ 2566912033 TiltBck05DmsnUm "Tilt Bucket 05 Dimension; UM";
CM_ SG_ 2566912033 TiltBck05DmsnDt "Tilt Bucket 05 Dimension; DT";
CM_ SG_ 2566912033 TiltBck05DmsnDg "Tilt Bucket 05 Dimension; DG";
CM_ SG_ 2566912033 TiltBck05DmsnGdt "Tilt Bucket 05 Dimension; GDT";
CM_ SG_ 2566912033 ImuSsOffsetTiltBck05Roll "IMU Sensor Offset; Tilt Bucket 05 Roll";
CM_ SG_ 2566912033 ImuSsOffsetTiltBck05Pch "IMU Sensor Offset; Tilt Bucket 05 Pitch";
CM_ SG_ 2566912033 TiltBck05DmsnTuN "Tilt Bucket 05 Dimension;  TUN";
CM_ SG_ 2566912033 TiltBck05DmsnTthMn "Tilt Bucket 05 Dimension; Tooth(MN)";
CM_ SG_ 2566912033 TiltBck05DmsnUn "Tilt Bucket 05 Dimension; UN";
CM_ SG_ 2566912033 TiltBck05DmsnTn "Tilt Bucket 05 Dimension; TN";
CM_ SG_ 2566912033 TiltBck05DmsnTu "Tilt Bucket 05 Dimension; TU";
CM_ SG_ 2566912033 TiltBck04DmsnNq3 "Tilt Bucket 04 Dimension; NQ3";
CM_ SG_ 2566912033 TiltBck04DmsnNq2 "Tilt Bucket 04 Dimension; NQ2";
CM_ SG_ 2566912033 TiltBck04DmsnNq1 "Tilt Bucket 04 Dimension; NQ1";
CM_ SG_ 2566912033 TiltBck04DmsnWd "Tilt Bucket 04 Dimension; Width";
CM_ SG_ 2566912033 TiltBck04DmsnUq3 "Tilt Bucket 04 Dimension; UQ3";
CM_ SG_ 2566912033 TiltBck04DmsnUq2 "Tilt Bucket 04 Dimension; UQ2";
CM_ SG_ 2566912033 TiltBck04DmsnUq1 "Tilt Bucket 04 Dimension; UQ1";
CM_ SG_ 2566912033 TiltBck04DmsnUm "Tilt Bucket 04 Dimension; UM";
CM_ SG_ 2566912033 TiltBck04DmsnDt "Tilt Bucket 04 Dimension; DT";
CM_ SG_ 2566912033 TiltBck04DmsnDg "Tilt Bucket 04 Dimension; DG";
CM_ SG_ 2566912033 TiltBck04DmsnGdt "Tilt Bucket 04 Dimension; GDT";
CM_ SG_ 2566912033 ImuSsOffsetTiltBck04Roll "IMU Sensor Offset; Tilt Bucket 04 Roll";
CM_ SG_ 2566912033 ImuSsOffsetTiltBck04Pch "IMU Sensor Offset; Tilt Bucket 04 Pitch";
CM_ SG_ 2566912033 TiltBck04DmsnTuN "Tilt Bucket 04 Dimension;  TUN";
CM_ SG_ 2566912033 TiltBck04DmsnTthMn "Tilt Bucket 04 Dimension; Tooth(MN)";
CM_ SG_ 2566912033 TiltBck04DmsnUn "Tilt Bucket 04 Dimension; UN";
CM_ SG_ 2566912033 TiltBck04DmsnTn "Tilt Bucket 04 Dimension; TN";
CM_ SG_ 2566912033 TiltBck04DmsnTu "Tilt Bucket 04 Dimension; TU";
CM_ SG_ 2566912033 TiltBck03DmsnNq3 "Tilt Bucket 03 Dimension; NQ3";
CM_ SG_ 2566912033 TiltBck03DmsnNq2 "Tilt Bucket 03 Dimension; NQ2";
CM_ SG_ 2566912033 TiltBck03DmsnNq1 "Tilt Bucket 03 Dimension; NQ1";
CM_ SG_ 2566912033 TiltBck03DmsnWd "Tilt Bucket 03 Dimension; Width";
CM_ SG_ 2566912033 TiltBck03DmsnUq3 "Tilt Bucket 03 Dimension; UQ3";
CM_ SG_ 2566912033 TiltBck03DmsnUq2 "Tilt Bucket 03 Dimension; UQ2";
CM_ SG_ 2566912033 TiltBck03DmsnUq1 "Tilt Bucket 03 Dimension; UQ1";
CM_ SG_ 2566912033 TiltBck03DmsnUm "Tilt Bucket 03 Dimension; UM";
CM_ SG_ 2566912033 TiltBck03DmsnDt "Tilt Bucket 03 Dimension; DT";
CM_ SG_ 2566912033 TiltBck03DmsnDg "Tilt Bucket 03 Dimension; DG";
CM_ SG_ 2566912033 TiltBck03DmsnGdt "Tilt Bucket 03 Dimension; GDT";
CM_ SG_ 2566912033 ImuSsOffsetTiltBck03Roll "IMU Sensor Offset; Tilt Bucket 03 Roll";
CM_ SG_ 2566912033 ImuSsOffsetTiltBck03Pch "IMU Sensor Offset; Tilt Bucket 03 Pitch";
CM_ SG_ 2566912033 TiltBck03DmsnTuN "Tilt Bucket 03 Dimension;  TUN";
CM_ SG_ 2566912033 TiltBck03DmsnTthMn "Tilt Bucket 03 Dimension; Tooth(MN)";
CM_ SG_ 2566912033 TiltBck03DmsnUn "Tilt Bucket 03 Dimension; UN";
CM_ SG_ 2566912033 TiltBck03DmsnTn "Tilt Bucket 03 Dimension; TN";
CM_ SG_ 2566912033 TiltBck03DmsnTu "Tilt Bucket 03 Dimension; TU";
CM_ SG_ 2566912033 TiltBck02DmsnNq3 "Tilt Bucket 02 Dimension; NQ3";
CM_ SG_ 2566912033 TiltBck02DmsnNq2 "Tilt Bucket 02 Dimension; NQ2";
CM_ SG_ 2566912033 TiltBck02DmsnNq1 "Tilt Bucket 02 Dimension; NQ1";
CM_ SG_ 2566912033 TiltBck02DmsnWd "Tilt Bucket 02 Dimension; Width";
CM_ SG_ 2566912033 TiltBck02DmsnUq3 "Tilt Bucket 02 Dimension; UQ3";
CM_ SG_ 2566912033 TiltBck02DmsnUq2 "Tilt Bucket 02 Dimension; UQ2";
CM_ SG_ 2566912033 TiltBck02DmsnUq1 "Tilt Bucket 02 Dimension; UQ1";
CM_ SG_ 2566912033 TiltBck02DmsnUm "Tilt Bucket 02 Dimension; UM";
CM_ SG_ 2566912033 TiltBck02DmsnDt "Tilt Bucket 02 Dimension; DT";
CM_ SG_ 2566912033 TiltBck02DmsnDg "Tilt Bucket 02 Dimension; DG";
CM_ SG_ 2566912033 TiltBck02DmsnGdt "Tilt Bucket 02 Dimension; GDT";
CM_ SG_ 2566912033 ImuSsOffsetTiltBck02Roll "IMU Sensor Offset; Tilt Bucket 02 Roll";
CM_ SG_ 2566912033 ImuSsOffsetTiltBck02Pch "IMU Sensor Offset; Tilt Bucket 02 Pitch";
CM_ SG_ 2566912033 TiltBck02DmsnTuN "Tilt Bucket 02 Dimension;  TUN";
CM_ SG_ 2566912033 TiltBck02DmsnTthMn "Tilt Bucket 02 Dimension; Tooth(MN)";
CM_ SG_ 2566912033 TiltBck02DmsnUn "Tilt Bucket 02 Dimension; UN";
CM_ SG_ 2566912033 TiltBck02DmsnTn "Tilt Bucket 02 Dimension; TN";
CM_ SG_ 2566912033 TiltBck02DmsnTu "Tilt Bucket 02 Dimension; TU";
CM_ SG_ 2566912033 TiltBck01DmsnNq3 "Tilt Bucket 01 Dimension; NQ3";
CM_ SG_ 2566912033 TiltBck01DmsnNq2 "Tilt Bucket 01 Dimension; NQ2";
CM_ SG_ 2566912033 TiltBck01DmsnNq1 "Tilt Bucket 01 Dimension; NQ1";
CM_ SG_ 2566912033 TiltBck01DmsnWd "Tilt Bucket 01 Dimension; Width";
CM_ SG_ 2566912033 TiltBck01DmsnUq3 "Tilt Bucket 01 Dimension; UQ3";
CM_ SG_ 2566912033 TiltBck01DmsnUq2 "Tilt Bucket 01 Dimension; UQ2";
CM_ SG_ 2566912033 TiltBck01DmsnUq1 "Tilt Bucket 01 Dimension; UQ1";
CM_ SG_ 2566912033 TiltBck01DmsnUm "Tilt Bucket 01 Dimension; UM";
CM_ SG_ 2566912033 TiltBck01DmsnDt "Tilt Bucket 01 Dimension; DT";
CM_ SG_ 2566912033 TiltBck01DmsnDg "Tilt Bucket 01 Dimension; DG";
CM_ SG_ 2566912033 TiltBck01DmsnGdt "Tilt Bucket 01 Dimension; GDT";
CM_ SG_ 2566912033 ImuSsOffsetTiltBck01Roll "IMU Sensor Offset; Tilt Bucket 01 Roll";
CM_ SG_ 2566912033 ImuSsOffsetTiltBck01Pch "IMU Sensor Offset; Tilt Bucket 01 Pitch";
CM_ SG_ 2566912033 TiltBck01DmsnTun "Tilt Bucket 01 Dimension;  TUN";
CM_ SG_ 2566912033 TiltBck01DmsnTthMn "Tilt Bucket 01 Dimension; Tooth(MN)";
CM_ SG_ 2566912033 TiltBck01DmsnUn "Tilt Bucket 01 Dimension; UN";
CM_ SG_ 2566912033 TiltBck01DmsnTn "Tilt Bucket 01 Dimension; TN";
CM_ SG_ 2566912033 TiltBck01DmsnTu "Tilt Bucket 01 Dimension; TU";
BA_DEF_ BO_  "Channel" STRING ;
BA_DEF_ BO_  "VssMsg" STRING ;
BA_DEF_ SG_  "VssSig" STRING ;
BA_DEF_ BO_  "GenMsgCycleTime" INT 0 65535;
BA_DEF_ SG_  "SystemSignalLongSymbol" STRING ;
BA_DEF_DEF_  "Channel" "";
BA_DEF_DEF_  "VssMsg" "";
BA_DEF_DEF_  "VssSig" "";
BA_DEF_DEF_  "GenMsgCycleTime" 0;
BA_DEF_DEF_  "SystemSignalLongSymbol" "";
BA_ "VssMsg" BO_ 2566907937 "Mch.MCU.MCI";
BA_ "Channel" BO_ 2566907937 "can1";
BA_ "GenMsgCycleTime" BO_ 2566908449 100;
BA_ "VssMsg" BO_ 2566908449 "Mch.MCU.MWIG";
BA_ "Channel" BO_ 2566908449 "can1";
BA_ "GenMsgCycleTime" BO_ 2566908705 100;
BA_ "VssMsg" BO_ 2566908705 "Mch.MCU.TWG";
BA_ "Channel" BO_ 2566908705 "can1";
BA_ "GenMsgCycleTime" BO_ 2566908961 100;
BA_ "VssMsg" BO_ 2566908961 "Mch.MCU.WCPR";
BA_ "Channel" BO_ 2566908961 "can1";
BA_ "GenMsgCycleTime" BO_ 2566909217 100;
BA_ "VssMsg" BO_ 2566909217 "Mch.MCU.WCCV";
BA_ "Channel" BO_ 2566909217 "can1";
BA_ "GenMsgCycleTime" BO_ 2566909473 100;
BA_ "VssMsg" BO_ 2566909473 "Mch.MCU.WCJA";
BA_ "Channel" BO_ 2566909473 "can1";
BA_ "GenMsgCycleTime" BO_ 2566909729 100;
BA_ "VssMsg" BO_ 2566909729 "Mch.MCU.LADG";
BA_ "Channel" BO_ 2566909729 "can1";
BA_ "VssMsg" BO_ 2634018819 "Mch.TCU.TCUID";
BA_ "Channel" BO_ 2634018819 "can1";
BA_ "GenMsgCycleTime" BO_ 2566910241 100;
BA_ "VssMsg" BO_ 2566910241 "Mch.MCU.ASRG";
BA_ "Channel" BO_ 2566910241 "can1";
BA_ "VssMsg" BO_ 2566910534 "Mch.EVC.ETCCMVCU";
BA_ "Channel" BO_ 2566910534 "can1";
BA_ "VssMsg" BO_ 2566912289 "Mch.MCU.MWHG4";
BA_ "Channel" BO_ 2566912289 "can1";
BA_ "VssMsg" BO_ 2566912545 "Mch.MCU.MWHG1";
BA_ "Channel" BO_ 2566912545 "can1";
BA_ "VssMsg" BO_ 2566912801 "Mch.MCU.MWHG2";
BA_ "Channel" BO_ 2566912801 "can1";
BA_ "VssMsg" BO_ 2566913057 "Mch.MCU.MWHG3";
BA_ "Channel" BO_ 2566913057 "can1";
BA_ "VssMsg" BO_ 2566913313 "Mch.MCU.MWTSV";
BA_ "Channel" BO_ 2566913313 "can1";
BA_ "VssMsg" BO_ 2566913569 "Mch.MCU.MTSI";
BA_ "Channel" BO_ 2566913569 "can1";
BA_ "VssMsg" BO_ 2566913825 "Mch.MCU.MAWI";
BA_ "Channel" BO_ 2566913825 "can1";
BA_ "GenMsgCycleTime" BO_ 2583646241 10;
BA_ "VssMsg" BO_ 2583646241 "Mch.MCU.FPSSC";
BA_ "Channel" BO_ 2583646241 "can1";
BA_ "GenMsgCycleTime" BO_ 2583646497 10;
BA_ "VssMsg" BO_ 2583646497 "Mch.MCU.RPSSC";
BA_ "Channel" BO_ 2583646497 "can1";
BA_ "GenMsgCycleTime" BO_ 2583646753 10;
BA_ "VssMsg" BO_ 2583646753 "Mch.MCU.OSSC";
BA_ "Channel" BO_ 2583646753 "can1";
BA_ "GenMsgCycleTime" BO_ 2583651424 10;
BA_ "VssMsg" BO_ 2583651424 "Mch.MCU2.FPDSSC";
BA_ "Channel" BO_ 2583651424 "can1";
BA_ "GenMsgCycleTime" BO_ 2583651680 10;
BA_ "VssMsg" BO_ 2583651680 "Mch.MCU2.RPDSSC";
BA_ "Channel" BO_ 2583651680 "can1";
BA_ "GenMsgCycleTime" BO_ 2583651936 10;
BA_ "VssMsg" BO_ 2583651936 "Mch.MCU2.ODSSC";
BA_ "Channel" BO_ 2583651936 "can1";
BA_ "GenMsgCycleTime" BO_ 2583654752 20;
BA_ "VssMsg" BO_ 2583654752 "Mch.MCU2.BBEFC";
BA_ "Channel" BO_ 2583654752 "can3";
BA_ "GenMsgCycleTime" BO_ 2583655008 20;
BA_ "VssMsg" BO_ 2583655008 "Mch.MCU2.ASEFC";
BA_ "Channel" BO_ 2583655008 "can3";
BA_ "GenMsgCycleTime" BO_ 2583655264 20;
BA_ "VssMsg" BO_ 2583655264 "Mch.MCU2.CEFC";
BA_ "Channel" BO_ 2583655264 "can3";
BA_ "GenMsgCycleTime" BO_ 2583655520 20;
BA_ "VssMsg" BO_ 2583655520 "Mch.MCU2.OEFC";
BA_ "Channel" BO_ 2583655520 "can3";
BA_ "GenMsgCycleTime" BO_ 2583655776 20;
BA_ "VssMsg" BO_ 2583655776 "Mch.MCU2.TEFC";
BA_ "Channel" BO_ 2583655776 "can1";
BA_ "GenMsgCycleTime" BO_ 2583656032 20;
BA_ "VssMsg" BO_ 2583656032 "Mch.MCU2.BHRP";
BA_ "Channel" BO_ 2583656032 "can3";
BA_ "GenMsgCycleTime" BO_ 2583656288 20;
BA_ "VssMsg" BO_ 2583656288 "Mch.MCU2.ABHRP";
BA_ "Channel" BO_ 2583656288 "can1";
BA_ "GenMsgCycleTime" BO_ 2583656544 20;
BA_ "VssMsg" BO_ 2583656544 "Mch.MCU2.CPSF";
BA_ "Channel" BO_ 2583656544 "can1";
BA_ "GenMsgCycleTime" BO_ 2583656800 20;
BA_ "VssMsg" BO_ 2583656800 "Mch.MCU2.VPP";
BA_ "Channel" BO_ 2583656800 "can3";
BA_ "GenMsgCycleTime" BO_ 2583658592 20;
BA_ "VssMsg" BO_ 2583658592 "Mch.MCU2.VPPSF";
BA_ "Channel" BO_ 2583658592 "can1";
BA_ "GenMsgCycleTime" BO_ 2583658848 20;
BA_ "VssMsg" BO_ 2583658848 "Mch.MCU2.PCS";
BA_ "Channel" BO_ 2583658848 "can1";
BA_ "GenMsgCycleTime" BO_ 2583667233 20;
BA_ "VssMsg" BO_ 2583667233 "Mch.MCU.CBCC";
BA_ "Channel" BO_ 2583667233 "can1";
BA_ "GenMsgCycleTime" BO_ 2583683873 100;
BA_ "VssMsg" BO_ 2583683873 "Mch.MCU.FJPP";
BA_ "Channel" BO_ 2583683873 "can3";
BA_ "GenMsgCycleTime" BO_ 2583684129 100;
BA_ "VssMsg" BO_ 2583684129 "Mch.MCU.TJPP";
BA_ "Channel" BO_ 2583684129 "can3";
BA_ "GenMsgCycleTime" BO_ 2583684385 20;
BA_ "VssMsg" BO_ 2583684385 "Mch.MCU.VFD";
BA_ "Channel" BO_ 2583684385 "can1";
BA_ "GenMsgCycleTime" BO_ 2583684641 20;
BA_ "VssMsg" BO_ 2583684641 "Mch.MCU.VP1D";
BA_ "Channel" BO_ 2583684641 "can1";
BA_ "GenMsgCycleTime" BO_ 2583684897 20;
BA_ "VssMsg" BO_ 2583684897 "Mch.MCU.VP2D";
BA_ "Channel" BO_ 2583684897 "can1";
BA_ "GenMsgCycleTime" BO_ 2583685153 20;
BA_ "VssMsg" BO_ 2583685153 "Mch.MCU.VTRQD";
BA_ "Channel" BO_ 2583685153 "can1";
BA_ "GenMsgCycleTime" BO_ 2583685409 100;
BA_ "VssMsg" BO_ 2583685409 "Mch.MCU.VSFC";
BA_ "Channel" BO_ 2583685409 "can3";
BA_ "GenMsgCycleTime" BO_ 2583685665 100;
BA_ "VssMsg" BO_ 2583685665 "Mch.MCU.VSPP";
BA_ "Channel" BO_ 2583685665 "can3";
BA_ "GenMsgCycleTime" BO_ 2583685921 20;
BA_ "VssMsg" BO_ 2583685921 "Mch.MCU.VPAD";
BA_ "Channel" BO_ 2583685921 "can1";
BA_ "GenMsgCycleTime" BO_ 2583686177 20;
BA_ "VssMsg" BO_ 2583686177 "Mch.MCU.VTD";
BA_ "Channel" BO_ 2583686177 "can1";
BA_ "GenMsgCycleTime" BO_ 2583686433 20;
BA_ "VssMsg" BO_ 2583686433 "Mch.MCU.VVQD";
BA_ "Channel" BO_ 2583686433 "can1";
BA_ "VssMsg" BO_ 2382360307 "Mch.AGW.TRADM2";
BA_ "Channel" BO_ 2382360307 "can1";
BA_ "VssMsg" BO_ 2382360563 "Mch.AGW.TRADM1";
BA_ "Channel" BO_ 2382360563 "can1";
BA_ "VssMsg" BO_ 2382360819 "Mch.AGW.TAIM1";
BA_ "Channel" BO_ 2382360819 "can1";
BA_ "VssMsg" BO_ 2382361075 "Mch.AGW.TRAIM1";
BA_ "Channel" BO_ 2382361075 "can1";
BA_ "GenMsgCycleTime" BO_ 2382361331 100;
BA_ "VssMsg" BO_ 2382361331 "Mch.AGW.TRSIM1";
BA_ "Channel" BO_ 2382361331 "can1";
BA_ "GenMsgCycleTime" BO_ 2382361587 10;
BA_ "VssMsg" BO_ 2382361587 "Mch.AGW.TRRSDM1";
BA_ "Channel" BO_ 2382361587 "can1";
BA_ "GenMsgCycleTime" BO_ 2382361843 10;
BA_ "VssMsg" BO_ 2382361843 "Mch.AGW.TRTSDM1";
BA_ "Channel" BO_ 2382361843 "can1";
BA_ "GenMsgCycleTime" BO_ 2382362867 50;
BA_ "VssMsg" BO_ 2382362867 "Mch.AGW.AFIM1";
BA_ "Channel" BO_ 2382362867 "can1";
BA_ "GenMsgCycleTime" BO_ 2382363123 50;
BA_ "VssMsg" BO_ 2382363123 "Mch.AGW.ALCM1";
BA_ "Channel" BO_ 2382363123 "can1";
BA_ "GenMsgCycleTime" BO_ 2382363379 50;
BA_ "VssMsg" BO_ 2382363379 "Mch.AGW.AHCM1";
BA_ "Channel" BO_ 2382363379 "can1";
BA_ "GenMsgCycleTime" BO_ 2382363681 50;
BA_ "VssMsg" BO_ 2382363681 "Mch.MCU.EIM1";
BA_ "Channel" BO_ 2382363681 "can1";
BA_ "GenMsgCycleTime" BO_ 2382364193 10;
BA_ "VssMsg" BO_ 2382364193 "Mch.MCU.ACM2";
BA_ "Channel" BO_ 2382364193 "can1";
BA_ "GenMsgCycleTime" BO_ 2382364449 10;
BA_ "VssMsg" BO_ 2382364449 "Mch.MCU.ACM1";
BA_ "Channel" BO_ 2382364449 "can1";
BA_ "GenMsgCycleTime" BO_ 2566842442 1000;
BA_ "VssMsg" BO_ 2566842442 "Mch.TGU.VDS";
BA_ "Channel" BO_ 2566842442 "can1";
BA_ "GenMsgCycleTime" BO_ 2566845258 1000;
BA_ "VssMsg" BO_ 2566845258 "Mch.TGU.VP1";
BA_ "Channel" BO_ 2566845258 "can1";
BA_ "VssMsg" BO_ 2583642954 "Mch.TGU.DKLLG";
BA_ "Channel" BO_ 2583642954 "can1";
BA_ "VssMsg" BO_ 2583643466 "Mch.TGU.DKTL";
BA_ "Channel" BO_ 2583643466 "can1";
BA_ "GenMsgCycleTime" BO_ 2583642186 10000;
BA_ "VssMsg" BO_ 2583642186 "Mch.TGU.MPS";
BA_ "Channel" BO_ 2583642186 "can2";
BA_ "VssMsg" BO_ 2583642442 "Mch.TGU.MPI";
BA_ "Channel" BO_ 2583642442 "can1";
BA_ "GenMsgCycleTime" BO_ 2583662698 200;
BA_ "VssMsg" BO_ 2583662698 "Mch.PHM.PHMWG";
BA_ "Channel" BO_ 2583662698 "can1";
BA_ "GenMsgCycleTime" BO_ 2583666538 3000;
BA_ "VssMsg" BO_ 2583666538 "Mch.PHM.THO";
BA_ "Channel" BO_ 2583666538 "can1";
BA_ "GenMsgCycleTime" BO_ 2583666794 3000;
BA_ "VssMsg" BO_ 2583666794 "Mch.PHM.TEO";
BA_ "Channel" BO_ 2583666794 "can1";
BA_ "GenMsgCycleTime" BO_ 2583667050 3000;
BA_ "VssMsg" BO_ 2583667050 "Mch.PHM.KVO";
BA_ "Channel" BO_ 2583667050 "can1";
BA_ "GenMsgCycleTime" BO_ 2583662881 200;
BA_ "VssMsg" BO_ 2583662881 "Mch.MCU.ECDP1";
BA_ "Channel" BO_ 2583662881 "can1";
BA_ "GenMsgCycleTime" BO_ 2583663137 100;
BA_ "VssMsg" BO_ 2583663137 "Mch.MCU.ECDP2";
BA_ "Channel" BO_ 2583663137 "can1";
BA_ "GenMsgCycleTime" BO_ 2583663393 100;
BA_ "VssMsg" BO_ 2583663393 "Mch.MCU.ECDP3";
BA_ "Channel" BO_ 2583663393 "can1";
BA_ "GenMsgCycleTime" BO_ 2633656127 30000;
BA_ "VssMsg" BO_ 2633656127 "Mch.HDOQS.OQM2";
BA_ "Channel" BO_ 2633656127 "can1";
BA_ "GenMsgCycleTime" BO_ 2633656238 30000;
BA_ "VssMsg" BO_ 2633656238 "Mch.EGOQS.OQM2";
BA_ "Channel" BO_ 2633656238 "can1";
BA_ "GenMsgCycleTime" BO_ 2566894666 100;
BA_ "VssMsg" BO_ 2566894666 "Mch.SMK.CNRC";
BA_ "Channel" BO_ 2566894666 "can1";
BA_ "GenMsgCycleTime" BO_ 2566868001 200;
BA_ "VssMsg" BO_ 2566868001 "Mch.MCU.EGDG";
BA_ "Channel" BO_ 2566868001 "can1";
BA_ "GenMsgCycleTime" BO_ 2634015777 100;
BA_ "VssMsg" BO_ 2634015777 "Mch.MCU.TCUMPRQ";
BA_ "Channel" BO_ 2634015777 "can1";
BA_ "VssMsg" BO_ 2634016259 "Mch.MCU.TCUMPRS";
BA_ "Channel" BO_ 2634016259 "can1";
BA_ "VssMsg" BO_ 2566912033 "Mch.MCU.MWHG5";
BA_ "Channel" BO_ 2566912033 "can1";
BA_ "VssSig" SG_ 2566907937 RhJoyBtnAux12AddSetConfig "Mch.MCU.MCI.RhJoyBtnAux12AddSetConfig";
BA_ "VssSig" SG_ 2566907937 HeavyAttConfig "Mch.MCU.MCI.HeavyAttConfig";
BA_ "VssSig" SG_ 2566907937 IdleSpdSetConfig "Mch.MCU.MCI.IdleSpdSetConfig";
BA_ "VssSig" SG_ 2566907937 SdkParallelLiftConfig "Mch.MCU.MCI.SdkParallelLiftConfig";
BA_ "VssSig" SG_ 2566907937 RsvforVdk10W "Mch.MCU.MCI.RsvforVdk10W";
BA_ "VssSig" SG_ 2566907937 BrkOprgTmLmConfigforVccC4 "Mch.MCU.MCI.BrkOprgTmLmConfigforVccC4";
BA_ "VssSig" SG_ 2566907937 ElectStrThmbwhlConfig "Mch.MCU.MCI.ElectStrThmbwhlConfig";
BA_ "VssSig" SG_ 2566907937 EmgStrConfig "Mch.MCU.MCI.EmgStrConfig";
BA_ "VssSig" SG_ 2566907937 LongLifeEgOilFiltConfig "Mch.MCU.MCI.LongLifeEgOilFiltConfig";
BA_ "VssSig" SG_ 2566907937 ElecStrJoyThwConf "Mch.MCU.MCI.ElecStrJoyThwConf";
BA_ "VssSig" SG_ 2566907937 Dl06EgFuelEffCalbConf "Mch.MCU.MCI.Dl06EgFuelEffCalbConf";
BA_ "VssSig" SG_ 2566907937 RttThwDirConf "Mch.MCU.MCI.RttThwDirConf";
BA_ "VssSig" SG_ 2566907937 TwThwDirConf "Mch.MCU.MCI.TwThwDirConf";
BA_ "VssSig" SG_ 2566907937 CanPdlIntChngConf "Mch.MCU.MCI.CanPdlIntChngConf";
BA_ "VssSig" SG_ 2566907937 TrvlSwgAlmIntChngConf "Mch.MCU.MCI.TrvlSwgAlmIntChngConf";
BA_ "VssSig" SG_ 2566907937 OprHrTmpIntChngConf "Mch.MCU.MCI.OprHrTmpIntChngConf";
BA_ "VssSig" SG_ 2566907937 QckCouplerIntChngConf "Mch.MCU.MCI.QckCouplerIntChngConf";
BA_ "VssSig" SG_ 2566907937 ThwSensConf "Mch.MCU.MCI.ThwSensConf";
BA_ "VssSig" SG_ 2566907937 MultiFuncJoyBtnConf "Mch.MCU.MCI.MultiFuncJoyBtnConf";
BA_ "VssSig" SG_ 2566908449 TiltRttArg "Mch.MCU.MWIG.TiltRttArg";
BA_ "VssSig" SG_ 2566908449 GnssSt "Mch.MCU.MWIG.GnssSt";
BA_ "VssSig" SG_ 2566908449 VhcStFineSwgTprDsb "Mch.MCU.MWIG.VhcStFineSwgTprDsb";
BA_ "VssSig" SG_ 2566908449 IndSymbolMcTprRlsSt "Mch.MCU.MWIG.IndSymbolMcTprRlsSt";
BA_ "VssSig" SG_ 2566908449 EfenceTgSetSideWallR "Mch.MCU.MWIG.EfenceTgSetSideWallR";
BA_ "VssSig" SG_ 2566908449 EfenceWarnSideWallR "Mch.MCU.MWIG.EfenceWarnSideWallR";
BA_ "VssSig" SG_ 2566908449 EfenceWarnSideWallL "Mch.MCU.MWIG.EfenceWarnSideWallL";
BA_ "VssSig" SG_ 2566908449 AssitSwgRh "Mch.MCU.MWIG.AssitSwgRh";
BA_ "VssSig" SG_ 2566908449 AssitSwgLh "Mch.MCU.MWIG.AssitSwgLh";
BA_ "VssSig" SG_ 2566908449 AssitBck "Mch.MCU.MWIG.AssitBck";
BA_ "VssSig" SG_ 2566908449 AssitGrd "Mch.MCU.MWIG.AssitGrd";
BA_ "VssSig" SG_ 2566908449 SafeWrkSideFar "Mch.MCU.MWIG.SafeWrkSideFar";
BA_ "VssSig" SG_ 2566908449 SafeWrkSideMid "Mch.MCU.MWIG.SafeWrkSideMid";
BA_ "VssSig" SG_ 2566908449 SafeWrkSideNear "Mch.MCU.MWIG.SafeWrkSideNear";
BA_ "VssSig" SG_ 2566908449 SafeWrkFrFar "Mch.MCU.MWIG.SafeWrkFrFar";
BA_ "VssSig" SG_ 2566908449 SafeWrkFrMid "Mch.MCU.MWIG.SafeWrkFrMid";
BA_ "VssSig" SG_ 2566908449 SafeWrkFrNear "Mch.MCU.MWIG.SafeWrkFrNear";
BA_ "VssSig" SG_ 2566908449 FrMvGuidArmOut "Mch.MCU.MWIG.FrMvGuidArmOut";
BA_ "VssSig" SG_ 2566908449 FrMvGuidArmIn "Mch.MCU.MWIG.FrMvGuidArmIn";
BA_ "VssSig" SG_ 2566908449 FrMvGuidBoomDn "Mch.MCU.MWIG.FrMvGuidBoomDn";
BA_ "VssSig" SG_ 2566908449 FrMvGuidBoomUp "Mch.MCU.MWIG.FrMvGuidBoomUp";
BA_ "VssSig" SG_ 2566908449 EfenceTrkWrn "Mch.MCU.MWIG.EfenceTrkWrn";
BA_ "VssSig" SG_ 2566908449 EfenceDzWrn "Mch.MCU.MWIG.EfenceDzWrn";
BA_ "VssSig" SG_ 2566908449 EfenceCabWrn "Mch.MCU.MWIG.EfenceCabWrn";
BA_ "VssSig" SG_ 2566908449 EfenceFSwgRhWrn "Mch.MCU.MWIG.EfenceFSwgRhWrn";
BA_ "VssSig" SG_ 2566908449 EfenceFSwgLhWrn "Mch.MCU.MWIG.EfenceFSwgLhWrn";
BA_ "VssSig" SG_ 2566908449 EfenceCeilWrn "Mch.MCU.MWIG.EfenceCeilWrn";
BA_ "VssSig" SG_ 2566908449 EfenceFloorWrn "Mch.MCU.MWIG.EfenceFloorWrn";
BA_ "VssSig" SG_ 2566908449 EfenceWallWrn "Mch.MCU.MWIG.EfenceWallWrn";
BA_ "VssSig" SG_ 2566908705 TipOffMnSt "Mch.MCU.TWG.TipOffMnSt";
BA_ "VssSig" SG_ 2566908705 TipOffAstSt "Mch.MCU.TWG.TipOffAstSt";
BA_ "VssSig" SG_ 2566908705 TotWhgCurTrk "Mch.MCU.TWG.TotWhgCurTrk";
BA_ "VssSig" SG_ 2566908705 BckCntCurTrk "Mch.MCU.TWG.BckCntCurTrk";
BA_ "VssSig" SG_ 2566908705 WghCntSt "Mch.MCU.TWG.WghCntSt";
BA_ "VssSig" SG_ 2566908705 WghSt "Mch.MCU.TWG.WghSt";
BA_ "VssSig" SG_ 2566908705 RelTmBckWhg "Mch.MCU.TWG.RelTmBckWhg";
BA_ "VssSig" SG_ 2566908961 EmcvCalbStep "Mch.MCU.WCPR.EmcvCalbStep";
BA_ "VssSig" SG_ 2566908961 EmcvCalbStage "Mch.MCU.WCPR.EmcvCalbStage";
BA_ "VssSig" SG_ 2566908961 BckSingleFastCalbStep "Mch.MCU.WCPR.BckSingleFastCalbStep";
BA_ "VssSig" SG_ 2566908961 BckSingleFastCalbStage "Mch.MCU.WCPR.BckSingleFastCalbStage";
BA_ "VssSig" SG_ 2566908961 BckSingleSlowCalbStep "Mch.MCU.WCPR.BckSingleSlowCalbStep";
BA_ "VssSig" SG_ 2566908961 BckSingleSlowCalbStage "Mch.MCU.WCPR.BckSingleSlowCalbStage";
BA_ "VssSig" SG_ 2566908961 BckZeroCalbStep "Mch.MCU.WCPR.BckZeroCalbStep";
BA_ "VssSig" SG_ 2566908961 BckZeroCalbStage "Mch.MCU.WCPR.BckZeroCalbStage";
BA_ "VssSig" SG_ 2566908961 FrMultiCalbStep "Mch.MCU.WCPR.FrMultiCalbStep";
BA_ "VssSig" SG_ 2566908961 FrMultiCalbStage "Mch.MCU.WCPR.FrMultiCalbStage";
BA_ "VssSig" SG_ 2566908961 FrSngCalbStep "Mch.MCU.WCPR.FrSngCalbStep";
BA_ "VssSig" SG_ 2566908961 FrSngCalbStage "Mch.MCU.WCPR.FrSngCalbStage";
BA_ "VssSig" SG_ 2566909217 TgtArmCylSpdUpLmt "Mch.MCU.WCCV.TgtArmCylSpdUpLmt";
BA_ "VssSig" SG_ 2566909217 TgtArmCylSpdLwLmt "Mch.MCU.WCCV.TgtArmCylSpdLwLmt";
BA_ "VssSig" SG_ 2566909217 CurArmCylSpd "Mch.MCU.WCCV.CurArmCylSpd";
BA_ "VssSig" SG_ 2566909217 TgtBoomCylSpdUpLmt "Mch.MCU.WCCV.TgtBoomCylSpdUpLmt";
BA_ "VssSig" SG_ 2566909217 TgtBoomCylSpdLwLmt "Mch.MCU.WCCV.TgtBoomCylSpdLwLmt";
BA_ "VssSig" SG_ 2566909217 CurBoomCylSpd "Mch.MCU.WCCV.CurBoomCylSpd";
BA_ "VssSig" SG_ 2566909473 TgtArmJointAngEndPos "Mch.MCU.WCJA.TgtArmJointAngEndPos";
BA_ "VssSig" SG_ 2566909473 TgtArmJointAngStartPos "Mch.MCU.WCJA.TgtArmJointAngStartPos";
BA_ "VssSig" SG_ 2566909473 CurArmJointAng "Mch.MCU.WCJA.CurArmJointAng";
BA_ "VssSig" SG_ 2566909473 TgtBoomJointAngEndPos "Mch.MCU.WCJA.TgtBoomJointAngEndPos";
BA_ "VssSig" SG_ 2566909473 TgtBoomJointAngStartPos "Mch.MCU.WCJA.TgtBoomJointAngStartPos";
BA_ "VssSig" SG_ 2566909473 CurBoomJointAng "Mch.MCU.WCJA.CurBoomJointAng";
BA_ "VssSig" SG_ 2566909729 Reach "Mch.MCU.LADG.Reach";
BA_ "VssSig" SG_ 2566909729 Hight "Mch.MCU.LADG.Hight";
BA_ "VssSig" SG_ 2566909729 RatedLoad "Mch.MCU.LADG.RatedLoad";
BA_ "VssSig" SG_ 2566909729 ActLoad "Mch.MCU.LADG.ActLoad";
BA_ "VssSig" SG_ 2566910241 VhcSpdHhRes "Mch.MCU.ASRG.VhcSpdHhRes";
BA_ "VssSig" SG_ 2566910241 SwgSt "Mch.MCU.ASRG.SwgSt";
BA_ "VssSig" SG_ 2566910241 VhcSpdFromSpdSs "Mch.MCU.ASRG.VhcSpdFromSpdSs";
BA_ "VssSig" SG_ 2566910241 SwgAng "Mch.MCU.ASRG.SwgAng";
BA_ "VssSig" SG_ 2566912289 SsOfsRttAng "Mch.MCU.MWHG4.SsOfsRttAng";
BA_ "VssSig" SG_ 2566912289 ImuSsOfsTrttTiltAng "Mch.MCU.MWHG4.ImuSsOfsTrttTiltAng";
BA_ "VssSig" SG_ 2566912289 TrttBodyDmsnTQ4 "Mch.MCU.MWHG4.TrttBodyDmsnTQ4";
BA_ "VssSig" SG_ 2566912289 TrttBodyDmsnDQ4 "Mch.MCU.MWHG4.TrttBodyDmsnDQ4";
BA_ "VssSig" SG_ 2566912289 TrttBodyDmsnAngGdt "Mch.MCU.MWHG4.TrttBodyDmsnAngGdt";
BA_ "VssSig" SG_ 2566912289 TrttBodyDmsnDT "Mch.MCU.MWHG4.TrttBodyDmsnDT";
BA_ "VssSig" SG_ 2566912289 TrttBodyDmsnGT "Mch.MCU.MWHG4.TrttBodyDmsnGT";
BA_ "VssSig" SG_ 2566912289 TrttBodyDmsnDG "Mch.MCU.MWHG4.TrttBodyDmsnDG";
BA_ "VssSig" SG_ 2566912289 TrttBodyDmsnVW "Mch.MCU.MWHG4.TrttBodyDmsnVW";
BA_ "VssSig" SG_ 2566912289 TrttBodyDmsnUV "Mch.MCU.MWHG4.TrttBodyDmsnUV";
BA_ "VssSig" SG_ 2566912289 TrttBodyDmsnTU "Mch.MCU.MWHG4.TrttBodyDmsnTU";
BA_ "VssSig" SG_ 2566912289 TrttBck05DmsnAngVwn "Mch.MCU.MWHG4.TrttBck05DmsnAngVwn";
BA_ "VssSig" SG_ 2566912289 TrttBck05DmsnTN "Mch.MCU.MWHG4.TrttBck05DmsnTN";
BA_ "VssSig" SG_ 2566912289 TrttBck05DmsnWN "Mch.MCU.MWHG4.TrttBck05DmsnWN";
BA_ "VssSig" SG_ 2566912289 TrttBck05DmsnWT "Mch.MCU.MWHG4.TrttBck05DmsnWT";
BA_ "VssSig" SG_ 2566912289 TrttBck05DmsnNQ3 "Mch.MCU.MWHG4.TrttBck05DmsnNQ3";
BA_ "VssSig" SG_ 2566912289 TrttBck05DmsnWQ3 "Mch.MCU.MWHG4.TrttBck05DmsnWQ3";
BA_ "VssSig" SG_ 2566912289 TrttBck05DmsnNQ2 "Mch.MCU.MWHG4.TrttBck05DmsnNQ2";
BA_ "VssSig" SG_ 2566912289 TrttBck05DmsnWQ2 "Mch.MCU.MWHG4.TrttBck05DmsnWQ2";
BA_ "VssSig" SG_ 2566912289 TrttBck05DmsnWidth "Mch.MCU.MWHG4.TrttBck05DmsnWidth";
BA_ "VssSig" SG_ 2566912289 TrttBck05DmsnNQ1 "Mch.MCU.MWHG4.TrttBck05DmsnNQ1";
BA_ "VssSig" SG_ 2566912289 TrttBck05DmsnWQ1 "Mch.MCU.MWHG4.TrttBck05DmsnWQ1";
BA_ "VssSig" SG_ 2566912289 TrttBck04DmsnAngVwn "Mch.MCU.MWHG4.TrttBck04DmsnAngVwn";
BA_ "VssSig" SG_ 2566912289 TrttBck04DmsnTN "Mch.MCU.MWHG4.TrttBck04DmsnTN";
BA_ "VssSig" SG_ 2566912289 TrttBck04DmsnWN "Mch.MCU.MWHG4.TrttBck04DmsnWN";
BA_ "VssSig" SG_ 2566912289 TrttBck04DmsnWT "Mch.MCU.MWHG4.TrttBck04DmsnWT";
BA_ "VssSig" SG_ 2566912289 TrttBck04DmsnNQ3 "Mch.MCU.MWHG4.TrttBck04DmsnNQ3";
BA_ "VssSig" SG_ 2566912289 TrttBck04DmsnWQ3 "Mch.MCU.MWHG4.TrttBck04DmsnWQ3";
BA_ "VssSig" SG_ 2566912289 TrttBck04DmsnNQ2 "Mch.MCU.MWHG4.TrttBck04DmsnNQ2";
BA_ "VssSig" SG_ 2566912289 TrttBck04DmsnWQ2 "Mch.MCU.MWHG4.TrttBck04DmsnWQ2";
BA_ "VssSig" SG_ 2566912289 TrttBck04DmsnWidth "Mch.MCU.MWHG4.TrttBck04DmsnWidth";
BA_ "VssSig" SG_ 2566912289 TrttBck04DmsnNQ1 "Mch.MCU.MWHG4.TrttBck04DmsnNQ1";
BA_ "VssSig" SG_ 2566912289 TrttBck04DmsnWQ1 "Mch.MCU.MWHG4.TrttBck04DmsnWQ1";
BA_ "VssSig" SG_ 2566912289 TrttBck03DmsnAngVwn "Mch.MCU.MWHG4.TrttBck03DmsnAngVwn";
BA_ "VssSig" SG_ 2566912289 TrttBck03DmsnTN "Mch.MCU.MWHG4.TrttBck03DmsnTN";
BA_ "VssSig" SG_ 2566912289 TrttBck03DmsnWN "Mch.MCU.MWHG4.TrttBck03DmsnWN";
BA_ "VssSig" SG_ 2566912289 TrttBck03DmsnWT "Mch.MCU.MWHG4.TrttBck03DmsnWT";
BA_ "VssSig" SG_ 2566912289 TrttBck03DmsnNQ3 "Mch.MCU.MWHG4.TrttBck03DmsnNQ3";
BA_ "VssSig" SG_ 2566912289 TrttBck03DmsnWQ3 "Mch.MCU.MWHG4.TrttBck03DmsnWQ3";
BA_ "VssSig" SG_ 2566912289 TrttBck03DmsnNQ2 "Mch.MCU.MWHG4.TrttBck03DmsnNQ2";
BA_ "VssSig" SG_ 2566912289 TrttBck03DmsnWQ2 "Mch.MCU.MWHG4.TrttBck03DmsnWQ2";
BA_ "VssSig" SG_ 2566912289 TrttBck03DmsnWidth "Mch.MCU.MWHG4.TrttBck03DmsnWidth";
BA_ "VssSig" SG_ 2566912289 TrttBck03DmsnNQ1 "Mch.MCU.MWHG4.TrttBck03DmsnNQ1";
BA_ "VssSig" SG_ 2566912289 TrttBck03DmsnWQ1 "Mch.MCU.MWHG4.TrttBck03DmsnWQ1";
BA_ "VssSig" SG_ 2566912289 TrttBck02DmsnAngVwn "Mch.MCU.MWHG4.TrttBck02DmsnAngVwn";
BA_ "VssSig" SG_ 2566912289 TrttBck02DmsnTN "Mch.MCU.MWHG4.TrttBck02DmsnTN";
BA_ "VssSig" SG_ 2566912289 TrttBck02DmsnWN "Mch.MCU.MWHG4.TrttBck02DmsnWN";
BA_ "VssSig" SG_ 2566912289 TrttBck02DmsnWT "Mch.MCU.MWHG4.TrttBck02DmsnWT";
BA_ "VssSig" SG_ 2566912289 TrttBck02DmsnNQ3 "Mch.MCU.MWHG4.TrttBck02DmsnNQ3";
BA_ "VssSig" SG_ 2566912289 TrttBck02DmsnWQ3 "Mch.MCU.MWHG4.TrttBck02DmsnWQ3";
BA_ "VssSig" SG_ 2566912289 TrttBck02DmsnNQ2 "Mch.MCU.MWHG4.TrttBck02DmsnNQ2";
BA_ "VssSig" SG_ 2566912289 TrttBck02DmsnWQ2 "Mch.MCU.MWHG4.TrttBck02DmsnWQ2";
BA_ "VssSig" SG_ 2566912289 TrttBck02DmsnWidth "Mch.MCU.MWHG4.TrttBck02DmsnWidth";
BA_ "VssSig" SG_ 2566912289 TrttBck02DmsnNQ1 "Mch.MCU.MWHG4.TrttBck02DmsnNQ1";
BA_ "VssSig" SG_ 2566912289 TrttBck02DmsnWQ1 "Mch.MCU.MWHG4.TrttBck02DmsnWQ1";
BA_ "VssSig" SG_ 2566912289 TrttBck01DmsnAngVwn "Mch.MCU.MWHG4.TrttBck01DmsnAngVwn";
BA_ "VssSig" SG_ 2566912289 TrttBck01DmsnTN "Mch.MCU.MWHG4.TrttBck01DmsnTN";
BA_ "VssSig" SG_ 2566912289 TrttBck01DmsnWN "Mch.MCU.MWHG4.TrttBck01DmsnWN";
BA_ "VssSig" SG_ 2566912289 TrttBck01DmsnWT "Mch.MCU.MWHG4.TrttBck01DmsnWT";
BA_ "VssSig" SG_ 2566912289 TrttBck01DmsnNQ3 "Mch.MCU.MWHG4.TrttBck01DmsnNQ3";
BA_ "VssSig" SG_ 2566912289 TrttBck01DmsnWQ3 "Mch.MCU.MWHG4.TrttBck01DmsnWQ3";
BA_ "VssSig" SG_ 2566912289 TrttBck01DmsnNQ2 "Mch.MCU.MWHG4.TrttBck01DmsnNQ2";
BA_ "VssSig" SG_ 2566912289 TrttBck01DmsnWQ2 "Mch.MCU.MWHG4.TrttBck01DmsnWQ2";
BA_ "VssSig" SG_ 2566912289 TrttBck01DmsnWidth "Mch.MCU.MWHG4.TrttBck01DmsnWidth";
BA_ "VssSig" SG_ 2566912289 TrttBck01DmsnNQ1 "Mch.MCU.MWHG4.TrttBck01DmsnNQ1";
BA_ "VssSig" SG_ 2566912289 TrttBck01DmsnWQ1 "Mch.MCU.MWHG4.TrttBck01DmsnWQ1";
BA_ "VssSig" SG_ 2566912545 Bck05DmsnAngGdn "Mch.MCU.MWHG1.Bck05DmsnAngGdn";
BA_ "VssSig" SG_ 2566912545 Bck05DmsnDT "Mch.MCU.MWHG1.Bck05DmsnDT";
BA_ "VssSig" SG_ 2566912545 Bck05DmsnNQ3 "Mch.MCU.MWHG1.Bck05DmsnNQ3";
BA_ "VssSig" SG_ 2566912545 Bck05DmsnDQ3 "Mch.MCU.MWHG1.Bck05DmsnDQ3";
BA_ "VssSig" SG_ 2566912545 Bck05DmsnNQ2 "Mch.MCU.MWHG1.Bck05DmsnNQ2";
BA_ "VssSig" SG_ 2566912545 Bck05DmsnDQ2 "Mch.MCU.MWHG1.Bck05DmsnDQ2";
BA_ "VssSig" SG_ 2566912545 Bck05DmsnTN "Mch.MCU.MWHG1.Bck05DmsnTN";
BA_ "VssSig" SG_ 2566912545 Bck05DmsnWidth "Mch.MCU.MWHG1.Bck05DmsnWidth";
BA_ "VssSig" SG_ 2566912545 Bck05DmsnNQ1 "Mch.MCU.MWHG1.Bck05DmsnNQ1";
BA_ "VssSig" SG_ 2566912545 Bck05DmsnDQ1 "Mch.MCU.MWHG1.Bck05DmsnDQ1";
BA_ "VssSig" SG_ 2566912545 Bck05DmsnDN "Mch.MCU.MWHG1.Bck05DmsnDN";
BA_ "VssSig" SG_ 2566912545 Bck05DmsnDG "Mch.MCU.MWHG1.Bck05DmsnDG";
BA_ "VssSig" SG_ 2566912545 Bck04DmsnAngGdn "Mch.MCU.MWHG1.Bck04DmsnAngGdn";
BA_ "VssSig" SG_ 2566912545 Bck04DmsnDT "Mch.MCU.MWHG1.Bck04DmsnDT";
BA_ "VssSig" SG_ 2566912545 Bck04DmsnNQ3 "Mch.MCU.MWHG1.Bck04DmsnNQ3";
BA_ "VssSig" SG_ 2566912545 Bck04DmsnDQ3 "Mch.MCU.MWHG1.Bck04DmsnDQ3";
BA_ "VssSig" SG_ 2566912545 Bck04DmsnNQ2 "Mch.MCU.MWHG1.Bck04DmsnNQ2";
BA_ "VssSig" SG_ 2566912545 Bck04DmsnDQ2 "Mch.MCU.MWHG1.Bck04DmsnDQ2";
BA_ "VssSig" SG_ 2566912545 Bck04DmsnTN "Mch.MCU.MWHG1.Bck04DmsnTN";
BA_ "VssSig" SG_ 2566912545 Bck04DmsnWidth "Mch.MCU.MWHG1.Bck04DmsnWidth";
BA_ "VssSig" SG_ 2566912545 Bck04DmsnNQ1 "Mch.MCU.MWHG1.Bck04DmsnNQ1";
BA_ "VssSig" SG_ 2566912545 Bck04DmsnDQ1 "Mch.MCU.MWHG1.Bck04DmsnDQ1";
BA_ "VssSig" SG_ 2566912545 Bck04DmsnDN "Mch.MCU.MWHG1.Bck04DmsnDN";
BA_ "VssSig" SG_ 2566912545 Bck04DmsnDG "Mch.MCU.MWHG1.Bck04DmsnDG";
BA_ "VssSig" SG_ 2566912545 Bck03DmsnAngGdn "Mch.MCU.MWHG1.Bck03DmsnAngGdn";
BA_ "VssSig" SG_ 2566912545 Bck03DmsnDT "Mch.MCU.MWHG1.Bck03DmsnDT";
BA_ "VssSig" SG_ 2566912545 Bck03DmsnNQ3 "Mch.MCU.MWHG1.Bck03DmsnNQ3";
BA_ "VssSig" SG_ 2566912545 Bck03DmsnDQ3 "Mch.MCU.MWHG1.Bck03DmsnDQ3";
BA_ "VssSig" SG_ 2566912545 Bck03DmsnNQ2 "Mch.MCU.MWHG1.Bck03DmsnNQ2";
BA_ "VssSig" SG_ 2566912545 Bck03DmsnDQ2 "Mch.MCU.MWHG1.Bck03DmsnDQ2";
BA_ "VssSig" SG_ 2566912545 Bck03DmsnTN "Mch.MCU.MWHG1.Bck03DmsnTN";
BA_ "VssSig" SG_ 2566912545 Bck03DmsnWidth "Mch.MCU.MWHG1.Bck03DmsnWidth";
BA_ "VssSig" SG_ 2566912545 Bck03DmsnNQ1 "Mch.MCU.MWHG1.Bck03DmsnNQ1";
BA_ "VssSig" SG_ 2566912545 Bck03DmsnDQ1 "Mch.MCU.MWHG1.Bck03DmsnDQ1";
BA_ "VssSig" SG_ 2566912545 Bck03DmsnDN "Mch.MCU.MWHG1.Bck03DmsnDN";
BA_ "VssSig" SG_ 2566912545 Bck03DmsnDG "Mch.MCU.MWHG1.Bck03DmsnDG";
BA_ "VssSig" SG_ 2566912545 Bck02DmsnAngGdn "Mch.MCU.MWHG1.Bck02DmsnAngGdn";
BA_ "VssSig" SG_ 2566912545 Bck02DmsnDT "Mch.MCU.MWHG1.Bck02DmsnDT";
BA_ "VssSig" SG_ 2566912545 Bck02DmsnNQ3 "Mch.MCU.MWHG1.Bck02DmsnNQ3";
BA_ "VssSig" SG_ 2566912545 Bck02DmsnDQ3 "Mch.MCU.MWHG1.Bck02DmsnDQ3";
BA_ "VssSig" SG_ 2566912545 Bck02DmsnNQ2 "Mch.MCU.MWHG1.Bck02DmsnNQ2";
BA_ "VssSig" SG_ 2566912545 Bck02DmsnDQ2 "Mch.MCU.MWHG1.Bck02DmsnDQ2";
BA_ "VssSig" SG_ 2566912545 Bck02DmsnTN "Mch.MCU.MWHG1.Bck02DmsnTN";
BA_ "VssSig" SG_ 2566912545 Bck02DmsnWidth "Mch.MCU.MWHG1.Bck02DmsnWidth";
BA_ "VssSig" SG_ 2566912545 Bck02DmsnNQ1 "Mch.MCU.MWHG1.Bck02DmsnNQ1";
BA_ "VssSig" SG_ 2566912545 Bck02DmsnDQ1 "Mch.MCU.MWHG1.Bck02DmsnDQ1";
BA_ "VssSig" SG_ 2566912545 Bck02DmsnDN "Mch.MCU.MWHG1.Bck02DmsnDN";
BA_ "VssSig" SG_ 2566912545 Bck02DmsnDG "Mch.MCU.MWHG1.Bck02DmsnDG";
BA_ "VssSig" SG_ 2566912545 Bck01DmsnAngGdn "Mch.MCU.MWHG1.Bck01DmsnAngGdn";
BA_ "VssSig" SG_ 2566912545 Bck01DmsnDT "Mch.MCU.MWHG1.Bck01DmsnDT";
BA_ "VssSig" SG_ 2566912545 Bck01DmsnNQ3 "Mch.MCU.MWHG1.Bck01DmsnNQ3";
BA_ "VssSig" SG_ 2566912545 Bck01DmsnDQ3 "Mch.MCU.MWHG1.Bck01DmsnDQ3";
BA_ "VssSig" SG_ 2566912545 Bck01DmsnNQ2 "Mch.MCU.MWHG1.Bck01DmsnNQ2";
BA_ "VssSig" SG_ 2566912545 Bck01DmsnDQ2 "Mch.MCU.MWHG1.Bck01DmsnDQ2";
BA_ "VssSig" SG_ 2566912545 Bck01DmsnTN "Mch.MCU.MWHG1.Bck01DmsnTN";
BA_ "VssSig" SG_ 2566912545 Bck01DmsnWidth "Mch.MCU.MWHG1.Bck01DmsnWidth";
BA_ "VssSig" SG_ 2566912545 Bck01DmsnNQ1 "Mch.MCU.MWHG1.Bck01DmsnNQ1";
BA_ "VssSig" SG_ 2566912545 Bck01DmsnDQ1 "Mch.MCU.MWHG1.Bck01DmsnDQ1";
BA_ "VssSig" SG_ 2566912545 Bck01DmsnDN "Mch.MCU.MWHG1.Bck01DmsnDN";
BA_ "VssSig" SG_ 2566912545 Bck01DmsnDG "Mch.MCU.MWHG1.Bck01DmsnDG";
BA_ "VssSig" SG_ 2566912801 JoyFuncAssnRhBtn14 "Mch.MCU.MWHG2.JoyFuncAssnRhBtn14";
BA_ "VssSig" SG_ 2566912801 JoyFuncAssnRhBtn13 "Mch.MCU.MWHG2.JoyFuncAssnRhBtn13";
BA_ "VssSig" SG_ 2566912801 JoyFuncAssnRhBtn12 "Mch.MCU.MWHG2.JoyFuncAssnRhBtn12";
BA_ "VssSig" SG_ 2566912801 JoyFuncAssnRhBtn11 "Mch.MCU.MWHG2.JoyFuncAssnRhBtn11";
BA_ "VssSig" SG_ 2566912801 JoyFuncAssnLhBtn14 "Mch.MCU.MWHG2.JoyFuncAssnLhBtn14";
BA_ "VssSig" SG_ 2566912801 JoyFuncAssnLhBtn13 "Mch.MCU.MWHG2.JoyFuncAssnLhBtn13";
BA_ "VssSig" SG_ 2566912801 JoyFuncAssnLhBtn12 "Mch.MCU.MWHG2.JoyFuncAssnLhBtn12";
BA_ "VssSig" SG_ 2566912801 JoyFuncAssnLhBtn11 "Mch.MCU.MWHG2.JoyFuncAssnLhBtn11";
BA_ "VssSig" SG_ 2566912801 DacCoordinateSystem "Mch.MCU.MWHG2.DacCoordinateSystem";
BA_ "VssSig" SG_ 2566912801 DacAutoMdSelect "Mch.MCU.MWHG2.DacAutoMdSelect";
BA_ "VssSig" SG_ 2566912801 CrwTipCalbLen "Mch.MCU.MWHG2.CrwTipCalbLen";
BA_ "VssSig" SG_ 2566912801 ImuSsOfsBladeRoll "Mch.MCU.MWHG2.ImuSsOfsBladeRoll";
BA_ "VssSig" SG_ 2566912801 ImuSsOfsBladePch "Mch.MCU.MWHG2.ImuSsOfsBladePch";
BA_ "VssSig" SG_ 2566912801 ImuSsOfsCfrmRoll "Mch.MCU.MWHG2.ImuSsOfsCfrmRoll";
BA_ "VssSig" SG_ 2566912801 ImuSsOfsCfrmPch "Mch.MCU.MWHG2.ImuSsOfsCfrmPch";
BA_ "VssSig" SG_ 2566912801 BladeTipCalbLen "Mch.MCU.MWHG2.BladeTipCalbLen";
BA_ "VssSig" SG_ 2566912801 BladeJointCalbLen "Mch.MCU.MWHG2.BladeJointCalbLen";
BA_ "VssSig" SG_ 2566912801 GrdAstPrfDsnDt01PntZ09 "Mch.MCU.MWHG2.GrdAstPrfDsnDt01PntZ09";
BA_ "VssSig" SG_ 2566912801 GrdAstPrfDsnDt01PntY09 "Mch.MCU.MWHG2.GrdAstPrfDsnDt01PntY09";
BA_ "VssSig" SG_ 2566912801 GrdAstPrfDsnDt01PntZ08 "Mch.MCU.MWHG2.GrdAstPrfDsnDt01PntZ08";
BA_ "VssSig" SG_ 2566912801 GrdAstPrfDsnDt01PntY08 "Mch.MCU.MWHG2.GrdAstPrfDsnDt01PntY08";
BA_ "VssSig" SG_ 2566912801 GrdAstPrfDsnDt01PntZ07 "Mch.MCU.MWHG2.GrdAstPrfDsnDt01PntZ07";
BA_ "VssSig" SG_ 2566912801 GrdAstPrfDsnDt01PntY07 "Mch.MCU.MWHG2.GrdAstPrfDsnDt01PntY07";
BA_ "VssSig" SG_ 2566912801 GrdAstPrfDsnDt01PntZ06 "Mch.MCU.MWHG2.GrdAstPrfDsnDt01PntZ06";
BA_ "VssSig" SG_ 2566912801 GrdAstPrfDsnDt01PntY06 "Mch.MCU.MWHG2.GrdAstPrfDsnDt01PntY06";
BA_ "VssSig" SG_ 2566912801 GrdAstPrfDsnDt01PntZ05 "Mch.MCU.MWHG2.GrdAstPrfDsnDt01PntZ05";
BA_ "VssSig" SG_ 2566912801 GrdAstPrfDsnDt01PntY05 "Mch.MCU.MWHG2.GrdAstPrfDsnDt01PntY05";
BA_ "VssSig" SG_ 2566912801 GrdAstPrfDsnDt01PntZ04 "Mch.MCU.MWHG2.GrdAstPrfDsnDt01PntZ04";
BA_ "VssSig" SG_ 2566912801 GrdAstPrfDsnDt01PntY04 "Mch.MCU.MWHG2.GrdAstPrfDsnDt01PntY04";
BA_ "VssSig" SG_ 2566912801 GrdAstPrfDsnDt01PntZ03 "Mch.MCU.MWHG2.GrdAstPrfDsnDt01PntZ03";
BA_ "VssSig" SG_ 2566912801 GrdAstPrfDsnDt01PntY03 "Mch.MCU.MWHG2.GrdAstPrfDsnDt01PntY03";
BA_ "VssSig" SG_ 2566912801 GrdAstPrfDsnDt01PntZ02 "Mch.MCU.MWHG2.GrdAstPrfDsnDt01PntZ02";
BA_ "VssSig" SG_ 2566912801 GrdAstPrfDsnDt01PntY02 "Mch.MCU.MWHG2.GrdAstPrfDsnDt01PntY02";
BA_ "VssSig" SG_ 2566912801 GrdAstPrfDsnDt01PntZ01 "Mch.MCU.MWHG2.GrdAstPrfDsnDt01PntZ01";
BA_ "VssSig" SG_ 2566912801 GrdAstPrfDsnDt01PntY01 "Mch.MCU.MWHG2.GrdAstPrfDsnDt01PntY01";
BA_ "VssSig" SG_ 2566912801 CrossSlopeDsnDt "Mch.MCU.MWHG2.CrossSlopeDsnDt";
BA_ "VssSig" SG_ 2566912801 SlopeDsnDt "Mch.MCU.MWHG2.SlopeDsnDt";
BA_ "VssSig" SG_ 2566912801 DepthDsnDt "Mch.MCU.MWHG2.DepthDsnDt";
BA_ "VssSig" SG_ 2566912801 JoyFuncAssnRhThw05 "Mch.MCU.MWHG2.JoyFuncAssnRhThw05";
BA_ "VssSig" SG_ 2566912801 JoyFuncAssnRhThw04 "Mch.MCU.MWHG2.JoyFuncAssnRhThw04";
BA_ "VssSig" SG_ 2566912801 JoyFuncAssnRhThw03 "Mch.MCU.MWHG2.JoyFuncAssnRhThw03";
BA_ "VssSig" SG_ 2566912801 JoyFuncAssnRhThw02 "Mch.MCU.MWHG2.JoyFuncAssnRhThw02";
BA_ "VssSig" SG_ 2566912801 JoyFuncAssnRhThw01 "Mch.MCU.MWHG2.JoyFuncAssnRhThw01";
BA_ "VssSig" SG_ 2566912801 JoyFuncAssnLhThw05 "Mch.MCU.MWHG2.JoyFuncAssnLhThw05";
BA_ "VssSig" SG_ 2566912801 JoyFuncAssnLhThw04 "Mch.MCU.MWHG2.JoyFuncAssnLhThw04";
BA_ "VssSig" SG_ 2566912801 JoyFuncAssnLhThw03 "Mch.MCU.MWHG2.JoyFuncAssnLhThw03";
BA_ "VssSig" SG_ 2566912801 JoyFuncAssnLhThw02 "Mch.MCU.MWHG2.JoyFuncAssnLhThw02";
BA_ "VssSig" SG_ 2566912801 JoyFuncAssnLhThw01 "Mch.MCU.MWHG2.JoyFuncAssnLhThw01";
BA_ "VssSig" SG_ 2566912801 JoyFuncAssnRhBtn10 "Mch.MCU.MWHG2.JoyFuncAssnRhBtn10";
BA_ "VssSig" SG_ 2566912801 JoyFuncAssnRhBtn09 "Mch.MCU.MWHG2.JoyFuncAssnRhBtn09";
BA_ "VssSig" SG_ 2566912801 JoyFuncAssnRhBtn08 "Mch.MCU.MWHG2.JoyFuncAssnRhBtn08";
BA_ "VssSig" SG_ 2566912801 JoyFuncAssnRhBtn07 "Mch.MCU.MWHG2.JoyFuncAssnRhBtn07";
BA_ "VssSig" SG_ 2566912801 JoyFuncAssnRhBtn06 "Mch.MCU.MWHG2.JoyFuncAssnRhBtn06";
BA_ "VssSig" SG_ 2566912801 JoyFuncAssnRhBtn05 "Mch.MCU.MWHG2.JoyFuncAssnRhBtn05";
BA_ "VssSig" SG_ 2566912801 JoyFuncAssnRhBtn04 "Mch.MCU.MWHG2.JoyFuncAssnRhBtn04";
BA_ "VssSig" SG_ 2566912801 JoyFuncAssnRhBtn03 "Mch.MCU.MWHG2.JoyFuncAssnRhBtn03";
BA_ "VssSig" SG_ 2566912801 JoyFuncAssnRhBtn02 "Mch.MCU.MWHG2.JoyFuncAssnRhBtn02";
BA_ "VssSig" SG_ 2566912801 JoyFuncAssnRhBtn01 "Mch.MCU.MWHG2.JoyFuncAssnRhBtn01";
BA_ "VssSig" SG_ 2566912801 JoyFuncAssnLhBtn10 "Mch.MCU.MWHG2.JoyFuncAssnLhBtn10";
BA_ "VssSig" SG_ 2566912801 JoyFuncAssnLhBtn09 "Mch.MCU.MWHG2.JoyFuncAssnLhBtn09";
BA_ "VssSig" SG_ 2566912801 JoyFuncAssnLhBtn08 "Mch.MCU.MWHG2.JoyFuncAssnLhBtn08";
BA_ "VssSig" SG_ 2566912801 JoyFuncAssnLhBtn07 "Mch.MCU.MWHG2.JoyFuncAssnLhBtn07";
BA_ "VssSig" SG_ 2566912801 JoyFuncAssnLhBtn06 "Mch.MCU.MWHG2.JoyFuncAssnLhBtn06";
BA_ "VssSig" SG_ 2566912801 JoyFuncAssnLhBtn05 "Mch.MCU.MWHG2.JoyFuncAssnLhBtn05";
BA_ "VssSig" SG_ 2566912801 JoyFuncAssnLhBtn04 "Mch.MCU.MWHG2.JoyFuncAssnLhBtn04";
BA_ "VssSig" SG_ 2566912801 JoyFuncAssnLhBtn03 "Mch.MCU.MWHG2.JoyFuncAssnLhBtn03";
BA_ "VssSig" SG_ 2566912801 JoyFuncAssnLhBtn02 "Mch.MCU.MWHG2.JoyFuncAssnLhBtn02";
BA_ "VssSig" SG_ 2566912801 JoyFuncAssnLhBtn01 "Mch.MCU.MWHG2.JoyFuncAssnLhBtn01";
BA_ "VssSig" SG_ 2566912801 ImuSsOfsBucket "Mch.MCU.MWHG2.ImuSsOfsBucket";
BA_ "VssSig" SG_ 2566912801 ImuSsOfsArtiArmPch "Mch.MCU.MWHG2.ImuSsOfsArtiArmPch";
BA_ "VssSig" SG_ 2566912801 ImuSsOfsArmPch "Mch.MCU.MWHG2.ImuSsOfsArmPch";
BA_ "VssSig" SG_ 2566912801 ImuSsOfsBoomPch "Mch.MCU.MWHG2.ImuSsOfsBoomPch";
BA_ "VssSig" SG_ 2566912801 ImuSsOfsBodyRoll "Mch.MCU.MWHG2.ImuSsOfsBodyRoll";
BA_ "VssSig" SG_ 2566912801 ImuSsOfsBodyPch "Mch.MCU.MWHG2.ImuSsOfsBodyPch";
BA_ "VssSig" SG_ 2566912801 SelectedBucketNo "Mch.MCU.MWHG2.SelectedBucketNo";
BA_ "VssSig" SG_ 2566913057 MaterialName "Mch.MCU.MWHG3.MaterialName";
BA_ "VssSig" SG_ 2566913057 TrkName "Mch.MCU.MWHG3.TrkName";
BA_ "VssSig" SG_ 2566913057 BchmkZOfs "Mch.MCU.MWHG3.BchmkZOfs";
BA_ "VssSig" SG_ 2566913057 BchmkYOfs "Mch.MCU.MWHG3.BchmkYOfs";
BA_ "VssSig" SG_ 2566913057 BchmkXOfs "Mch.MCU.MWHG3.BchmkXOfs";
BA_ "VssSig" SG_ 2566913057 TrkCount "Mch.MCU.MWHG3.TrkCount";
BA_ "VssSig" SG_ 2566913057 SelMaterialDensity "Mch.MCU.MWHG3.SelMaterialDensity";
BA_ "VssSig" SG_ 2566913057 SelTrkTgtWgh "Mch.MCU.MWHG3.SelTrkTgtWgh";
BA_ "VssSig" SG_ 2566913057 BckRefPnt "Mch.MCU.MWHG3.BckRefPnt";
BA_ "VssSig" SG_ 2566913057 ArtiBoomDmsnOpt "Mch.MCU.MWHG3.ArtiBoomDmsnOpt";
BA_ "VssSig" SG_ 2566913057 ArmDmsnOpt "Mch.MCU.MWHG3.ArmDmsnOpt";
BA_ "VssSig" SG_ 2566913057 BoomDmsnOpt "Mch.MCU.MWHG3.BoomDmsnOpt";
BA_ "VssSig" SG_ 2566913057 SetExcessiveDigPrt "Mch.MCU.MWHG3.SetExcessiveDigPrt";
BA_ "VssSig" SG_ 2566913057 GrdAstMd "Mch.MCU.MWHG3.GrdAstMd";
BA_ "VssSig" SG_ 2566913057 GrdAstAccuracy "Mch.MCU.MWHG3.GrdAstAccuracy";
BA_ "VssSig" SG_ 2566913057 TrkShoeWidth "Mch.MCU.MWHG3.TrkShoeWidth";
BA_ "VssSig" SG_ 2566913313 EfenceTgSetSideWallR "Mch.MCU.MWTSV.EfenceTgSetSideWallR";
BA_ "VssSig" SG_ 2566913313 EfenceTgSetSideWallL "Mch.MCU.MWTSV.EfenceTgSetSideWallL";
BA_ "VssSig" SG_ 2566913313 EfenceTgSetCabin "Mch.MCU.MWTSV.EfenceTgSetCabin";
BA_ "VssSig" SG_ 2566913313 SwgAstAngTgtSetSwgLh "Mch.MCU.MWTSV.SwgAstAngTgtSetSwgLh";
BA_ "VssSig" SG_ 2566913313 SwgAstAngTgtSetSwgRh "Mch.MCU.MWTSV.SwgAstAngTgtSetSwgRh";
BA_ "VssSig" SG_ 2566913313 EfenceTgtSetSwgRh "Mch.MCU.MWTSV.EfenceTgtSetSwgRh";
BA_ "VssSig" SG_ 2566913313 EfenceTgtSetSwgLh "Mch.MCU.MWTSV.EfenceTgtSetSwgLh";
BA_ "VssSig" SG_ 2566913313 EfenceTgtSetCeil "Mch.MCU.MWTSV.EfenceTgtSetCeil";
BA_ "VssSig" SG_ 2566913313 EfenceTgtSetFloor "Mch.MCU.MWTSV.EfenceTgtSetFloor";
BA_ "VssSig" SG_ 2566913313 EfenceTgtSetWall "Mch.MCU.MWTSV.EfenceTgtSetWall";
BA_ "VssSig" SG_ 2566913569 CompanyName "Mch.MCU.MTSI.CompanyName";
BA_ "VssSig" SG_ 2566913569 TgWghofCurTrk "Mch.MCU.MTSI.TgWghofCurTrk";
BA_ "VssSig" SG_ 2566913569 TrkCntFinalTm "Mch.MCU.MTSI.TrkCntFinalTm";
BA_ "VssSig" SG_ 2566913569 MaterialLoadSt "Mch.MCU.MTSI.MaterialLoadSt";
BA_ "VssSig" SG_ 2566913569 TotWghCurTrk "Mch.MCU.MTSI.TotWghCurTrk";
BA_ "VssSig" SG_ 2566913569 BckCntCurTrk "Mch.MCU.MTSI.BckCntCurTrk";
BA_ "VssSig" SG_ 2566913569 MtrDensity "Mch.MCU.MTSI.MtrDensity";
BA_ "VssSig" SG_ 2566913569 MtrName "Mch.MCU.MTSI.MtrName";
BA_ "VssSig" SG_ 2566913569 TrkName "Mch.MCU.MTSI.TrkName";
BA_ "VssSig" SG_ 2566913825 TotAcmtWgh "Mch.MCU.MAWI.TotAcmtWgh";
BA_ "VssSig" SG_ 2566913825 TotAcmtBckCnt "Mch.MCU.MAWI.TotAcmtBckCnt";
BA_ "VssSig" SG_ 2583646241 TrvlLhSpoolCmd "Mch.MCU.FPSSC.TrvlLhSpoolCmd";
BA_ "VssSig" SG_ 2583646241 ArmConfSpoolCmd "Mch.MCU.FPSSC.ArmConfSpoolCmd";
BA_ "VssSig" SG_ 2583646241 BckSpoolCmd "Mch.MCU.FPSSC.BckSpoolCmd";
BA_ "VssSig" SG_ 2583646241 BoomSpoolCmd "Mch.MCU.FPSSC.BoomSpoolCmd";
BA_ "VssSig" SG_ 2583646497 TrvlrightSpoolCmd "Mch.MCU.RPSSC.TrvlrightSpoolCmd";
BA_ "VssSig" SG_ 2583646497 BoomConfSpoolCmd "Mch.MCU.RPSSC.BoomConfSpoolCmd";
BA_ "VssSig" SG_ 2583646497 SwgSpoolCmd "Mch.MCU.RPSSC.SwgSpoolCmd";
BA_ "VssSig" SG_ 2583646497 ArmSpoolCmd "Mch.MCU.RPSSC.ArmSpoolCmd";
BA_ "VssSig" SG_ 2583646753 ArtiBoomConfSpoolCmd "Mch.MCU.OSSC.ArtiBoomConfSpoolCmd";
BA_ "VssSig" SG_ 2583646753 DzSpoolCmd "Mch.MCU.OSSC.DzSpoolCmd";
BA_ "VssSig" SG_ 2583646753 OptSpoolCmd "Mch.MCU.OSSC.OptSpoolCmd";
BA_ "VssSig" SG_ 2583651424 TrvlleftSplDlyCmd "Mch.MCU2.FPDSSC.TrvlleftSplDlyCmd";
BA_ "VssSig" SG_ 2583651424 BckSplDlyCmd "Mch.MCU2.FPDSSC.BckSplDlyCmd";
BA_ "VssSig" SG_ 2583651424 ArmCnfSplDlyCmd "Mch.MCU2.FPDSSC.ArmCnfSplDlyCmd";
BA_ "VssSig" SG_ 2583651424 BoomSplDlyCmd "Mch.MCU2.FPDSSC.BoomSplDlyCmd";
BA_ "VssSig" SG_ 2583651680 TrvlrightSplDlyCmd "Mch.MCU2.RPDSSC.TrvlrightSplDlyCmd";
BA_ "VssSig" SG_ 2583651680 SwgSplDlyCmd "Mch.MCU2.RPDSSC.SwgSplDlyCmd";
BA_ "VssSig" SG_ 2583651680 BoomCnfSplDlyCmd "Mch.MCU2.RPDSSC.BoomCnfSplDlyCmd";
BA_ "VssSig" SG_ 2583651680 ArmSplDlyCmd "Mch.MCU2.RPDSSC.ArmSplDlyCmd";
BA_ "VssSig" SG_ 2583651936 ArtiboomSplDlyCmd "Mch.MCU2.ODSSC.ArtiboomSplDlyCmd";
BA_ "VssSig" SG_ 2583651936 DzSplDlyCmd "Mch.MCU2.ODSSC.DzSplDlyCmd";
BA_ "VssSig" SG_ 2583651936 OptSplDlyCmd "Mch.MCU2.ODSSC.OptSplDlyCmd";
BA_ "VssSig" SG_ 2583654752 BckdumpEpprFdbkCur "Mch.MCU2.BBEFC.BckdumpEpprFdbkCur";
BA_ "VssSig" SG_ 2583654752 BckcrowdEpprFdbkCur "Mch.MCU2.BBEFC.BckcrowdEpprFdbkCur";
BA_ "VssSig" SG_ 2583654752 BoomDnEpprFdbkCur "Mch.MCU2.BBEFC.BoomDnEpprFdbkCur";
BA_ "VssSig" SG_ 2583654752 BoomupEpprFdbkCur "Mch.MCU2.BBEFC.BoomupEpprFdbkCur";
BA_ "VssSig" SG_ 2583655008 SwgREpprFdbkCur "Mch.MCU2.ASEFC.SwgREpprFdbkCur";
BA_ "VssSig" SG_ 2583655008 SwgLEpprFdbkCur "Mch.MCU2.ASEFC.SwgLEpprFdbkCur";
BA_ "VssSig" SG_ 2583655008 ArmdumpEpprFdbkCur "Mch.MCU2.ASEFC.ArmdumpEpprFdbkCur";
BA_ "VssSig" SG_ 2583655008 ArmcrowdEpprFdbkCur "Mch.MCU2.ASEFC.ArmcrowdEpprFdbkCur";
BA_ "VssSig" SG_ 2583655264 ArmCnfdumpEpprFdbkCur "Mch.MCU2.CEFC.ArmCnfdumpEpprFdbkCur";
BA_ "VssSig" SG_ 2583655264 ArmCnfcrowdEpprFdbkCur "Mch.MCU2.CEFC.ArmCnfcrowdEpprFdbkCur";
BA_ "VssSig" SG_ 2583655264 BoomCnfEpprFdbkCur "Mch.MCU2.CEFC.BoomCnfEpprFdbkCur";
BA_ "VssSig" SG_ 2583655520 OpenEpprFdbkCur "Mch.MCU2.OEFC.OpenEpprFdbkCur";
BA_ "VssSig" SG_ 2583655520 CloseEpprFdbkCur "Mch.MCU2.OEFC.CloseEpprFdbkCur";
BA_ "VssSig" SG_ 2583655776 TrvlRBwdEpprFdbkCur "Mch.MCU2.TEFC.TrvlRBwdEpprFdbkCur";
BA_ "VssSig" SG_ 2583655776 TrvlRFwdEpprFdbkCur "Mch.MCU2.TEFC.TrvlRFwdEpprFdbkCur";
BA_ "VssSig" SG_ 2583655776 TrvlLBwdEpprFdbkCur "Mch.MCU2.TEFC.TrvlLBwdEpprFdbkCur";
BA_ "VssSig" SG_ 2583655776 TrvlLFwdEpprFdbkCur "Mch.MCU2.TEFC.TrvlLFwdEpprFdbkCur";
BA_ "VssSig" SG_ 2583656032 BoomCylHead2Prs "Mch.MCU2.BHRP.BoomCylHead2Prs";
BA_ "VssSig" SG_ 2583656032 BoomCylRodPrs "Mch.MCU2.BHRP.BoomCylRodPrs";
BA_ "VssSig" SG_ 2583656032 BoomCylHeadPrs "Mch.MCU2.BHRP.BoomCylHeadPrs";
BA_ "VssSig" SG_ 2583656288 BckCylRodPrs "Mch.MCU2.ABHRP.BckCylRodPrs";
BA_ "VssSig" SG_ 2583656288 BckCylHeadPrs "Mch.MCU2.ABHRP.BckCylHeadPrs";
BA_ "VssSig" SG_ 2583656288 ArmCylRodPrs "Mch.MCU2.ABHRP.ArmCylRodPrs";
BA_ "VssSig" SG_ 2583656288 ArmCylHeadPrs "Mch.MCU2.ABHRP.ArmCylHeadPrs";
BA_ "VssSig" SG_ 2583656544 BckCylRodPrsSsFmi "Mch.MCU2.CPSF.BckCylRodPrsSsFmi";
BA_ "VssSig" SG_ 2583656544 BckCylHeadPrsSsFmi "Mch.MCU2.CPSF.BckCylHeadPrsSsFmi";
BA_ "VssSig" SG_ 2583656544 BoomHead2PrsSsFmi "Mch.MCU2.CPSF.BoomHead2PrsSsFmi";
BA_ "VssSig" SG_ 2583656544 ArmCylRodPrsSsFmi "Mch.MCU2.CPSF.ArmCylRodPrsSsFmi";
BA_ "VssSig" SG_ 2583656544 ArmCylHeadPrsSsFmi "Mch.MCU2.CPSF.ArmCylHeadPrsSsFmi";
BA_ "VssSig" SG_ 2583656544 BoomCylRodPrsSsFmi "Mch.MCU2.CPSF.BoomCylRodPrsSsFmi";
BA_ "VssSig" SG_ 2583656544 BoomCylHeadPrsSsFmi "Mch.MCU2.CPSF.BoomCylHeadPrsSsFmi";
BA_ "VssSig" SG_ 2583656800 PtPltPrs "Mch.MCU2.VPP.PtPltPrs";
BA_ "VssSig" SG_ 2583656800 PaPltPrs "Mch.MCU2.VPP.PaPltPrs";
BA_ "VssSig" SG_ 2583656800 BckcrowdEpprPltPrs "Mch.MCU2.VPP.BckcrowdEpprPltPrs";
BA_ "VssSig" SG_ 2583656800 ArmcrowdEpprPltPrs "Mch.MCU2.VPP.ArmcrowdEpprPltPrs";
BA_ "VssSig" SG_ 2583656800 BoomDnEpprPltPrs "Mch.MCU2.VPP.BoomDnEpprPltPrs";
BA_ "VssSig" SG_ 2583658592 PtPltPrsSsFmi "Mch.MCU2.VPPSF.PtPltPrsSsFmi";
BA_ "VssSig" SG_ 2583658592 PaPltPrsSsFmi "Mch.MCU2.VPPSF.PaPltPrsSsFmi";
BA_ "VssSig" SG_ 2583658592 BckcrowdEpprPltPrsSsFmi "Mch.MCU2.VPPSF.BckcrowdEpprPltPrsSsFmi";
BA_ "VssSig" SG_ 2583658592 ArmcrowdEpprPltPrsSsFmi "Mch.MCU2.VPPSF.ArmcrowdEpprPltPrsSsFmi";
BA_ "VssSig" SG_ 2583658592 BoomDnEpprPltPrsSsFmi "Mch.MCU2.VPPSF.BoomDnEpprPltPrsSsFmi";
BA_ "VssSig" SG_ 2583658848 PltCutoffsolVvFmi "Mch.MCU2.PCS.PltCutoffsolVvFmi";
BA_ "VssSig" SG_ 2583658848 PltCutoffsolVvCmd "Mch.MCU2.PCS.PltCutoffsolVvCmd";
BA_ "VssSig" SG_ 2583658848 PltCutoffsolVvSwSt "Mch.MCU2.PCS.PltCutoffsolVvSwSt";
BA_ "VssSig" SG_ 2583667233 Bypass2EpprCmd "Mch.MCU.CBCC.Bypass2EpprCmd";
BA_ "VssSig" SG_ 2583667233 Bypass1EpprCmd "Mch.MCU.CBCC.Bypass1EpprCmd";
BA_ "VssSig" SG_ 2583683873 SwgStrkPltPrs "Mch.MCU.FJPP.SwgStrkPltPrs";
BA_ "VssSig" SG_ 2583683873 ArmDumpStrkPltPrs "Mch.MCU.FJPP.ArmDumpStrkPltPrs";
BA_ "VssSig" SG_ 2583683873 ArmCrowdStrkPltPrs "Mch.MCU.FJPP.ArmCrowdStrkPltPrs";
BA_ "VssSig" SG_ 2583683873 BckDumpStrkPltPrs "Mch.MCU.FJPP.BckDumpStrkPltPrs";
BA_ "VssSig" SG_ 2583683873 BckCrowdStrkPltPrs "Mch.MCU.FJPP.BckCrowdStrkPltPrs";
BA_ "VssSig" SG_ 2583683873 BoomDnStrkPltPrs "Mch.MCU.FJPP.BoomDnStrkPltPrs";
BA_ "VssSig" SG_ 2583683873 BoomUpStrkPltPrs "Mch.MCU.FJPP.BoomUpStrkPltPrs";
BA_ "VssSig" SG_ 2583684129 TrvlRStrkPltPrs "Mch.MCU.TJPP.TrvlRStrkPltPrs";
BA_ "VssSig" SG_ 2583684129 TrvlLStrkPltPrs "Mch.MCU.TJPP.TrvlLStrkPltPrs";
BA_ "VssSig" SG_ 2583684385 Pmp2ActFlow "Mch.MCU.VFD.Pmp2ActFlow";
BA_ "VssSig" SG_ 2583684385 Pmp1ActFlow "Mch.MCU.VFD.Pmp1ActFlow";
BA_ "VssSig" SG_ 2583684385 Pmp2FlowCmd "Mch.MCU.VFD.Pmp2FlowCmd";
BA_ "VssSig" SG_ 2583684385 Pmp1FlowCmd "Mch.MCU.VFD.Pmp1FlowCmd";
BA_ "VssSig" SG_ 2583684385 Pmp2ReqrFlow "Mch.MCU.VFD.Pmp2ReqrFlow";
BA_ "VssSig" SG_ 2583684385 Pmp1ReqrFlow "Mch.MCU.VFD.Pmp1ReqrFlow";
BA_ "VssSig" SG_ 2583684641 Pmp1ActPrs "Mch.MCU.VP1D.Pmp1ActPrs";
BA_ "VssSig" SG_ 2583684641 Pmp1PrsCmdviasystemPrsCtrl "Mch.MCU.VP1D.Pmp1PrsCmdviasystemPrsCtrl";
BA_ "VssSig" SG_ 2583684641 Pmp1PrsCmdviaTrqCtrl "Mch.MCU.VP1D.Pmp1PrsCmdviaTrqCtrl";
BA_ "VssSig" SG_ 2583684641 Pmp1PrsCmdviaFlowCtrl "Mch.MCU.VP1D.Pmp1PrsCmdviaFlowCtrl";
BA_ "VssSig" SG_ 2583684641 Pmp1finalPrsCmd "Mch.MCU.VP1D.Pmp1finalPrsCmd";
BA_ "VssSig" SG_ 2583684897 Pmp2ActPrs "Mch.MCU.VP2D.Pmp2ActPrs";
BA_ "VssSig" SG_ 2583684897 Pmp2PrsCmdviasystemPrsCtrl "Mch.MCU.VP2D.Pmp2PrsCmdviasystemPrsCtrl";
BA_ "VssSig" SG_ 2583684897 Pmp2PrsCmdviaTrqCtrl "Mch.MCU.VP2D.Pmp2PrsCmdviaTrqCtrl";
BA_ "VssSig" SG_ 2583684897 Pmp2PrsCmdviaFlowCtrl "Mch.MCU.VP2D.Pmp2PrsCmdviaFlowCtrl";
BA_ "VssSig" SG_ 2583684897 Pmp2finalPrsCmd "Mch.MCU.VP2D.Pmp2finalPrsCmd";
BA_ "VssSig" SG_ 2583685153 RefPowShftEnb "Mch.MCU.VTRQD.RefPowShftEnb";
BA_ "VssSig" SG_ 2583685153 PmpActTrq "Mch.MCU.VTRQD.PmpActTrq";
BA_ "VssSig" SG_ 2583685153 PmpCmdTrq "Mch.MCU.VTRQD.PmpCmdTrq";
BA_ "VssSig" SG_ 2583685153 TrqCmdLever "Mch.MCU.VTRQD.TrqCmdLever";
BA_ "VssSig" SG_ 2583685153 TrqCmdLmt "Mch.MCU.VTRQD.TrqCmdLmt";
BA_ "VssSig" SG_ 2583685153 PidCtrlResult "Mch.MCU.VTRQD.PidCtrlResult";
BA_ "VssSig" SG_ 2583685153 TrqCmdTrqCtrl "Mch.MCU.VTRQD.TrqCmdTrqCtrl";
BA_ "VssSig" SG_ 2583685153 TrqCmdPowShftCtrl "Mch.MCU.VTRQD.TrqCmdPowShftCtrl";
BA_ "VssSig" SG_ 2583685409 Byp2SplEpprFdbkCur "Mch.MCU.VSFC.Byp2SplEpprFdbkCur";
BA_ "VssSig" SG_ 2583685409 Byp1SplEpprFdbkCur "Mch.MCU.VSFC.Byp1SplEpprFdbkCur";
BA_ "VssSig" SG_ 2583685409 Boom2SplEpprFdbkCur "Mch.MCU.VSFC.Boom2SplEpprFdbkCur";
BA_ "VssSig" SG_ 2583685409 Bck2SplEpprFdbkCur "Mch.MCU.VSFC.Bck2SplEpprFdbkCur";
BA_ "VssSig" SG_ 2583685409 Arm2SplEpprFdbkCur "Mch.MCU.VSFC.Arm2SplEpprFdbkCur";
BA_ "VssSig" SG_ 2583685409 ArmLckSplEpprFdbkCur "Mch.MCU.VSFC.ArmLckSplEpprFdbkCur";
BA_ "VssSig" SG_ 2583685665 BoomCnfSplPltPrs "Mch.MCU.VSPP.BoomCnfSplPltPrs";
BA_ "VssSig" SG_ 2583685665 BckCnfSplPltPrs "Mch.MCU.VSPP.BckCnfSplPltPrs";
BA_ "VssSig" SG_ 2583685665 ArmCnfSplPltPrs "Mch.MCU.VSPP.ArmCnfSplPltPrs";
BA_ "VssSig" SG_ 2583685665 ArmLckSplPltPrs "Mch.MCU.VSPP.ArmLckSplPltPrs";
BA_ "VssSig" SG_ 2583685921 ReaRpmpEpprFdbkCur "Mch.MCU.VPAD.ReaRpmpEpprFdbkCur";
BA_ "VssSig" SG_ 2583685921 FrPmpEpprFdbkCur "Mch.MCU.VPAD.FrPmpEpprFdbkCur";
BA_ "VssSig" SG_ 2583685921 FrPmpAngVlt "Mch.MCU.VPAD.FrPmpAngVlt";
BA_ "VssSig" SG_ 2583685921 ReaRpmpAngVlt "Mch.MCU.VPAD.ReaRpmpAngVlt";
BA_ "VssSig" SG_ 2583686177 FrPmpAngVlt "Mch.MCU.VTD.FrPmpAngVlt";
BA_ "VssSig" SG_ 2583686177 OilFanEpprFdbkCur "Mch.MCU.VTD.OilFanEpprFdbkCur";
BA_ "VssSig" SG_ 2583686433 Pmp2flowandCmdDev "Mch.MCU.VVQD.Pmp2flowandCmdDev";
BA_ "VssSig" SG_ 2583686433 Pmp1flowandCmdDev "Mch.MCU.VVQD.Pmp1flowandCmdDev";
BA_ "VssSig" SG_ 2583686433 Pmp2VirQa "Mch.MCU.VVQD.Pmp2VirQa";
BA_ "VssSig" SG_ 2583686433 Pmp1VirQa "Mch.MCU.VVQD.Pmp1VirQa";
BA_ "VssSig" SG_ 2382360307 H "Mch.AGW.TRADM2.H";
BA_ "VssSig" SG_ 2382360307 G "Mch.AGW.TRADM2.G";
BA_ "VssSig" SG_ 2382360307 F "Mch.AGW.TRADM2.F";
BA_ "VssSig" SG_ 2382360307 E "Mch.AGW.TRADM2.E";
BA_ "VssSig" SG_ 2382360563 D "Mch.AGW.TRADM1.D";
BA_ "VssSig" SG_ 2382360563 C "Mch.AGW.TRADM1.C";
BA_ "VssSig" SG_ 2382360563 B "Mch.AGW.TRADM1.B";
BA_ "VssSig" SG_ 2382360563 A "Mch.AGW.TRADM1.A";
BA_ "VssSig" SG_ 2382360819 ToolAttSerialNo "Mch.AGW.TAIM1.ToolAttSerialNo";
BA_ "VssSig" SG_ 2382360819 ToolAttTypeId "Mch.AGW.TAIM1.ToolAttTypeId";
BA_ "VssSig" SG_ 2382360819 ToolAttSaeId "Mch.AGW.TAIM1.ToolAttSaeId";
BA_ "VssSig" SG_ 2382361075 TRAttSerialNo "Mch.AGW.TRAIM1.TRAttSerialNo";
BA_ "VssSig" SG_ 2382361075 TRAttTypeId "Mch.AGW.TRAIM1.TRAttTypeId";
BA_ "VssSig" SG_ 2382361075 TRAttSaeId "Mch.AGW.TRAIM1.TRAttSaeId";
BA_ "VssSig" SG_ 2382361331 J1939Bitrate "Mch.AGW.TRSIM1.J1939Bitrate";
BA_ "VssSig" SG_ 2382361331 TransRepetitionRate "Mch.AGW.TRSIM1.TransRepetitionRate";
BA_ "VssSig" SG_ 2382361331 AbsEncTiltSsSt "Mch.AGW.TRSIM1.AbsEncTiltSsSt";
BA_ "VssSig" SG_ 2382361331 ImuTiltSsSt "Mch.AGW.TRSIM1.ImuTiltSsSt";
BA_ "VssSig" SG_ 2382361331 RttSsSt "Mch.AGW.TRSIM1.RttSsSt";
BA_ "VssSig" SG_ 2382361331 TiltSsDataDlyMd "Mch.AGW.TRSIM1.TiltSsDataDlyMd";
BA_ "VssSig" SG_ 2382361331 SsFaultCode "Mch.AGW.TRSIM1.SsFaultCode";
BA_ "VssSig" SG_ 2382361587 RttSsdataDly "Mch.AGW.TRRSDM1.RttSsdataDly";
BA_ "VssSig" SG_ 2382361587 RttAngaroundZAxis "Mch.AGW.TRRSDM1.RttAngaroundZAxis";
BA_ "VssSig" SG_ 2382361843 TiltSsdataDly "Mch.AGW.TRTSDM1.TiltSsdataDly";
BA_ "VssSig" SG_ 2382361843 TiltAbsEncAng "Mch.AGW.TRTSDM1.TiltAbsEncAng";
BA_ "VssSig" SG_ 2382361843 TiltImuAngaroundYAxis "Mch.AGW.TRTSDM1.TiltImuAngaroundYAxis";
BA_ "VssSig" SG_ 2382361843 TiltImuAngaroundXAxis "Mch.AGW.TRTSDM1.TiltImuAngaroundXAxis";
BA_ "VssSig" SG_ 2382362867 TRToolLckSt "Mch.AGW.AFIM1.TRToolLckSt";
BA_ "VssSig" SG_ 2382362867 OnOffFunc8St "Mch.AGW.AFIM1.OnOffFunc8St";
BA_ "VssSig" SG_ 2382362867 OnOffFunc7St "Mch.AGW.AFIM1.OnOffFunc7St";
BA_ "VssSig" SG_ 2382362867 OnOffFunc6St "Mch.AGW.AFIM1.OnOffFunc6St";
BA_ "VssSig" SG_ 2382362867 OnOffFunc5St "Mch.AGW.AFIM1.OnOffFunc5St";
BA_ "VssSig" SG_ 2382362867 OnOffFunc4St "Mch.AGW.AFIM1.OnOffFunc4St";
BA_ "VssSig" SG_ 2382362867 OnOffFunc3St "Mch.AGW.AFIM1.OnOffFunc3St";
BA_ "VssSig" SG_ 2382362867 OnOffFunc2St "Mch.AGW.AFIM1.OnOffFunc2St";
BA_ "VssSig" SG_ 2382362867 OnOffFunc1St "Mch.AGW.AFIM1.OnOffFunc1St";
BA_ "VssSig" SG_ 2382362867 PropFunc6St "Mch.AGW.AFIM1.PropFunc6St";
BA_ "VssSig" SG_ 2382362867 PropFunc5St "Mch.AGW.AFIM1.PropFunc5St";
BA_ "VssSig" SG_ 2382362867 PropFunc4St "Mch.AGW.AFIM1.PropFunc4St";
BA_ "VssSig" SG_ 2382362867 PropFunc3St "Mch.AGW.AFIM1.PropFunc3St";
BA_ "VssSig" SG_ 2382362867 PropFunc2St "Mch.AGW.AFIM1.PropFunc2St";
BA_ "VssSig" SG_ 2382362867 PropFunc1St "Mch.AGW.AFIM1.PropFunc1St";
BA_ "VssSig" SG_ 2382363123 AttLckVvVal "Mch.AGW.ALCM1.AttLckVvVal";
BA_ "VssSig" SG_ 2382363123 AttLckVvPosiSt "Mch.AGW.ALCM1.AttLckVvPosiSt";
BA_ "VssSig" SG_ 2382363123 AttLckVvNegaSt "Mch.AGW.ALCM1.AttLckVvNegaSt";
BA_ "VssSig" SG_ 2382363379 AuxHyh3Val "Mch.AGW.AHCM1.AuxHyh3Val";
BA_ "VssSig" SG_ 2382363379 AuxHyh3PosiSt "Mch.AGW.AHCM1.AuxHyh3PosiSt";
BA_ "VssSig" SG_ 2382363379 AuxHyh3NegaSt "Mch.AGW.AHCM1.AuxHyh3NegaSt";
BA_ "VssSig" SG_ 2382363379 AuxHyh3NtrlSt "Mch.AGW.AHCM1.AuxHyh3NtrlSt";
BA_ "VssSig" SG_ 2382363379 AuxHyh2Val "Mch.AGW.AHCM1.AuxHyh2Val";
BA_ "VssSig" SG_ 2382363379 AuxHyh2PosiSt "Mch.AGW.AHCM1.AuxHyh2PosiSt";
BA_ "VssSig" SG_ 2382363379 AuxHyh2NegaSt "Mch.AGW.AHCM1.AuxHyh2NegaSt";
BA_ "VssSig" SG_ 2382363379 AuxHyh2NtrlSt "Mch.AGW.AHCM1.AuxHyh2NtrlSt";
BA_ "VssSig" SG_ 2382363379 AuxHyh1Val "Mch.AGW.AHCM1.AuxHyh1Val";
BA_ "VssSig" SG_ 2382363379 AuxHyh1PosiSt "Mch.AGW.AHCM1.AuxHyh1PosiSt";
BA_ "VssSig" SG_ 2382363379 AuxHyh1NegaSt "Mch.AGW.AHCM1.AuxHyh1NegaSt";
BA_ "VssSig" SG_ 2382363379 AuxHyh1NtrlSt "Mch.AGW.AHCM1.AuxHyh1NtrlSt";
BA_ "VssSig" SG_ 2382363681 AuxHyh3Val "Mch.MCU.EIM1.AuxHyh3Val";
BA_ "VssSig" SG_ 2382363681 AuxHyh3PosiSt "Mch.MCU.EIM1.AuxHyh3PosiSt";
BA_ "VssSig" SG_ 2382363681 AuxHyh3NegaSt "Mch.MCU.EIM1.AuxHyh3NegaSt";
BA_ "VssSig" SG_ 2382363681 AuxHyh3NtrlSt "Mch.MCU.EIM1.AuxHyh3NtrlSt";
BA_ "VssSig" SG_ 2382363681 AuxHyh2Val "Mch.MCU.EIM1.AuxHyh2Val";
BA_ "VssSig" SG_ 2382363681 AuxHyh2PosiSt "Mch.MCU.EIM1.AuxHyh2PosiSt";
BA_ "VssSig" SG_ 2382363681 AuxHyh2NegaSt "Mch.MCU.EIM1.AuxHyh2NegaSt";
BA_ "VssSig" SG_ 2382363681 AuxHyh2NtrlSt "Mch.MCU.EIM1.AuxHyh2NtrlSt";
BA_ "VssSig" SG_ 2382363681 AuxHyh1Val "Mch.MCU.EIM1.AuxHyh1Val";
BA_ "VssSig" SG_ 2382363681 AuxHyh1PosiSt "Mch.MCU.EIM1.AuxHyh1PosiSt";
BA_ "VssSig" SG_ 2382363681 AuxHyh1NegaSt "Mch.MCU.EIM1.AuxHyh1NegaSt";
BA_ "VssSig" SG_ 2382363681 AuxHyh1NtrlSt "Mch.MCU.EIM1.AuxHyh1NtrlSt";
BA_ "VssSig" SG_ 2382364193 OnOffFunc5St "Mch.MCU.ACM2.OnOffFunc5St";
BA_ "VssSig" SG_ 2382364193 OnOffFunc6St "Mch.MCU.ACM2.OnOffFunc6St";
BA_ "VssSig" SG_ 2382364193 OnOffFunc7St "Mch.MCU.ACM2.OnOffFunc7St";
BA_ "VssSig" SG_ 2382364193 OnOffFunc8St "Mch.MCU.ACM2.OnOffFunc8St";
BA_ "VssSig" SG_ 2382364193 PropFunc6Val "Mch.MCU.ACM2.PropFunc6Val";
BA_ "VssSig" SG_ 2382364193 PropFunc6PosiSt "Mch.MCU.ACM2.PropFunc6PosiSt";
BA_ "VssSig" SG_ 2382364193 PropFunc6NegaSt "Mch.MCU.ACM2.PropFunc6NegaSt";
BA_ "VssSig" SG_ 2382364193 PropFunc6NtrlSt "Mch.MCU.ACM2.PropFunc6NtrlSt";
BA_ "VssSig" SG_ 2382364193 PropFunc5Val "Mch.MCU.ACM2.PropFunc5Val";
BA_ "VssSig" SG_ 2382364193 PropFunc5PosiSt "Mch.MCU.ACM2.PropFunc5PosiSt";
BA_ "VssSig" SG_ 2382364193 PropFunc5NegaSt "Mch.MCU.ACM2.PropFunc5NegaSt";
BA_ "VssSig" SG_ 2382364193 PropFunc5NtrlSt "Mch.MCU.ACM2.PropFunc5NtrlSt";
BA_ "VssSig" SG_ 2382364193 PropFunc4Val "Mch.MCU.ACM2.PropFunc4Val";
BA_ "VssSig" SG_ 2382364193 PropFunc4PosiSt "Mch.MCU.ACM2.PropFunc4PosiSt";
BA_ "VssSig" SG_ 2382364193 PropFunc4NegaSt "Mch.MCU.ACM2.PropFunc4NegaSt";
BA_ "VssSig" SG_ 2382364193 PropFunc4NtrlSt "Mch.MCU.ACM2.PropFunc4NtrlSt";
BA_ "VssSig" SG_ 2382364449 OnOffFunc1St "Mch.MCU.ACM1.OnOffFunc1St";
BA_ "VssSig" SG_ 2382364449 OnOffFunc2St "Mch.MCU.ACM1.OnOffFunc2St";
BA_ "VssSig" SG_ 2382364449 OnOffFunc3St "Mch.MCU.ACM1.OnOffFunc3St";
BA_ "VssSig" SG_ 2382364449 OnOffFunc4St "Mch.MCU.ACM1.OnOffFunc4St";
BA_ "VssSig" SG_ 2382364449 PropFunc3Value "Mch.MCU.ACM1.PropFunc3Value";
BA_ "VssSig" SG_ 2382364449 PropFunc3PosiSt "Mch.MCU.ACM1.PropFunc3PosiSt";
BA_ "VssSig" SG_ 2382364449 PropFunc3NegaSt "Mch.MCU.ACM1.PropFunc3NegaSt";
BA_ "VssSig" SG_ 2382364449 PropFunc3NtrlSt "Mch.MCU.ACM1.PropFunc3NtrlSt";
BA_ "VssSig" SG_ 2382364449 PropFunc2Value "Mch.MCU.ACM1.PropFunc2Value";
BA_ "VssSig" SG_ 2382364449 PropFunc2PosiSt "Mch.MCU.ACM1.PropFunc2PosiSt";
BA_ "VssSig" SG_ 2382364449 PropFunc2NegaSt "Mch.MCU.ACM1.PropFunc2NegaSt";
BA_ "VssSig" SG_ 2382364449 PropFunc2NtrlSt "Mch.MCU.ACM1.PropFunc2NtrlSt";
BA_ "VssSig" SG_ 2382364449 PropFunc1Value "Mch.MCU.ACM1.PropFunc1Value";
BA_ "VssSig" SG_ 2382364449 PropFunc1PosiSt "Mch.MCU.ACM1.PropFunc1PosiSt";
BA_ "VssSig" SG_ 2382364449 PropFunc1NegaSt "Mch.MCU.ACM1.PropFunc1NegaSt";
BA_ "VssSig" SG_ 2382364449 PropFunc1NtrlSt "Mch.MCU.ACM1.PropFunc1NtrlSt";
BA_ "VssSig" SG_ 2566842442 Z "Mch.TGU.VDS.Z";
BA_ "VssSig" SG_ 2566842442 Spd "Mch.TGU.VDS.Spd";
BA_ "VssSig" SG_ 2566845258 Y "Mch.TGU.VP1.Y";
BA_ "VssSig" SG_ 2566845258 X "Mch.TGU.VP1.X";
BA_ "VssSig" SG_ 2583642954 Dkey "Mch.TGU.DKLLG.Dkey";
BA_ "VssSig" SG_ 2583642954 SelType "Mch.TGU.DKLLG.SelType";
BA_ "VssSig" SG_ 2583643466 DkeyListInfo "Mch.TGU.DKTL.DkeyListInfo";
BA_ "VssSig" SG_ 2583642186 TokenRevCnt "Mch.TGU.MPS.TokenRevCnt";
BA_ "VssSig" SG_ 2583642186 MpSt "Mch.TGU.MPS.MpSt";
BA_ "VssSig" SG_ 2583642442 TguId "Mch.TGU.MPI.TguId";
BA_ "VssSig" SG_ 2583642442 Name "Mch.TGU.MPI.Name";
BA_ "VssSig" SG_ 2583642442 Mcode "Mch.TGU.MPI.Mcode";
BA_ "VssSig" SG_ 2583642442 Vin "Mch.TGU.MPI.Vin";
BA_ "VssSig" SG_ 2583642442 Oem "Mch.TGU.MPI.Oem";
BA_ "VssSig" SG_ 2583642442 Mch "Mch.TGU.MPI.Mch";
BA_ "VssSig" SG_ 2583662698 WarnPopPhmSwgMot "Mch.PHM.PHMWG.WarnPopPhmSwgMot";
BA_ "VssSig" SG_ 2583662698 WarnPopPhm2ndSwgRedGr "Mch.PHM.PHMWG.WarnPopPhm2ndSwgRedGr";
BA_ "VssSig" SG_ 2583662698 WarnPopPhm1stSwgRedGr "Mch.PHM.PHMWG.WarnPopPhm1stSwgRedGr";
BA_ "VssSig" SG_ 2583662698 WarnPopMainPmp "Mch.PHM.PHMWG.WarnPopMainPmp";
BA_ "VssSig" SG_ 2583662698 WarnPopEgOilQual "Mch.PHM.PHMWG.WarnPopEgOilQual";
BA_ "VssSig" SG_ 2583662698 WarnPopHyhOilQual "Mch.PHM.PHMWG.WarnPopHyhOilQual";
BA_ "VssSig" SG_ 2583666538 LwThKnmtVcstyofHyhOil "Mch.PHM.THO.LwThKnmtVcstyofHyhOil";
BA_ "VssSig" SG_ 2583666538 UpThKnmtVcstyofHyhOil "Mch.PHM.THO.UpThKnmtVcstyofHyhOil";
BA_ "VssSig" SG_ 2583666538 LwThDielecCstofHyhOil "Mch.PHM.THO.LwThDielecCstofHyhOil";
BA_ "VssSig" SG_ 2583666538 UpThDielecCstofHyhOil "Mch.PHM.THO.UpThDielecCstofHyhOil";
BA_ "VssSig" SG_ 2583666794 LwThKnmtVcstyofEgOil "Mch.PHM.TEO.LwThKnmtVcstyofEgOil";
BA_ "VssSig" SG_ 2583666794 UpThKnmtVcstyofEgOil "Mch.PHM.TEO.UpThKnmtVcstyofEgOil";
BA_ "VssSig" SG_ 2583666794 LwThDielecCstofEgOil "Mch.PHM.TEO.LwThDielecCstofEgOil";
BA_ "VssSig" SG_ 2583666794 UpThDielecCstofEgOil "Mch.PHM.TEO.UpThDielecCstofEgOil";
BA_ "VssSig" SG_ 2583667050 KnmtVcstyofEgOil "Mch.PHM.KVO.KnmtVcstyofEgOil";
BA_ "VssSig" SG_ 2583667050 KnmtVcstyofHyhOil "Mch.PHM.KVO.KnmtVcstyofHyhOil";
BA_ "VssSig" SG_ 2583662881 AccPdlVlt "Mch.MCU.ECDP1.AccPdlVlt";
BA_ "VssSig" SG_ 2583662881 RJoyThmbVlt "Mch.MCU.ECDP1.RJoyThmbVlt";
BA_ "VssSig" SG_ 2583662881 LJoyThmbVlt "Mch.MCU.ECDP1.LJoyThmbVlt";
BA_ "VssSig" SG_ 2583663137 RrPmpPrs "Mch.MCU.ECDP2.RrPmpPrs";
BA_ "VssSig" SG_ 2583663137 FrPmpPrs "Mch.MCU.ECDP2.FrPmpPrs";
BA_ "VssSig" SG_ 2583663137 AltVlt "Mch.MCU.ECDP2.AltVlt";
BA_ "VssSig" SG_ 2583663137 BatVlt "Mch.MCU.ECDP2.BatVlt";
BA_ "VssSig" SG_ 2583663393 StickStrType "Mch.MCU.ECDP3.StickStrType";
BA_ "VssSig" SG_ 2583663393 StickStr "Mch.MCU.ECDP3.StickStr";
BA_ "VssSig" SG_ 2583663393 JoyPtnChange "Mch.MCU.ECDP3.JoyPtnChange";
BA_ "VssSig" SG_ 2583663393 Pmp2ActFlow "Mch.MCU.ECDP3.Pmp2ActFlow";
BA_ "VssSig" SG_ 2583663393 Pmp1ActFlow "Mch.MCU.ECDP3.Pmp1ActFlow";
BA_ "VssSig" SG_ 2633656127 Oilresistivity "Mch.HDOQS.OQM2.Oilresistivity";
BA_ "VssSig" SG_ 2633656238 Oilresistivity "Mch.EGOQS.OQM2.Oilresistivity";
BA_ "VssSig" SG_ 2566894666 CertKey7 "Mch.SMK.CNRC.CertKey7";
BA_ "VssSig" SG_ 2566894666 CertKey8 "Mch.SMK.CNRC.CertKey8";
BA_ "VssSig" SG_ 2566894666 CertKey5 "Mch.SMK.CNRC.CertKey5";
BA_ "VssSig" SG_ 2566894666 CertKey6 "Mch.SMK.CNRC.CertKey6";
BA_ "VssSig" SG_ 2566894666 CertKey3 "Mch.SMK.CNRC.CertKey3";
BA_ "VssSig" SG_ 2566894666 CertKey4 "Mch.SMK.CNRC.CertKey4";
BA_ "VssSig" SG_ 2566894666 CertKey1 "Mch.SMK.CNRC.CertKey1";
BA_ "VssSig" SG_ 2566894666 CertKey2 "Mch.SMK.CNRC.CertKey2";
BA_ "VssSig" SG_ 2566868001 SocBatLevel "Mch.MCU.EGDG.SocBatLevel";
BA_ "VssSig" SG_ 2566868001 SwgIvtTmp "Mch.MCU.EGDG.SwgIvtTmp";
BA_ "VssSig" SG_ 2566868001 TrvlIvtTmp "Mch.MCU.EGDG.TrvlIvtTmp";
BA_ "VssSig" SG_ 2566868001 PmpIvtTmp "Mch.MCU.EGDG.PmpIvtTmp";
BA_ "VssSig" SG_ 2566868001 SwgMotTmp "Mch.MCU.EGDG.SwgMotTmp";
BA_ "VssSig" SG_ 2566868001 TrvlMotTmp "Mch.MCU.EGDG.TrvlMotTmp";
BA_ "VssSig" SG_ 2566868001 PmpMotTmp "Mch.MCU.EGDG.PmpMotTmp";
BA_ "VssSig" SG_ 2566868001 SocBatTmp "Mch.MCU.EGDG.SocBatTmp";
BA_ "VssSig" SG_ 2634015777 ReqCd "Mch.MCU.TCUMPRQ.ReqCd";
BA_ "VssSig" SG_ 2634015777 MaxGrLmt "Mch.MCU.TCUMPRQ.MaxGrLmt";
BA_ "VssSig" SG_ 2634015777 EmsCtrl "Mch.MCU.TCUMPRQ.EmsCtrl";
BA_ "VssSig" SG_ 2634015777 MchClass "Mch.MCU.TCUMPRQ.MchClass";
BA_ "VssSig" SG_ 2634015777 MchGenr "Mch.MCU.TCUMPRQ.MchGenr";
BA_ "VssSig" SG_ 2634016259 ResultCd "Mch.MCU.TCUMPRS.ResultCd";
BA_ "VssSig" SG_ 2634016259 AxleOpt "Mch.MCU.TCUMPRS.AxleOpt";
BA_ "VssSig" SG_ 2634016259 MaxGrLmt "Mch.MCU.TCUMPRS.MaxGrLmt";
BA_ "VssSig" SG_ 2634016259 EmsCtrl "Mch.MCU.TCUMPRS.EmsCtrl";
BA_ "VssSig" SG_ 2634016259 MchClass "Mch.MCU.TCUMPRS.MchClass";
BA_ "VssSig" SG_ 2634016259 MchGenr "Mch.MCU.TCUMPRS.MchGenr";
BA_ "VssSig" SG_ 2566912033 ImuAxisSetTiltBck05 "Mch.MCU.MWHG5.ImuAxisSetTiltBck05";
BA_ "VssSig" SG_ 2566912033 ImuAxisSetTiltBck04 "Mch.MCU.MWHG5.ImuAxisSetTiltBck04";
BA_ "VssSig" SG_ 2566912033 ImuAxisSetTiltBck03 "Mch.MCU.MWHG5.ImuAxisSetTiltBck03";
BA_ "VssSig" SG_ 2566912033 ImuAxisSetTiltBck02 "Mch.MCU.MWHG5.ImuAxisSetTiltBck02";
BA_ "VssSig" SG_ 2566912033 ImuAxisSetTiltBck01 "Mch.MCU.MWHG5.ImuAxisSetTiltBck01";
BA_ "VssSig" SG_ 2566912033 TiltBck05DmsnNq3 "Mch.MCU.MWHG5.TiltBck05DmsnNq3";
BA_ "VssSig" SG_ 2566912033 TiltBck05DmsnNq2 "Mch.MCU.MWHG5.TiltBck05DmsnNq2";
BA_ "VssSig" SG_ 2566912033 TiltBck05DmsnNq1 "Mch.MCU.MWHG5.TiltBck05DmsnNq1";
BA_ "VssSig" SG_ 2566912033 TiltBck05DmsnWd "Mch.MCU.MWHG5.TiltBck05DmsnWd";
BA_ "VssSig" SG_ 2566912033 TiltBck05DmsnUq3 "Mch.MCU.MWHG5.TiltBck05DmsnUq3";
BA_ "VssSig" SG_ 2566912033 TiltBck05DmsnUq2 "Mch.MCU.MWHG5.TiltBck05DmsnUq2";
BA_ "VssSig" SG_ 2566912033 TiltBck05DmsnUq1 "Mch.MCU.MWHG5.TiltBck05DmsnUq1";
BA_ "VssSig" SG_ 2566912033 TiltBck05DmsnUm "Mch.MCU.MWHG5.TiltBck05DmsnUm";
BA_ "VssSig" SG_ 2566912033 TiltBck05DmsnDt "Mch.MCU.MWHG5.TiltBck05DmsnDt";
BA_ "VssSig" SG_ 2566912033 TiltBck05DmsnDg "Mch.MCU.MWHG5.TiltBck05DmsnDg";
BA_ "VssSig" SG_ 2566912033 TiltBck05DmsnGdt "Mch.MCU.MWHG5.TiltBck05DmsnGdt";
BA_ "VssSig" SG_ 2566912033 ImuSsOffsetTiltBck05Roll "Mch.MCU.MWHG5.ImuSsOffsetTiltBck05Roll";
BA_ "VssSig" SG_ 2566912033 ImuSsOffsetTiltBck05Pch "Mch.MCU.MWHG5.ImuSsOffsetTiltBck05Pch";
BA_ "VssSig" SG_ 2566912033 TiltBck05DmsnTuN "Mch.MCU.MWHG5.TiltBck05DmsnTuN";
BA_ "VssSig" SG_ 2566912033 TiltBck05DmsnTthMn "Mch.MCU.MWHG5.TiltBck05DmsnTthMn";
BA_ "VssSig" SG_ 2566912033 TiltBck05DmsnUn "Mch.MCU.MWHG5.TiltBck05DmsnUn";
BA_ "VssSig" SG_ 2566912033 TiltBck05DmsnTn "Mch.MCU.MWHG5.TiltBck05DmsnTn";
BA_ "VssSig" SG_ 2566912033 TiltBck05DmsnTu "Mch.MCU.MWHG5.TiltBck05DmsnTu";
BA_ "VssSig" SG_ 2566912033 TiltBck04DmsnNq3 "Mch.MCU.MWHG5.TiltBck04DmsnNq3";
BA_ "VssSig" SG_ 2566912033 TiltBck04DmsnNq2 "Mch.MCU.MWHG5.TiltBck04DmsnNq2";
BA_ "VssSig" SG_ 2566912033 TiltBck04DmsnNq1 "Mch.MCU.MWHG5.TiltBck04DmsnNq1";
BA_ "VssSig" SG_ 2566912033 TiltBck04DmsnWd "Mch.MCU.MWHG5.TiltBck04DmsnWd";
BA_ "VssSig" SG_ 2566912033 TiltBck04DmsnUq3 "Mch.MCU.MWHG5.TiltBck04DmsnUq3";
BA_ "VssSig" SG_ 2566912033 TiltBck04DmsnUq2 "Mch.MCU.MWHG5.TiltBck04DmsnUq2";
BA_ "VssSig" SG_ 2566912033 TiltBck04DmsnUq1 "Mch.MCU.MWHG5.TiltBck04DmsnUq1";
BA_ "VssSig" SG_ 2566912033 TiltBck04DmsnUm "Mch.MCU.MWHG5.TiltBck04DmsnUm";
BA_ "VssSig" SG_ 2566912033 TiltBck04DmsnDt "Mch.MCU.MWHG5.TiltBck04DmsnDt";
BA_ "VssSig" SG_ 2566912033 TiltBck04DmsnDg "Mch.MCU.MWHG5.TiltBck04DmsnDg";
BA_ "VssSig" SG_ 2566912033 TiltBck04DmsnGdt "Mch.MCU.MWHG5.TiltBck04DmsnGdt";
BA_ "VssSig" SG_ 2566912033 ImuSsOffsetTiltBck04Roll "Mch.MCU.MWHG5.ImuSsOffsetTiltBck04Roll";
BA_ "VssSig" SG_ 2566912033 ImuSsOffsetTiltBck04Pch "Mch.MCU.MWHG5.ImuSsOffsetTiltBck04Pch";
BA_ "VssSig" SG_ 2566912033 TiltBck04DmsnTuN "Mch.MCU.MWHG5.TiltBck04DmsnTuN";
BA_ "VssSig" SG_ 2566912033 TiltBck04DmsnTthMn "Mch.MCU.MWHG5.TiltBck04DmsnTthMn";
BA_ "VssSig" SG_ 2566912033 TiltBck04DmsnUn "Mch.MCU.MWHG5.TiltBck04DmsnUn";
BA_ "VssSig" SG_ 2566912033 TiltBck04DmsnTn "Mch.MCU.MWHG5.TiltBck04DmsnTn";
BA_ "VssSig" SG_ 2566912033 TiltBck04DmsnTu "Mch.MCU.MWHG5.TiltBck04DmsnTu";
BA_ "VssSig" SG_ 2566912033 TiltBck03DmsnNq3 "Mch.MCU.MWHG5.TiltBck03DmsnNq3";
BA_ "VssSig" SG_ 2566912033 TiltBck03DmsnNq2 "Mch.MCU.MWHG5.TiltBck03DmsnNq2";
BA_ "VssSig" SG_ 2566912033 TiltBck03DmsnNq1 "Mch.MCU.MWHG5.TiltBck03DmsnNq1";
BA_ "VssSig" SG_ 2566912033 TiltBck03DmsnWd "Mch.MCU.MWHG5.TiltBck03DmsnWd";
BA_ "VssSig" SG_ 2566912033 TiltBck03DmsnUq3 "Mch.MCU.MWHG5.TiltBck03DmsnUq3";
BA_ "VssSig" SG_ 2566912033 TiltBck03DmsnUq2 "Mch.MCU.MWHG5.TiltBck03DmsnUq2";
BA_ "VssSig" SG_ 2566912033 TiltBck03DmsnUq1 "Mch.MCU.MWHG5.TiltBck03DmsnUq1";
BA_ "VssSig" SG_ 2566912033 TiltBck03DmsnUm "Mch.MCU.MWHG5.TiltBck03DmsnUm";
BA_ "VssSig" SG_ 2566912033 TiltBck03DmsnDt "Mch.MCU.MWHG5.TiltBck03DmsnDt";
BA_ "VssSig" SG_ 2566912033 TiltBck03DmsnDg "Mch.MCU.MWHG5.TiltBck03DmsnDg";
BA_ "VssSig" SG_ 2566912033 TiltBck03DmsnGdt "Mch.MCU.MWHG5.TiltBck03DmsnGdt";
BA_ "VssSig" SG_ 2566912033 ImuSsOffsetTiltBck03Roll "Mch.MCU.MWHG5.ImuSsOffsetTiltBck03Roll";
BA_ "VssSig" SG_ 2566912033 ImuSsOffsetTiltBck03Pch "Mch.MCU.MWHG5.ImuSsOffsetTiltBck03Pch";
BA_ "VssSig" SG_ 2566912033 TiltBck03DmsnTuN "Mch.MCU.MWHG5.TiltBck03DmsnTuN";
BA_ "VssSig" SG_ 2566912033 TiltBck03DmsnTthMn "Mch.MCU.MWHG5.TiltBck03DmsnTthMn";
BA_ "VssSig" SG_ 2566912033 TiltBck03DmsnUn "Mch.MCU.MWHG5.TiltBck03DmsnUn";
BA_ "VssSig" SG_ 2566912033 TiltBck03DmsnTn "Mch.MCU.MWHG5.TiltBck03DmsnTn";
BA_ "VssSig" SG_ 2566912033 TiltBck03DmsnTu "Mch.MCU.MWHG5.TiltBck03DmsnTu";
BA_ "VssSig" SG_ 2566912033 TiltBck02DmsnNq3 "Mch.MCU.MWHG5.TiltBck02DmsnNq3";
BA_ "VssSig" SG_ 2566912033 TiltBck02DmsnNq2 "Mch.MCU.MWHG5.TiltBck02DmsnNq2";
BA_ "VssSig" SG_ 2566912033 TiltBck02DmsnNq1 "Mch.MCU.MWHG5.TiltBck02DmsnNq1";
BA_ "VssSig" SG_ 2566912033 TiltBck02DmsnWd "Mch.MCU.MWHG5.TiltBck02DmsnWd";
BA_ "VssSig" SG_ 2566912033 TiltBck02DmsnUq3 "Mch.MCU.MWHG5.TiltBck02DmsnUq3";
BA_ "VssSig" SG_ 2566912033 TiltBck02DmsnUq2 "Mch.MCU.MWHG5.TiltBck02DmsnUq2";
BA_ "VssSig" SG_ 2566912033 TiltBck02DmsnUq1 "Mch.MCU.MWHG5.TiltBck02DmsnUq1";
BA_ "VssSig" SG_ 2566912033 TiltBck02DmsnUm "Mch.MCU.MWHG5.TiltBck02DmsnUm";
BA_ "VssSig" SG_ 2566912033 TiltBck02DmsnDt "Mch.MCU.MWHG5.TiltBck02DmsnDt";
BA_ "VssSig" SG_ 2566912033 TiltBck02DmsnDg "Mch.MCU.MWHG5.TiltBck02DmsnDg";
BA_ "VssSig" SG_ 2566912033 TiltBck02DmsnGdt "Mch.MCU.MWHG5.TiltBck02DmsnGdt";
BA_ "VssSig" SG_ 2566912033 ImuSsOffsetTiltBck02Roll "Mch.MCU.MWHG5.ImuSsOffsetTiltBck02Roll";
BA_ "VssSig" SG_ 2566912033 ImuSsOffsetTiltBck02Pch "Mch.MCU.MWHG5.ImuSsOffsetTiltBck02Pch";
BA_ "VssSig" SG_ 2566912033 TiltBck02DmsnTuN "Mch.MCU.MWHG5.TiltBck02DmsnTuN";
BA_ "VssSig" SG_ 2566912033 TiltBck02DmsnTthMn "Mch.MCU.MWHG5.TiltBck02DmsnTthMn";
BA_ "VssSig" SG_ 2566912033 TiltBck02DmsnUn "Mch.MCU.MWHG5.TiltBck02DmsnUn";
BA_ "VssSig" SG_ 2566912033 TiltBck02DmsnTn "Mch.MCU.MWHG5.TiltBck02DmsnTn";
BA_ "VssSig" SG_ 2566912033 TiltBck02DmsnTu "Mch.MCU.MWHG5.TiltBck02DmsnTu";
BA_ "VssSig" SG_ 2566912033 TiltBck01DmsnNq3 "Mch.MCU.MWHG5.TiltBck01DmsnNq3";
BA_ "VssSig" SG_ 2566912033 TiltBck01DmsnNq2 "Mch.MCU.MWHG5.TiltBck01DmsnNq2";
BA_ "VssSig" SG_ 2566912033 TiltBck01DmsnNq1 "Mch.MCU.MWHG5.TiltBck01DmsnNq1";
BA_ "VssSig" SG_ 2566912033 TiltBck01DmsnWd "Mch.MCU.MWHG5.TiltBck01DmsnWd";
BA_ "VssSig" SG_ 2566912033 TiltBck01DmsnUq3 "Mch.MCU.MWHG5.TiltBck01DmsnUq3";
BA_ "VssSig" SG_ 2566912033 TiltBck01DmsnUq2 "Mch.MCU.MWHG5.TiltBck01DmsnUq2";
BA_ "VssSig" SG_ 2566912033 TiltBck01DmsnUq1 "Mch.MCU.MWHG5.TiltBck01DmsnUq1";
BA_ "VssSig" SG_ 2566912033 TiltBck01DmsnUm "Mch.MCU.MWHG5.TiltBck01DmsnUm";
BA_ "VssSig" SG_ 2566912033 TiltBck01DmsnDt "Mch.MCU.MWHG5.TiltBck01DmsnDt";
BA_ "VssSig" SG_ 2566912033 TiltBck01DmsnDg "Mch.MCU.MWHG5.TiltBck01DmsnDg";
BA_ "VssSig" SG_ 2566912033 TiltBck01DmsnGdt "Mch.MCU.MWHG5.TiltBck01DmsnGdt";
BA_ "VssSig" SG_ 2566912033 ImuSsOffsetTiltBck01Roll "Mch.MCU.MWHG5.ImuSsOffsetTiltBck01Roll";
BA_ "VssSig" SG_ 2566912033 ImuSsOffsetTiltBck01Pch "Mch.MCU.MWHG5.ImuSsOffsetTiltBck01Pch";
BA_ "VssSig" SG_ 2566912033 TiltBck01DmsnTun "Mch.MCU.MWHG5.TiltBck01DmsnTun";
BA_ "VssSig" SG_ 2566912033 TiltBck01DmsnTthMn "Mch.MCU.MWHG5.TiltBck01DmsnTthMn";
BA_ "VssSig" SG_ 2566912033 TiltBck01DmsnUn "Mch.MCU.MWHG5.TiltBck01DmsnUn";
BA_ "VssSig" SG_ 2566912033 TiltBck01DmsnTn "Mch.MCU.MWHG5.TiltBck01DmsnTn";
BA_ "VssSig" SG_ 2566912033 TiltBck01DmsnTu "Mch.MCU.MWHG5.TiltBck01DmsnTu";
VAL_ 2566907937 RhJoyBtnAux12AddSetConfig 0 "INACTIVE" 1 "ACTIVE" 2 "RESERVED" 3 "NOT_AVAILABLE" ;
VAL_ 2566907937 HeavyAttConfig 0 "INACTIVE" 1 "ACTIVE" 2 "RESERVED" 3 "NOT_AVAILABLE" ;
VAL_ 2566907937 IdleSpdSetConfig 0 "INACTIVE" 1 "ACTIVE" 2 "RESERVED" 3 "NOT_AVAILABLE" ;
VAL_ 2566907937 SdkParallelLiftConfig 0 "INACTIVE" 1 "ACTIVE" 2 "RESERVED" 3 "NOT_AVAILABLE" ;
VAL_ 2566907937 RsvforVdk10W 0 "INACTIVE" 1 "ACTIVE" 2 "RESERVED" 3 "NOT_AVAILABLE" ;
VAL_ 2566907937 BrkOprgTmLmConfigforVccC4 0 "INACTIVE" 1 "ACTIVE" 2 "RESERVED" 3 "NOT_AVAILABLE" ;
VAL_ 2566907937 ElectStrThmbwhlConfig 0 "INACTIVE" 1 "ACTIVE" 2 "RESERVED" 3 "NOT_AVAILABLE" ;
VAL_ 2566907937 EmgStrConfig 0 "INACTIVE" 1 "ACTIVE" 2 "RESERVED" 3 "NOT_AVAILABLE" ;
VAL_ 2566907937 LongLifeEgOilFiltConfig 0 "INACTIVE" 1 "ACTIVE" 2 "RESERVED" 3 "NOT_AVAILABLE" ;
VAL_ 2566907937 ElecStrJoyThwConf 0 "INACTIVE" 1 "ACTIVE" 2 "RESERVED" 3 "NOT_AVAILABLE" ;
VAL_ 2566907937 Dl06EgFuelEffCalbConf 0 "INACTIVE" 1 "ACTIVE" 2 "RESERVED" 3 "NOT_AVAILABLE" ;
VAL_ 2566907937 RttThwDirConf 0 "INACTIVE" 1 "ACTIVE" 2 "RESERVED" 3 "NOT_AVAILABLE" ;
VAL_ 2566907937 TwThwDirConf 0 "INACTIVE" 1 "ACTIVE" 2 "RESERVED" 3 "NOT_AVAILABLE" ;
VAL_ 2566907937 CanPdlIntChngConf 0 "INACTIVE" 1 "ACTIVE" 2 "RESERVED" 3 "NOT_AVAILABLE" ;
VAL_ 2566907937 TrvlSwgAlmIntChngConf 0 "INACTIVE" 1 "ACTIVE" 2 "RESERVED" 3 "NOT_AVAILABLE" ;
VAL_ 2566907937 OprHrTmpIntChngConf 0 "INACTIVE" 1 "ACTIVE" 2 "RESERVED" 3 "NOT_AVAILABLE" ;
VAL_ 2566907937 QckCouplerIntChngConf 0 "INACTIVE" 1 "ACTIVE" 2 "RESERVED" 3 "NOT_AVAILABLE" ;
VAL_ 2566907937 ThwSensConf 0 "INACTIVE" 1 "ACTIVE" 2 "RESERVED" 3 "NOT_AVAILABLE" ;
VAL_ 2566907937 MultiFuncJoyBtnConf 0 "INACTIVE" 1 "ACTIVE" 2 "RESERVED" 3 "NOT_AVAILABLE" ;
VAL_ 2566908449 TiltRttArg 0 "OFF" 1 "ON" 2 "ERROR" 3 "NOT_AVAILABLE" ;
VAL_ 2566908449 GnssSt 0 "NORMAL" 1 "NOT_FIXED" 2 "RELEASE_ON_GA" 3 "ERROR_EXCEEDED" 4 "GNSS_COMMUNICATION_ERROR" ;
VAL_ 2566908449 VhcStFineSwgTprDsb 0 "OFF" 1 "ON" 2 "ERROR" 3 "NOT_AVAILABLE" ;
VAL_ 2566908449 AssitSwgRh 0 "OFF" 1 "ON" 2 "ERROR" 3 "NOT_AVAILABLE" ;
VAL_ 2566908449 AssitSwgLh 0 "OFF" 1 "ON" 2 "ERROR" 3 "NOT_AVAILABLE" ;
VAL_ 2566908449 AssitBck 0 "OFF" 1 "ON" 2 "ERROR" 3 "NOT_AVAILABLE" ;
VAL_ 2566908449 AssitGrd 0 "OFF" 1 "ON" 2 "ERROR" 3 "NOT_AVAILABLE" ;
VAL_ 2566908449 SafeWrkSideFar 0 "OFF" 1 "ON" 2 "ERROR" 3 "NOT_AVAILABLE" ;
VAL_ 2566908449 SafeWrkSideMid 0 "OFF" 1 "ON" 2 "ERROR" 3 "NOT_AVAILABLE" ;
VAL_ 2566908449 SafeWrkSideNear 0 "OFF" 1 "ON" 2 "ERROR" 3 "NOT_AVAILABLE" ;
VAL_ 2566908449 SafeWrkFrFar 0 "OFF" 1 "ON" 2 "ERROR" 3 "NOT_AVAILABLE" ;
VAL_ 2566908449 SafeWrkFrMid 0 "OFF" 1 "ON" 2 "ERROR" 3 "NOT_AVAILABLE" ;
VAL_ 2566908449 SafeWrkFrNear 0 "OFF" 1 "ON" 2 "ERROR" 3 "NOT_AVAILABLE" ;
VAL_ 2566908449 FrMvGuidArmOut 0 "OFF" 1 "ON" 2 "ERROR" 3 "NOT_AVAILABLE" ;
VAL_ 2566908449 FrMvGuidArmIn 0 "OFF" 1 "ON" 2 "ERROR" 3 "NOT_AVAILABLE" ;
VAL_ 2566908449 FrMvGuidBoomDn 0 "OFF" 1 "ON" 2 "ERROR" 3 "NOT_AVAILABLE" ;
VAL_ 2566908449 FrMvGuidBoomUp 0 "GREEN" 1 "YELLOW" 2 "RED" ;
VAL_ 2566908449 EfenceTrkWrn 0 "OFF" 1 "ON" 2 "ACTIVE" 3 "RESERVED" ;
VAL_ 2566908449 EfenceDzWrn 0 "OFF" 1 "ON" 2 "ACTIVE" 3 "RESERVED" ;
VAL_ 2566908449 EfenceCabWrn 0 "OFF" 1 "ON" 2 "ACTIVE" 3 "RESERVED" ;
VAL_ 2566908449 EfenceFSwgRhWrn 0 "OFF" 1 "ON" 2 "ACTIVE" 3 "RESERVED" ;
VAL_ 2566908449 EfenceFSwgLhWrn 0 "OFF" 1 "ON" 2 "ACTIVE" 3 "RESERVED" ;
VAL_ 2566908449 EfenceCeilWrn 0 "OFF" 1 "ON" 2 "ACTIVE" 3 "RESERVED" ;
VAL_ 2566908449 EfenceFloorWrn 0 "OFF" 1 "ON" 2 "ACTIVE" 3 "RESERVED" ;
VAL_ 2566908449 EfenceWallWrn 0 "OFF" 1 "ON" 2 "ACTIVE" 3 "RESERVED" ;
VAL_ 2566908705 TipOffMnSt 0 "OFF" 1 "DISABLE" 2 "READY" 3 "IN_PROGRESS" ;
VAL_ 2566908705 TipOffAstSt 0 "OFF" 1 "DISABLE" 2 "WAIT" 3 "READY" 4 "IN_PROGRESS" 5 "COMPLETE" 6 "INTERUPT" ;
VAL_ 2566908705 WghCntSt 0 "OFF" 1 "CANCEL" 2 "RETURN" 3 "NOT_DEFINED" ;
VAL_ 2566908705 WghSt 0 "READY" 1 "ESTIMATE" 2 "CONFIRM" 3 "COMPLETE" 4 "ESTIMATE_TRUCK_TIP_OFF" 5 "CONFIRM_TRUCK_TIP_OFF" ;
VAL_ 2566908961 EmcvCalbStep 0 "READY" 1 "STEP0" 2 "STEP1" 3 "STEP2" 4 "STEP3" 5 "STEP4" 6 "STEP5" 7 "STEP6" 8 "STEP7" 9 "STEP8" 10 "STEP9" 11 "STEP10" 12 "STEP11" 13 "STEP12" 14 "STEP13" 15 "STEP14" ;
VAL_ 2566908961 EmcvCalbStage 0 "RESERVED" 1 "STAGE_0" 2 "STAGE_1" 3 "STAGE_2" 4 "STAGE_3" 5 "STAGE_4" 6 "STAGE_5" 7 "STAGE_6" 8 "STAGE_7" 9 "STAGE_8" 10 "STAGE_9" 11 "STAGE_10" 12 "STAGE_11" 13 "LAST_STAGE_CONFIRM" 14 "SUCCESS" 15 "ERROR" ;
VAL_ 2566908961 BckSingleFastCalbStep 0 "READY" 1 "STEP0" 2 "STEP1" 3 "STEP2" 4 "STEP3" 5 "STEP4" 6 "STEP5" 7 "STEP6" 8 "STEP7" 9 "STEP8" 10 "STEP9" 11 "STEP10" 12 "STEP11" 13 "STEP12" 14 "STEP13" 15 "STEP14" ;
VAL_ 2566908961 BckSingleFastCalbStage 0 "RESERVED" 1 "STAGE_0" 2 "STAGE_1" 3 "STAGE_2" 4 "STAGE_3" 5 "STAGE_4" 6 "STAGE_5" 7 "STAGE_6" 8 "STAGE_7" 9 "STAGE_8" 10 "STAGE_9" 11 "STAGE_10" 12 "STAGE_11" 13 "LAST_STAGE_CONFIRM" 14 "SUCCESS" 15 "ERROR" ;
VAL_ 2566908961 BckSingleSlowCalbStep 0 "READY" 1 "STEP0" 2 "STEP1" 3 "STEP2" 4 "STEP3" 5 "STEP4" 6 "STEP5" 7 "STEP6" 8 "STEP7" 9 "STEP8" 10 "STEP9" 11 "STEP10" 12 "STEP11" 13 "STEP12" 14 "STEP13" 15 "STEP14" ;
VAL_ 2566908961 BckSingleSlowCalbStage 0 "RESERVED" 1 "STAGE_0" 2 "STAGE_1" 3 "STAGE_2" 4 "STAGE_3" 5 "STAGE_4" 6 "STAGE_5" 7 "STAGE_6" 8 "STAGE_7" 9 "STAGE_8" 10 "STAGE_9" 11 "STAGE_10" 12 "STAGE_11" 13 "LAST_STAGE_CONFIRM" 14 "SUCCESS" 15 "ERROR" ;
VAL_ 2566908961 BckZeroCalbStep 0 "READY" 1 "STEP0" 2 "STEP1" 3 "STEP2" 4 "STEP3" 5 "STEP4" 6 "STEP5" 7 "STEP6" 8 "STEP7" 9 "STEP8" 10 "STEP9" 11 "STEP10" 12 "STEP11" 13 "STEP12" 14 "STEP13" 15 "STEP14" ;
VAL_ 2566908961 BckZeroCalbStage 0 "RESERVED" 1 "STAGE_0" 2 "STAGE_1" 3 "STAGE_2" 4 "STAGE_3" 5 "STAGE_4" 6 "STAGE_5" 7 "STAGE_6" 8 "STAGE_7" 9 "STAGE_8" 10 "STAGE_9" 11 "STAGE_10" 12 "STAGE_11" 13 "LAST_STAGE_CONFIRM" 14 "SUCCESS" 15 "ERROR" ;
VAL_ 2566908961 FrMultiCalbStep 0 "READY" 1 "STEP0" 2 "STEP1" 3 "STEP2" 4 "STEP3" 5 "STEP4" 6 "STEP5" 7 "STEP6" 8 "STEP7" 9 "STEP8" 10 "STEP9" 11 "STEP10" 12 "STEP11" 13 "STEP12" 14 "STEP13" 15 "STEP14" ;
VAL_ 2566908961 FrMultiCalbStage 0 "RESERVED" 1 "STAGE_0" 2 "STAGE_1" 3 "STAGE_2" 4 "STAGE_3" 5 "STAGE_4" 6 "STAGE_5" 7 "STAGE_6" 8 "STAGE_7" 9 "STAGE_8" 10 "STAGE_9" 11 "STAGE_10" 12 "STAGE_11" 13 "LAST_STAGE_CONFIRM" 14 "SUCCESS" 15 "ERROR" ;
VAL_ 2566908961 FrSngCalbStep 0 "READY" 1 "STEP0" 2 "STEP1" 3 "STEP2" 4 "STEP3" 5 "STEP4" 6 "STEP5" 7 "STEP6" 8 "STEP7" 9 "STEP8" 10 "STEP9" 11 "STEP10" 12 "STEP11" 13 "STEP12" 14 "STEP13" 15 "STEP14" ;
VAL_ 2566908961 FrSngCalbStage 0 "RESERVED" 1 "STAGE_0" 2 "STAGE_1" 3 "STAGE_2" 4 "STAGE_3" 5 "STAGE_4" 6 "STAGE_5" 7 "STAGE_6" 8 "STAGE_7" 9 "STAGE_8" 10 "STAGE_9" 11 "STAGE_10" 12 "STAGE_11" 13 "LAST_STAGE_CONFIRM" 14 "SUCCESS" 15 "ERROR" ;
VAL_ 2566910241 SwgSt 0 "STOP" 1 "SWING" 2 "ERROR" 3 "NOT_AVAILABLE" ;
VAL_ 2566912801 JoyFuncAssnRhThw05 0 "NOT_USED" 1 "TR_TILT" 2 "TR_ROTATE" 10 "SHARE" 11 "ROTATE" 13 "DOZER" ;
VAL_ 2566912801 JoyFuncAssnRhThw04 0 "NOT_USED" 1 "TR_TILT" 2 "TR_ROTATE" 10 "SHARE" 11 "ROTATE" 13 "DOZER" ;
VAL_ 2566912801 JoyFuncAssnRhThw03 0 "NOT_USED" 1 "TR_TILT" 2 "TR_ROTATE" 10 "SHARE" 11 "ROTATE" 13 "DOZER" ;
VAL_ 2566912801 JoyFuncAssnRhThw02 0 "NOT_USED" 1 "TR_TILT" 2 "TR_ROTATE" 10 "SHARE" 11 "ROTATE" 13 "DOZER" ;
VAL_ 2566912801 JoyFuncAssnRhThw01 0 "NOT_USED" 1 "TR_TILT" 2 "TR_ROTATE" 10 "SHARE" 11 "ROTATE" 13 "DOZER" ;
VAL_ 2566912801 JoyFuncAssnLhThw05 0 "NOT_USED" 1 "TR_TILT" 2 "TR_ROTATE" 10 "SHARE" 11 "ROTATE" 13 "DOZER" ;
VAL_ 2566912801 JoyFuncAssnLhThw04 0 "NOT_USED" 1 "TR_TILT" 2 "TR_ROTATE" 10 "SHARE" 11 "ROTATE" 13 "DOZER" ;
VAL_ 2566912801 JoyFuncAssnLhThw03 0 "NOT_USED" 1 "TR_TILT" 2 "TR_ROTATE" 10 "SHARE" 11 "ROTATE" 13 "DOZER" ;
VAL_ 2566912801 JoyFuncAssnLhThw02 0 "NOT_USED" 1 "TR_TILT" 2 "TR_ROTATE" 10 "SHARE" 11 "ROTATE" 13 "DOZER" ;
VAL_ 2566912801 JoyFuncAssnLhThw01 0 "NOT_USED" 1 "TR_TILT" 2 "TR_ROTATE" 10 "SHARE" 11 "ROTATE" 13 "DOZER" ;
VAL_ 2566912801 JoyFuncAssnRhBtn10 0 "NOT_USED" 1 "ONE_TOUCH_DECELERATION" 2 "BREAKER_OR_POWER_UP" 3 "TEMP_RESET_OF_INTEL_FLOAT_BOOM" 4 "WIPER" 5 "AUDIO_MUTE" 11 "WEIGHT_MEASUREMENT_ON_OFF" 12 "RE_MEASURE" 13 "CANCEL_BUCKET" 14 "LOAD_BUCKET" 15 "SAVE_TRUCK" 16 "RESET_TRUCK" 41 "SMART_BREAKER_ON_OFF" 43 "JOYSTICK_DRIVING_ON_OFF" ;
VAL_ 2566912801 JoyFuncAssnRhBtn09 0 "NOT_USED" 1 "ONE_TOUCH_DECELERATION" 2 "BREAKER_OR_POWER_UP" 3 "TEMP_RESET_OF_INTEL_FLOAT_BOOM" 4 "WIPER" 5 "AUDIO_MUTE" 11 "WEIGHT_MEASUREMENT_ON_OFF" 12 "RE_MEASURE" 13 "CANCEL_BUCKET" 14 "LOAD_BUCKET" 15 "SAVE_TRUCK" 16 "RESET_TRUCK" 41 "SMART_BREAKER_ON_OFF" 43 "JOYSTICK_DRIVING_ON_OFF" ;
VAL_ 2566912801 JoyFuncAssnRhBtn08 0 "NOT_USED" 1 "ONE_TOUCH_DECELERATION" 2 "BREAKER_OR_POWER_UP" 3 "TEMP_RESET_OF_INTEL_FLOAT_BOOM" 4 "WIPER" 5 "AUDIO_MUTE" 11 "WEIGHT_MEASUREMENT_ON_OFF" 12 "RE_MEASURE" 13 "CANCEL_BUCKET" 14 "LOAD_BUCKET" 15 "SAVE_TRUCK" 16 "RESET_TRUCK" 41 "SMART_BREAKER_ON_OFF" 43 "JOYSTICK_DRIVING_ON_OFF" ;
VAL_ 2566912801 JoyFuncAssnRhBtn07 0 "NOT_USED" 1 "ONE_TOUCH_DECELERATION" 2 "BREAKER_OR_POWER_UP" 3 "TEMP_RESET_OF_INTEL_FLOAT_BOOM" 4 "WIPER" 5 "AUDIO_MUTE" 11 "WEIGHT_MEASUREMENT_ON_OFF" 12 "RE_MEASURE" 13 "CANCEL_BUCKET" 14 "LOAD_BUCKET" 15 "SAVE_TRUCK" 16 "RESET_TRUCK" 41 "SMART_BREAKER_ON_OFF" 43 "JOYSTICK_DRIVING_ON_OFF" ;
VAL_ 2566912801 JoyFuncAssnRhBtn06 0 "NOT_USED" 1 "ONE_TOUCH_DECELERATION" 2 "BREAKER_OR_POWER_UP" 3 "TEMP_RESET_OF_INTEL_FLOAT_BOOM" 4 "WIPER" 5 "AUDIO_MUTE" 11 "WEIGHT_MEASUREMENT_ON_OFF" 12 "RE_MEASURE" 13 "CANCEL_BUCKET" 14 "LOAD_BUCKET" 15 "SAVE_TRUCK" 16 "RESET_TRUCK" 41 "SMART_BREAKER_ON_OFF" 43 "JOYSTICK_DRIVING_ON_OFF" ;
VAL_ 2566912801 JoyFuncAssnRhBtn05 0 "NOT_USED" 1 "ONE_TOUCH_DECELERATION" 2 "BREAKER_OR_POWER_UP" 3 "TEMP_RESET_OF_INTEL_FLOAT_BOOM" 4 "WIPER" 5 "AUDIO_MUTE" 11 "WEIGHT_MEASUREMENT_ON_OFF" 12 "RE_MEASURE" 13 "CANCEL_BUCKET" 14 "LOAD_BUCKET" 15 "SAVE_TRUCK" 16 "RESET_TRUCK" 41 "SMART_BREAKER_ON_OFF" 43 "JOYSTICK_DRIVING_ON_OFF" ;
VAL_ 2566912801 JoyFuncAssnRhBtn04 0 "NOT_USED" 1 "ONE_TOUCH_DECELERATION" 2 "BREAKER_OR_POWER_UP" 3 "TEMP_RESET_OF_INTEL_FLOAT_BOOM" 4 "WIPER" 5 "AUDIO_MUTE" 11 "WEIGHT_MEASUREMENT_ON_OFF" 12 "RE_MEASURE" 13 "CANCEL_BUCKET" 14 "LOAD_BUCKET" 15 "SAVE_TRUCK" 16 "RESET_TRUCK" 41 "SMART_BREAKER_ON_OFF" 43 "JOYSTICK_DRIVING_ON_OFF" ;
VAL_ 2566912801 JoyFuncAssnRhBtn03 0 "NOT_USED" 1 "ONE_TOUCH_DECELERATION" 2 "BREAKER_OR_POWER_UP" 3 "TEMP_RESET_OF_INTEL_FLOAT_BOOM" 4 "WIPER" 5 "AUDIO_MUTE" 11 "WEIGHT_MEASUREMENT_ON_OFF" 12 "RE_MEASURE" 13 "CANCEL_BUCKET" 14 "LOAD_BUCKET" 15 "SAVE_TRUCK" 16 "RESET_TRUCK" 41 "SMART_BREAKER_ON_OFF" 43 "JOYSTICK_DRIVING_ON_OFF" ;
VAL_ 2566912801 JoyFuncAssnRhBtn02 0 "NOT_USED" 1 "ONE_TOUCH_DECELERATION" 2 "BREAKER_OR_POWER_UP" 3 "TEMP_RESET_OF_INTEL_FLOAT_BOOM" 4 "WIPER" 5 "AUDIO_MUTE" 11 "WEIGHT_MEASUREMENT_ON_OFF" 12 "RE_MEASURE" 13 "CANCEL_BUCKET" 14 "LOAD_BUCKET" 15 "SAVE_TRUCK" 16 "RESET_TRUCK" 41 "SMART_BREAKER_ON_OFF" 43 "JOYSTICK_DRIVING_ON_OFF" ;
VAL_ 2566912801 JoyFuncAssnRhBtn01 0 "NOT_USED" 1 "ONE_TOUCH_DECELERATION" 2 "BREAKER_OR_POWER_UP" 3 "TEMP_RESET_OF_INTEL_FLOAT_BOOM" 4 "WIPER" 5 "AUDIO_MUTE" 11 "WEIGHT_MEASUREMENT_ON_OFF" 12 "RE_MEASURE" 13 "CANCEL_BUCKET" 14 "LOAD_BUCKET" 15 "SAVE_TRUCK" 16 "RESET_TRUCK" 41 "SMART_BREAKER_ON_OFF" 43 "JOYSTICK_DRIVING_ON_OFF" ;
VAL_ 2566912801 JoyFuncAssnLhBtn10 0 "NOT_USED" 1 "ONE_TOUCH_DECELERATION" 2 "BREAKER_OR_POWER_UP" 3 "TEMP_RESET_OF_INTEL_FLOAT_BOOM" 4 "WIPER" 5 "AUDIO_MUTE" 11 "WEIGHT_MEASUREMENT_ON_OFF" 12 "RE_MEASURE" 13 "CANCEL_BUCKET" 14 "LOAD_BUCKET" 15 "SAVE_TRUCK" 16 "RESET_TRUCK" 41 "SMART_BREAKER_ON_OFF" 43 "JOYSTICK_DRIVING_ON_OFF" ;
VAL_ 2566912801 JoyFuncAssnLhBtn09 0 "NOT_USED" 1 "ONE_TOUCH_DECELERATION" 2 "BREAKER_OR_POWER_UP" 3 "TEMP_RESET_OF_INTEL_FLOAT_BOOM" 4 "WIPER" 5 "AUDIO_MUTE" 11 "WEIGHT_MEASUREMENT_ON_OFF" 12 "RE_MEASURE" 13 "CANCEL_BUCKET" 14 "LOAD_BUCKET" 15 "SAVE_TRUCK" 16 "RESET_TRUCK" 41 "SMART_BREAKER_ON_OFF" 43 "JOYSTICK_DRIVING_ON_OFF" ;
VAL_ 2566912801 JoyFuncAssnLhBtn08 0 "NOT_USED" 1 "ONE_TOUCH_DECELERATION" 2 "BREAKER_OR_POWER_UP" 3 "TEMP_RESET_OF_INTEL_FLOAT_BOOM" 4 "WIPER" 5 "AUDIO_MUTE" 11 "WEIGHT_MEASUREMENT_ON_OFF" 12 "RE_MEASURE" 13 "CANCEL_BUCKET" 14 "LOAD_BUCKET" 15 "SAVE_TRUCK" 16 "RESET_TRUCK" 41 "SMART_BREAKER_ON_OFF" 43 "JOYSTICK_DRIVING_ON_OFF" ;
VAL_ 2566912801 JoyFuncAssnLhBtn07 0 "NOT_USED" 1 "ONE_TOUCH_DECELERATION" 2 "BREAKER_OR_POWER_UP" 3 "TEMP_RESET_OF_INTEL_FLOAT_BOOM" 4 "WIPER" 5 "AUDIO_MUTE" 11 "WEIGHT_MEASUREMENT_ON_OFF" 12 "RE_MEASURE" 13 "CANCEL_BUCKET" 14 "LOAD_BUCKET" 15 "SAVE_TRUCK" 16 "RESET_TRUCK" 41 "SMART_BREAKER_ON_OFF" 43 "JOYSTICK_DRIVING_ON_OFF" ;
VAL_ 2566912801 JoyFuncAssnLhBtn06 0 "NOT_USED" 1 "ONE_TOUCH_DECELERATION" 2 "BREAKER_OR_POWER_UP" 3 "TEMP_RESET_OF_INTEL_FLOAT_BOOM" 4 "WIPER" 5 "AUDIO_MUTE" 11 "WEIGHT_MEASUREMENT_ON_OFF" 12 "RE_MEASURE" 13 "CANCEL_BUCKET" 14 "LOAD_BUCKET" 15 "SAVE_TRUCK" 16 "RESET_TRUCK" 41 "SMART_BREAKER_ON_OFF" 43 "JOYSTICK_DRIVING_ON_OFF" ;
VAL_ 2566912801 JoyFuncAssnLhBtn05 0 "NOT_USED" 1 "ONE_TOUCH_DECELERATION" 2 "BREAKER_OR_POWER_UP" 3 "TEMP_RESET_OF_INTEL_FLOAT_BOOM" 4 "WIPER" 5 "AUDIO_MUTE" 11 "WEIGHT_MEASUREMENT_ON_OFF" 12 "RE_MEASURE" 13 "CANCEL_BUCKET" 14 "LOAD_BUCKET" 15 "SAVE_TRUCK" 16 "RESET_TRUCK" 41 "SMART_BREAKER_ON_OFF" 43 "JOYSTICK_DRIVING_ON_OFF" ;
VAL_ 2566912801 JoyFuncAssnLhBtn04 0 "NOT_USED" 1 "ONE_TOUCH_DECELERATION" 2 "BREAKER_OR_POWER_UP" 3 "TEMP_RESET_OF_INTEL_FLOAT_BOOM" 4 "WIPER" 5 "AUDIO_MUTE" 11 "WEIGHT_MEASUREMENT_ON_OFF" 12 "RE_MEASURE" 13 "CANCEL_BUCKET" 14 "LOAD_BUCKET" 15 "SAVE_TRUCK" 16 "RESET_TRUCK" 41 "SMART_BREAKER_ON_OFF" 43 "JOYSTICK_DRIVING_ON_OFF" ;
VAL_ 2566912801 JoyFuncAssnLhBtn03 0 "NOT_USED" 1 "ONE_TOUCH_DECELERATION" 2 "BREAKER_OR_POWER_UP" 3 "TEMP_RESET_OF_INTEL_FLOAT_BOOM" 4 "WIPER" 5 "AUDIO_MUTE" 11 "WEIGHT_MEASUREMENT_ON_OFF" 12 "RE_MEASURE" 13 "CANCEL_BUCKET" 14 "LOAD_BUCKET" 15 "SAVE_TRUCK" 16 "RESET_TRUCK" 41 "SMART_BREAKER_ON_OFF" 43 "JOYSTICK_DRIVING_ON_OFF" ;
VAL_ 2566912801 JoyFuncAssnLhBtn02 0 "NOT_USED" 1 "ONE_TOUCH_DECELERATION" 2 "BREAKER_OR_POWER_UP" 3 "TEMP_RESET_OF_INTEL_FLOAT_BOOM" 4 "WIPER" 5 "AUDIO_MUTE" 11 "WEIGHT_MEASUREMENT_ON_OFF" 12 "RE_MEASURE" 13 "CANCEL_BUCKET" 14 "LOAD_BUCKET" 15 "SAVE_TRUCK" 16 "RESET_TRUCK" 41 "SMART_BREAKER_ON_OFF" 43 "JOYSTICK_DRIVING_ON_OFF" ;
VAL_ 2566912801 JoyFuncAssnLhBtn01 0 "NOT_USED" 1 "ONE_TOUCH_DECELERATION" 2 "BREAKER_OR_POWER_UP" 3 "TEMP_RESET_OF_INTEL_FLOAT_BOOM" 4 "WIPER" 5 "AUDIO_MUTE" 11 "WEIGHT_MEASUREMENT_ON_OFF" 12 "RE_MEASURE" 13 "CANCEL_BUCKET" 14 "LOAD_BUCKET" 15 "SAVE_TRUCK" 16 "RESET_TRUCK" 41 "SMART_BREAKER_ON_OFF" 43 "JOYSTICK_DRIVING_ON_OFF" ;
VAL_ 2566913569 MaterialLoadSt 0 "IN_PROGRESS" 1 "COMPLETE" ;
VAL_ 2583642954 SelType 0 "NONE" 1 "FOB" 2 "DIGITAL_KEY" 3 "KEYLESS" 4 "REMOTE" ;
VAL_ 2583642186 MpSt 0 "FALSE" 1 "TRUE" 2 "ERROR" 3 "NOT_AVAILABLE" ;
VAL_ 2583662698 WarnPopPhmSwgMot 0 "OFF" 1 "WARNING_LEVEL1" 2 "WARNING_LEVEL2" ;
VAL_ 2583662698 WarnPopPhm2ndSwgRedGr 0 "OFF" 1 "WARNING_LEVEL1" 2 "WARNING_LEVEL2" ;
VAL_ 2583662698 WarnPopPhm1stSwgRedGr 0 "OFF" 1 "WARNING_LEVEL1" 2 "WARNING_LEVEL2" ;
VAL_ 2583662698 WarnPopMainPmp 0 "OFF" 1 "WARNING_LEVEL1" 2 "WARNING_LEVEL2" ;
VAL_ 2583662698 WarnPopEgOilQual 0 "OFF" 1 "WARNING_LEVEL1" 2 "WARNING_LEVEL2" ;
VAL_ 2583662698 WarnPopHyhOilQual 0 "OFF" 1 "WARNING_LEVEL1" 2 "WARNING_LEVEL2" ;
VAL_ 2583663393 StickStrType 0 "JOYSTICK_LEVER" 1 "THUMBWHEEL_STEERING" ;
VAL_ 2583663393 StickStr 0 "DISABLE" 1 "ENABLE" ;
VAL_ 2583663393 JoyPtnChange 0 "ISO" 1 "BHL" 2 "MHI" 3 "KOBE" 4 "SCM" 5 "CTL ISO" 6 "CTL H" ;
VAL_ 2634015777 ReqCd 0 "COMPARE_VHC_TYPE_ID" 10 "REPROGRAMMED_VHC_TYPE_ID" 3 "BLOCK_HANDLER" 4 "LOG_LOADER" ;
VAL_ 2634015777 MaxGrLmt 0 "3RD_GEAR_LIMIT_4TH_TRANSMISSION" 1 "3RD_GEAR_LIMIT_5TH_TRANSMISSION" 2 "4TH_GEAR" 3 "5TH_GEAR_LOCK_UP" 4 "CVT" ;
VAL_ 2634015777 EmsCtrl 0 "TIER2" 1 "TIER3" 2 "TIER4I" 3 "TIER4F" 4 "STAGEV" 5 "NR4" 128 "NOT_AVAILABLE" ;
VAL_ 2634015777 MchGenr 128 "DL" 129 "H" 130 "K" 131 "S" 132 "SD" 133 "G" ;
VAL_ 2634016259 ResultCd 0 "VHC_TYPE_ID_IDENTICAL" 1 "VHC_TYPE_ID_DIFFERENT" 10 "REQUEST_ID_REPROGRAMMED" 11 "REQUEST_ID_NOT_AVAILABLE" 20 "TCI_ID_MESSAGE_REQUIRED" ;
VAL_ 2634016259 MaxGrLmt 0 "3RD_GEAR_LIMIT_4TH_TRANSMISSION" 1 "3RD_GEAR_LIMIT_5TH_TRANSMISSION" 2 "4TH_GEAR" 3 "5TH_GEAR_LOCK_UP" 4 "CVT" ;
VAL_ 2634016259 EmsCtrl 0 "TIER2" 1 "TIER3" 2 "TIER4I" 3 "TIER4F" 4 "STAGEV" 5 "NR4" 128 "NOT_AVAILABLE" ;
VAL_ 2634016259 MchGenr 128 "DL" 129 "H" 130 "K" 131 "S" 132 "SD" 133 "G" ;
